VERSION ""

NS_ :

BS_:

BU_: PKP_PRND_Keypad HVAC Compressor_HPP DCDC_Inmotion_DC2 SME VCCU SME_4 SME_3 SME_2 SME_1 Diag_Tester BMS DCDC_inmotion_DC1 TCU Praker_GW OBC_Dilong DCDC_Dilong VCU

BO_ 2566861442 VCVCCU_V2G_RemainTimeToBulkSOC: 5 VCU
 SG_ RemainingTimeToBulkSOCFlag : 32|8@1+ (1,0) [0|255] "" Vector__XXX
 SG_ RemainingTimeToBulkSOC_Value : 24|8@1- (1,0) [-128|127] "" Vector__XXX
 SG_ RemainTimeToBulkSOC_UnitFlag : 16|8@1+ (1,0) [0|255] "" Vector__XXX
 SG_ RemainingTimeToBulkSOC_Unit : 8|4@1+ (1,0) [0|15] "" Vector__XXX
 SG_ RemainTimeToBulkSOC_Multiplier : 0|8@1- (1,0) [-128|127] "" Vector__XXX

BO_ 2566873730 VCVCCU_LIN_EvStatus: 5 VCU
 SG_ LIN_EvRequestedCurrentL1 : 32|8@1+ (1,0) [0|255] "A" Vector__XXX
 SG_ LIN_EvRequestedCurrentL3 : 24|8@1+ (1,0) [0|255] "A" Vector__XXX
 SG_ LIN_EvRequestedCurrentL2 : 16|8@1+ (1,0) [0|255] "A" Vector__XXX
 SG_ LIN_EvRequestedCurrentL1 : 8|8@1+ (1,0) [0|255] "A" Vector__XXX
 SG_ LIN_EvAwake : 0|1@1+ (1,0) [0|1] "" Vector__XXX

BO_ 2566873986 VCVCCU_LIN_EvPresentCurrentList: 4 VCU
 SG_ LIN_EvPresentCurrentN : 24|8@1+ (1,0) [0|255] "A" Vector__XXX
 SG_ LIN_EvPresentCurrentL3 : 16|8@1+ (1,0) [0|255] "A" Vector__XXX
 SG_ LIN_EvPresentCurrentL2 : 8|8@1+ (1,0) [0|255] "A" Vector__XXX
 SG_ LIN_EvPresentCurrentL1 : 0|8@1+ (1,0) [0|255] "A" Vector__XXX

BO_ 2566875010 VCVCCU_LIN_EvMinVoltageList: 4 VCU
 SG_ LIN_EvMinVoltageL1N : 16|16@1+ (0.1,0) [0|6553.5] "V" Vector__XXX
 SG_ LIN_EvMinVoltageL1N : 0|16@1+ (0.1,0) [0|6553.5] "V" Vector__XXX

BO_ 2566874754 VCVCCU_LIN_EvMaxVoltageList: 5 VCU
 SG_ LIN_EvMaxVoltageLL : 24|16@1+ (0.1,0) [0|6553.5] "V" Vector__XXX
 SG_ LIN_EvMaxVoltageL1N : 8|16@1+ (0.1,0) [0|6553.5] "V" Vector__XXX
 SG_ LIN_EvFrequencies : 0|8@1+ (1,0) [0|255] "" Vector__XXX

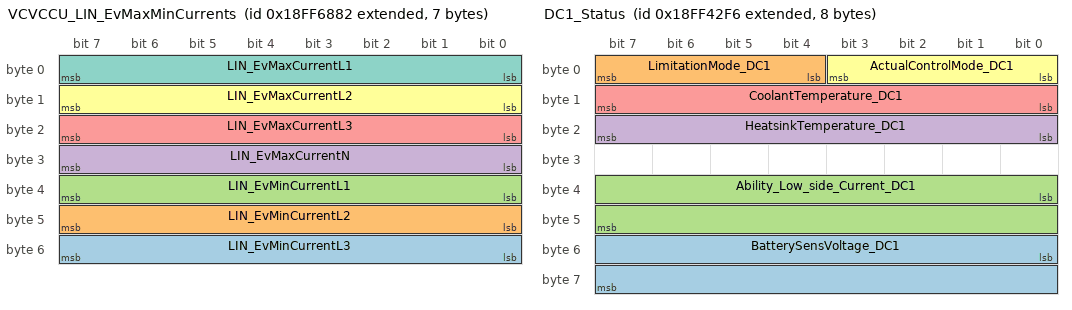
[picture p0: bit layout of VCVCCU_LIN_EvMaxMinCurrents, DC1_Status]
BO_ 2566875266 VCVCCU_LIN_EvMaxMinCurrents: 7 VCU
 SG_ LIN_EvMinCurrentL3 : 48|8@1+ (1,0) [0|255] "A" Vector__XXX
 SG_ LIN_EvMinCurrentL2 : 40|8@1+ (1,0) [0|255] "A" Vector__XXX
 SG_ LIN_EvMinCurrentL1 : 32|8@1+ (1,0) [0|255] "A" Vector__XXX
 SG_ LIN_EvMaxCurrentN : 24|8@1+ (1,0) [0|255] "A" Vector__XXX
 SG_ LIN_EvMaxCurrentL3 : 16|8@1+ (1,0) [0|255] "A" Vector__XXX
 SG_ LIN_EvMaxCurrentL2 : 8|8@1+ (1,0) [0|255] "A" Vector__XXX
 SG_ LIN_EvMaxCurrentL1 : 0|8@1+ (1,0) [0|255] "A" Vector__XXX

BO_ 2363117696 DIAG_RESP_VCVCCU: 8 VCCU
 SG_ DIAG_RESP_VCVCCU : 0|64@1+ (1,0) [0|1.84467440737096E+019] "" Vector__XXX

BO_ 2363129986 DIAG_REQ_VCVCCU: 8 VCU
 SG_ DIAG_REQ_VCVCCU : 0|64@1+ (1,0) [0|1.84467440737096E+019] "" Vector__XXX

BO_ 2363228034 DIAG_REQ_GLOBAL: 8 VCU
 SG_ DIAG_REQ_GLOBAL : 0|64@1+ (1,0) [0|1.84467440737096E+019] "" Vector__XXX

BO_ 2566865654 DC1_Status: 8 DCDC_inmotion_DC1
 SG_ BatterySensVoltage_DC1 : 48|16@1+ (0.05,0) [0|3212.7] "volts" Vector__XXX
 SG_ LimitationMode_DC1 : 4|4@1+ (1,0) [0|15] "" Vector__XXX
 SG_ Ability_Low_side_Current_DC1 : 32|16@1+ (0.05,-1600) [-1600|1612.75] "A" Vector__XXX
 SG_ HeatsinkTemperature_DC1 : 16|8@1+ (1,-40) [-40|209] "deg. Cel" Vector__XXX
 SG_ CoolantTemperature_DC1 : 8|8@1+ (1,-40) [-40|209] "Deg cel" Vector__XXX
 SG_ ActualControlMode_DC1 : 0|4@1+ (1,0) [0|0] "" Vector__XXX

BO_ 2566865398 DC1_Actual_Message: 8 DCDC_inmotion_DC1
 SG_ ActualHighsideCurrent_DC1 : 48|16@1+ (0.05,-1600) [-1600|1612.75] "Amps" Vector__XXX
 SG_ ActualHighsideVoltage_DC1 : 32|16@1+ (0.05,0) [0|3212.75] "volts" Vector__XXX
 SG_ ActualLowsideCurrent_DC1 : 16|16@1+ (0.05,-1600) [-1600|1612.75] "Amps" Vector__XXX
 SG_ ActualLowsideVoltage_DC1 : 0|16@1+ (0.05,0) [0|3212.75] "volts" Vector__XXX

BO_ 2566866174 DCDC_Faults_Inmotion: 8 DCDC_Inmotion_DC2
 SG_ WarningBit_31 : 63|1@1+ (1,0) [0|1] "" Vector__XXX
 SG_ WarningBit_30 : 62|1@1+ (1,0) [0|1] "" Vector__XXX
 SG_ WarningBit_29 : 61|1@1+ (1,0) [0|1] "" Vector__XXX
 SG_ WarningBit_28 : 60|1@1+ (1,0) [0|1] "" Vector__XXX
 SG_ WarningBit_27 : 59|1@1+ (1,0) [0|1] "" Vector__XXX
 SG_ WarningBit_26 : 58|1@1+ (1,0) [0|1] "" Vector__XXX
 SG_ WarningBit_25 : 57|1@1+ (1,0) [0|1] "" Vector__XXX
 SG_ WarningBit_24 : 56|1@1+ (1,0) [0|1] "" Vector__XXX
 SG_ WarningBit_23 : 55|1@1+ (1,0) [0|1] "" Vector__XXX
 SG_ WarningBit_22 : 54|1@1+ (1,0) [0|1] "" Vector__XXX
 SG_ WarningBit_21 : 53|1@1+ (1,0) [0|1] "" Vector__XXX
 SG_ WarningBit_20 : 52|1@1+ (1,0) [0|1] "" Vector__XXX
 SG_ WarningBit_19 : 51|1@1+ (1,0) [0|1] "" Vector__XXX
 SG_ WarningBit_18 : 50|1@1+ (1,0) [0|1] "" Vector__XXX
 SG_ WarningBit_17 : 49|1@1+ (1,0) [0|1] "" Vector__XXX
 SG_ WarningBit_16 : 48|1@1+ (1,0) [0|1] "" Vector__XXX
 SG_ WarningBit_15 : 47|1@1+ (1,0) [0|1] "" Vector__XXX
 SG_ WarningBit_14 : 46|1@1+ (1,0) [0|1] "" Vector__XXX
 SG_ WarningBit_13 : 45|1@1+ (1,0) [0|1] "" Vector__XXX
 SG_ WarningBit_12 : 44|1@1+ (1,0) [0|1] "" Vector__XXX
 SG_ WarningBit_11 : 43|1@1+ (1,0) [0|1] "" Vector__XXX
 SG_ WarningBit_10 : 42|1@1+ (1,0) [0|1] "" Vector__XXX
 SG_ WarningBit_09 : 41|1@1+ (1,0) [0|1] "" Vector__XXX
 SG_ WarningBit_08 : 40|1@1+ (1,0) [0|1] "" Vector__XXX
 SG_ WarningBit_07 : 39|1@1+ (1,0) [0|1] "" Vector__XXX
 SG_ WarningBit_06 : 38|1@1+ (1,0) [0|1] "" Vector__XXX
 SG_ WarningBit_05 : 37|1@1+ (1,0) [0|1] "" Vector__XXX
 SG_ WarningBit_04 : 36|1@1+ (1,0) [0|1] "" Vector__XXX
 SG_ WarningBit_03 : 35|1@1+ (1,0) [0|1] "" Vector__XXX
 SG_ WarningBit_02 : 34|1@1+ (1,0) [0|1] "" Vector__XXX
 SG_ WarningBit_01 : 33|1@1+ (1,0) [0|1] "" Vector__XXX
 SG_ WarningBit_00 : 32|1@1+ (1,0) [0|1] "" Vector__XXX
 SG_ ErrorBit_31 : 31|1@1+ (1,0) [0|1] "" Vector__XXX
 SG_ ErrorBit_30 : 30|1@1+ (1,0) [0|1] "" Vector__XXX
 SG_ ErrorBit_29 : 29|1@1+ (1,0) [0|1] "" Vector__XXX
 SG_ ErrorBit_28 : 28|1@1+ (1,0) [0|1] "" Vector__XXX
 SG_ ErrorBit_27 : 27|1@1+ (1,0) [0|1] "" Vector__XXX
 SG_ ErrorBit_26 : 26|1@1+ (1,0) [0|1] "" Vector__XXX
 SG_ ErrorBit_25 : 25|1@1+ (1,0) [0|1] "" Vector__XXX
 SG_ ErrorBit_24 : 24|1@1+ (1,0) [0|1] "" Vector__XXX
 SG_ ErrorBit_23 : 23|1@1+ (1,0) [0|1] "" Vector__XXX
 SG_ ErrorBit_22 : 22|1@1+ (1,0) [0|1] "" Vector__XXX
 SG_ ErrorBit_21 : 21|1@1+ (1,0) [0|1] "" Vector__XXX
 SG_ ErrorBit_20 : 20|1@1+ (1,0) [0|1] "" Vector__XXX
 SG_ ErrorBit_19 : 19|1@1+ (1,0) [0|1] "" Vector__XXX
 SG_ ErrorBit_18 : 18|1@1+ (1,0) [0|1] "" Vector__XXX
 SG_ ErrorBit_17 : 17|1@1+ (1,0) [0|1] "" Vector__XXX
 SG_ ErrorBit_16 : 16|1@1+ (1,0) [0|1] "" Vector__XXX
 SG_ ErrorBit_15 : 15|1@1+ (1,0) [0|1] "" Vector__XXX
 SG_ ErrorBit_14 : 14|1@1+ (1,0) [0|1] "" Vector__XXX
 SG_ ErrorBit_13 : 13|1@1+ (1,0) [0|1] "" Vector__XXX
 SG_ ErrorBit_12 : 12|1@1+ (1,0) [0|1] "" Vector__XXX
 SG_ ErrorBit_11 : 11|1@1+ (1,0) [0|1] "" Vector__XXX
 SG_ ErrorBit_10 : 10|1@1+ (1,0) [0|1] "" Vector__XXX
 SG_ ErrorBit_09 : 9|1@1+ (1,0) [0|1] "" Vector__XXX
 SG_ ErrorBit_08 : 8|1@1+ (1,0) [0|1] "" Vector__XXX
 SG_ ErrorBit_07 : 7|1@1+ (1,0) [0|1] "" Vector__XXX
 SG_ ErrorBit_06 : 6|1@1+ (1,0) [0|1] "" Vector__XXX
 SG_ ErrorBit_05 : 5|1@1+ (1,0) [0|1] "" Vector__XXX
 SG_ ErrorBit_04 : 4|1@1+ (1,0) [0|1] "" Vector__XXX
 SG_ ErrorBit_03 : 3|1@1+ (1,0) [0|1] "" Vector__XXX
 SG_ ErrorBit_02 : 2|1@1+ (1,0) [0|1] "" Vector__XXX
 SG_ ErrorBit_01 : 1|1@1+ (1,0) [0|1] "" Vector__XXX
 SG_ ErrorBit_00 : 0|1@1+ (1,0) [0|1] "" Vector__XXX

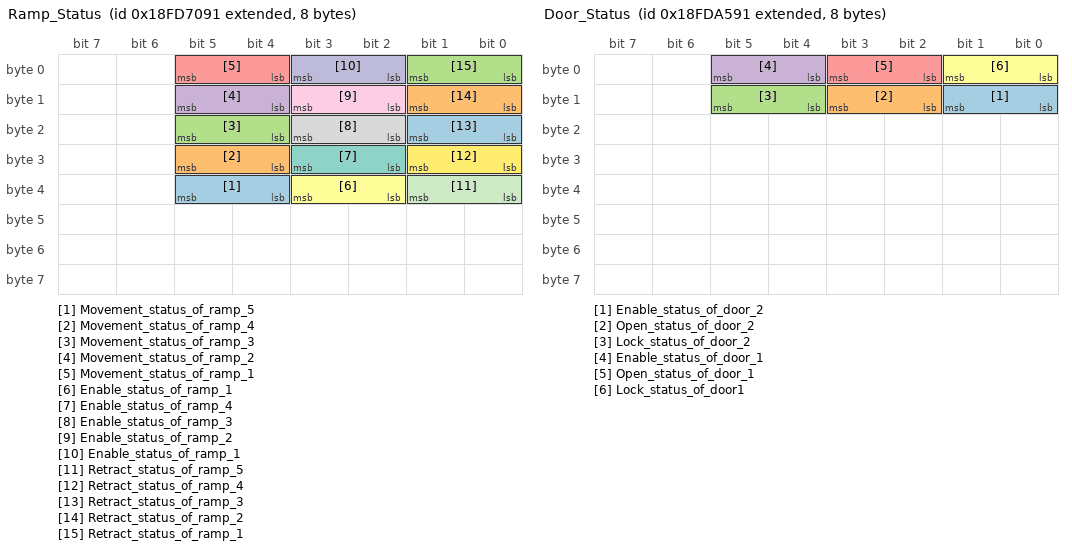
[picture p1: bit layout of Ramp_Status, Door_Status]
BO_ 2566746257 Ramp_Status: 8 Praker_GW
 SG_ Movement_status_of_ramp_5 : 36|2@1+ (1,0) [0|3] "" Vector__XXX
 SG_ Movement_status_of_ramp_4 : 28|2@1+ (1,0) [0|3] "" Vector__XXX
 SG_ Movement_status_of_ramp_3 : 20|2@1+ (1,0) [0|3] "" Vector__XXX
 SG_ Movement_status_of_ramp_2 : 12|2@1+ (1,0) [0|3] "" Vector__XXX
 SG_ Movement_status_of_ramp_1 : 4|2@1+ (1,0) [0|3] "" Vector__XXX
 SG_ Enable_status_of_ramp_1 : 34|2@1+ (1,0) [0|3] "" Vector__XXX
 SG_ Enable_status_of_ramp_4 : 26|2@1+ (1,0) [0|3] "" Vector__XXX
 SG_ Enable_status_of_ramp_3 : 18|2@1+ (1,0) [0|3] "" Vector__XXX
 SG_ Enable_status_of_ramp_2 : 10|2@1+ (1,0) [0|3] "" Vector__XXX
 SG_ Enable_status_of_ramp_1 : 2|2@1+ (1,0) [0|3] "" Vector__XXX
 SG_ Retract_status_of_ramp_5 : 32|2@1+ (1,0) [0|3] "" Vector__XXX
 SG_ Retract_status_of_ramp_4 : 24|2@1+ (1,0) [0|3] "" Vector__XXX
 SG_ Retract_status_of_ramp_3 : 16|2@1+ (1,0) [0|3] "" Vector__XXX
 SG_ Retract_status_of_ramp_2 : 8|2@1+ (1,0) [0|3] "" Vector__XXX
 SG_ Retract_status_of_ramp_1 : 0|2@1+ (1,0) [0|3] "" Vector__XXX

BO_ 2566759825 Door_Status: 8 Praker_GW
 SG_ Enable_status_of_door_2 : 8|2@1+ (1,0) [0|3] "" Vector__XXX
 SG_ Open_status_of_door_2 : 10|2@1+ (1,0) [0|3] "" Vector__XXX
 SG_ Lock_status_of_door_2 : 12|2@1+ (1,0) [0|3] "" Vector__XXX
 SG_ Enable_status_of_door_1 : 4|2@1+ (1,0) [0|3] "" Vector__XXX
 SG_ Open_status_of_door_1 : 2|2@1+ (1,0) [0|3] "" Vector__XXX
 SG_ Lock_status_of_door1 : 0|2@1+ (1,0) [0|3] "" Vector__XXX

BO_ 2365449873 Hydraulic_Brakes: 8 Praker_GW
 SG_ HydraulicBrakeFluidLevelSwitch : 0|2@1+ (1,0) [0|3] "" Vector__XXX

BO_ 2566906513 Parker_GM_amb_Temp: 8 Praker_GW
 SG_ Ambient_Temperature : 0|8@1+ (1,-40) [0|125] "" Vector__XXX

BO_ 2550588916 BMS_Charge_Clear_MSG: 8 VCU
 SG_ Mode : 40|8@1+ (1,0) [0|255] "" Vector__XXX
 SG_ BMS_Control : 32|8@1+ (1,0) [0|255] "" Vector__XXX
 SG_ Set_Current : 23|16@0+ (0.1,0) [0|6553.5] "Amps" Vector__XXX
 SG_ Set_voltage : 7|16@0+ (0.1,0) [0|6553.5] "Volts" Vector__XXX

BO_ 2349399888 VCU_Errors: 8 VCU
 SG_ MCU_rotor_over_temp : 48|2@1+ (1,0) [0|3] "" Vector__XXX
 SG_ MCU_regen_type_Error : 50|2@1+ (1,0) [0|3] "" Vector__XXX
 SG_ MCU_inverter_fault : 46|2@1+ (1,0) [0|3] "" Vector__XXX
 SG_ MCU_stator_over_temp : 44|2@1+ (1,0) [0|255] "" Vector__XXX
 SG_ MCU_inverter_over_temp : 42|2@1+ (1,0) [0|3] "" Vector__XXX
 SG_ MCU_over_speed_Warning : 40|2@1+ (1,0) [0|3] "" Vector__XXX
 SG_ MCU_over_speed_alarm : 38|2@1+ (1,0) [0|3] "" Vector__XXX
 SG_ MCU_undervoltage_alarm : 36|2@1+ (1,0) [0|3] "" Vector__XXX
 SG_ MCU_overvoltage_alarm : 34|2@1+ (1,0) [0|3] "" Vector__XXX
 SG_ MCU_limp_home_mode : 32|2@1+ (1,0) [0|3] "" Vector__XXX
 SG_ Transmission_Temp_Read_Error : 10|2@1+ (1,0) [0|3] "" Vector__XXX
 SG_ Transmission_Temperature_Limit : 8|2@1+ (1,0) [0|3] "" Vector__XXX
 SG_ Transmission_Temperature_Error : 6|2@1+ (1,0) [0|3] "" Vector__XXX
 SG_ Transmission_Temperature_Warning : 4|2@1+ (1,0) [0|3] "" Vector__XXX
 SG_ TCU_cmd_MSG_2_watchdog_timeout : 2|2@1+ (1,0) [0|3] "" Vector__XXX
 SG_ TCU_cmd_MSG_1_watchdog_timeout : 0|2@1+ (1,0) [0|3] "" Vector__XXX
 SG_ CAT3_RQ_SER_HVSTO : 20|2@1+ (1,0) [0|3] "" Vector__XXX
 SG_ CAT7_RQ_OPN_DCSW_HVSTO_ILY : 28|2@1+ (1,0) [0|3] "" Vector__XXX
 SG_ CAT6_RQ_OPN_DCSW_HVSTO_FAST : 26|2@1+ (1,0) [0|3] "" Vector__XXX
 SG_ CAT5_RQ_OPN_CHG_HVSTO : 24|2@1+ (1,0) [0|3] "" Vector__XXX
 SG_ CAT4_ERR_EMMOD_HVSTO : 22|2@1+ (1,0) [0|3] "" Vector__XXX
 SG_ CAT1_ST_PRCHRG_LOKD_HVSTO : 16|2@1+ (1,0) [0|3] "" Vector__XXX

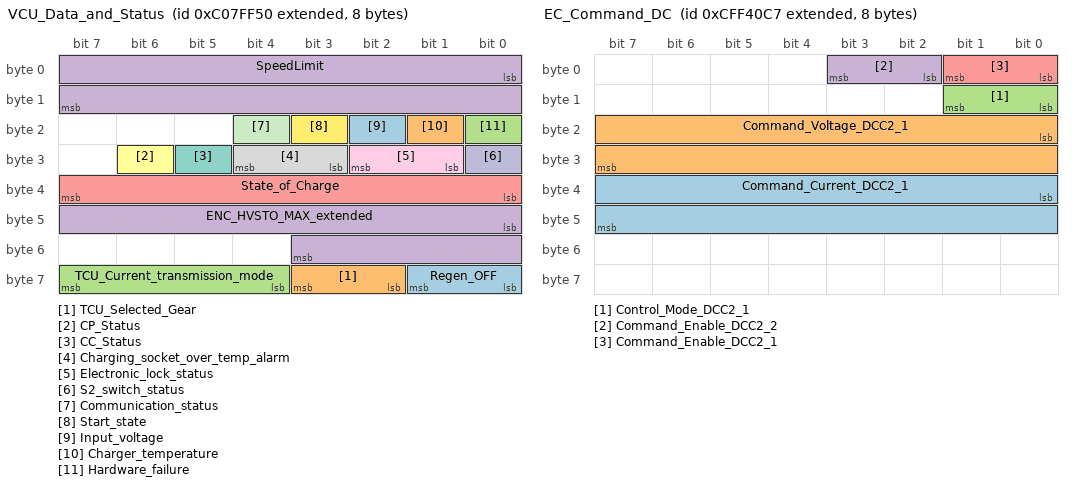
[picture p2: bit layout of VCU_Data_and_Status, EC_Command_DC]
BO_ 2349334352 VCU_Data_and_Status: 8 VCU
 SG_ Regen_OFF : 56|2@1+ (1,0) [0|3] "" Vector__XXX
 SG_ TCU_Selected_Gear : 58|2@1+ (1,0) [0|3] "Enumeration" Vector__XXX
 SG_ TCU_Current_transmission_mode : 60|4@1+ (1,0) [0|6] "Enumerated" Vector__XXX
 SG_ ENC_HVSTO_MAX_extended : 40|12@1+ (0.15,0) [0|614.1] "Kwh" Vector__XXX
 SG_ State_of_Charge : 32|8@1+ (1,0) [0|100] "%" Vector__XXX
 SG_ CP_Status : 30|1@1+ (1,0) [0|1] "" Vector__XXX
 SG_ CC_Status : 29|1@1+ (1,0) [0|1] "" Vector__XXX
 SG_ Charging_socket_over_temp_alarm : 27|2@1+ (1,0) [0|3] "" Vector__XXX
 SG_ Electronic_lock_status : 25|2@1+ (1,0) [0|3] "" Vector__XXX
 SG_ S2_switch_status : 24|1@1+ (1,0) [0|1] "" Vector__XXX
 SG_ Communication_status : 20|1@1+ (1,0) [0|1] "" Vector__XXX
 SG_ Start_state : 19|1@1+ (1,0) [0|1] "" Vector__XXX
 SG_ Input_voltage : 18|1@1+ (1,0) [0|1] "" Vector__XXX
 SG_ Charger_temperature : 17|1@1+ (1,0) [0|1] "" Vector__XXX
 SG_ Hardware_failure : 16|1@1+ (1,0) [0|1] "" Vector__XXX
 SG_ SpeedLimit : 0|16@1+ (1,0) [0|4800] "rpm" Vector__XXX

BO_ 2365538503 EC_Command_DC: 8 VCU
 SG_ Command_Current_DCC2_1 : 32|16@1+ (0.05,-1600) [-1600|1612.75] "" Vector__XXX
 SG_ Command_Voltage_DCC2_1 : 16|16@1+ (0.05,0) [0|3212.75] "" Vector__XXX
 SG_ Control_Mode_DCC2_1 : 8|2@1+ (1,0) [0|3] "" Vector__XXX
 SG_ Command_Enable_DCC2_2 : 2|2@1+ (1,0) [0|3] "" Vector__XXX
 SG_ Command_Enable_DCC2_1 : 0|2@1+ (1,0) [0|3] "" Vector__XXX

BO_ 2566863234 VCVCCU_V2G_EVMaximumVoltageLimit: 8 VCU
 SG_ V2G_EVMaxvoltagelimit_Unitflag : 32|8@1+ (1,0) [0|255] "" Vector__XXX
 SG_ V2G_EVMaximumvoltagelimit_Value : 16|16@1- (1,0) [-32768|32767] "" Vector__XXX
 SG_ V2G_EVMaxvoltagelimit_Multiplier : 8|8@1- (1,0) [-128|127] "" Vector__XXX
 SG_ V2G_EVMaximumvoltagelimit_Flag : 4|2@1+ (1,0) [0|3] "" Vector__XXX
 SG_ V2G_EVMaximumvoltagelimit_Unit : 0|4@1+ (1,0) [0|15] "" Vector__XXX

BO_ 2566862978 VCVCCU_V2G_EVMaximumPowerLimit: 6 VCU
 SG_ V2G_EVMaximumpowerlimit_Unitflag : 40|8@1+ (1,0) [0|255] "" Vector__XXX
 SG_ V2G_EVMaximumpowerlimit_Value : 24|16@1- (1,0) [-32768|32767] "" Vector__XXX
 SG_ V2G_EVMaxpowerlimit_Multiplier : 16|8@1- (1,0) [-128|127] "" Vector__XXX
 SG_ V2G_EVMaximumpowerlimit_Flag : 8|2@1+ (1,0) [0|3] "" Vector__XXX
 SG_ V2G_EVMaximumpowerlimit_Unit : 0|4@1+ (1,0) [0|15] "" Vector__XXX

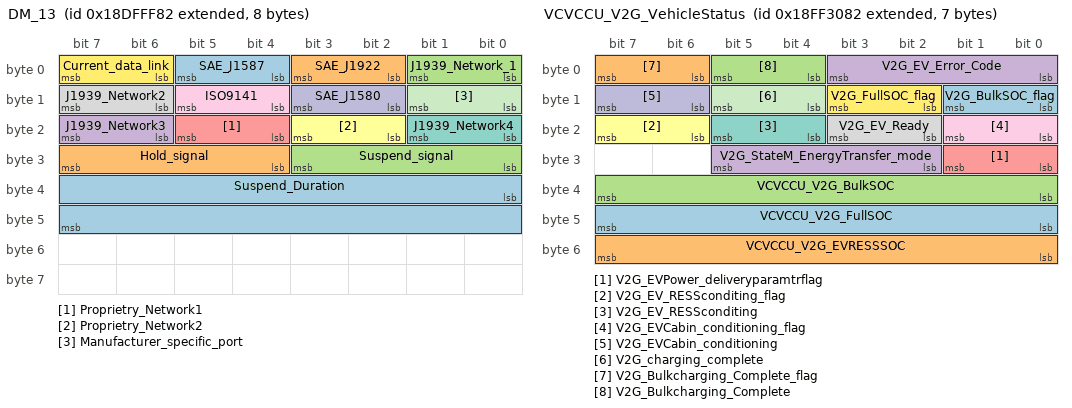
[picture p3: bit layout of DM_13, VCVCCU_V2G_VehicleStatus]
BO_ 2564816770 DM_13: 8 VCU
 SG_ Suspend_Duration : 32|16@1+ (1,0) [0|64255] "s" Vector__XXX
 SG_ Hold_signal : 28|4@1+ (1,0) [0|15] "" Vector__XXX
 SG_ Suspend_signal : 24|4@1+ (1,0) [0|15] "" Vector__XXX
 SG_ J1939_Network3 : 22|2@1+ (1,0) [0|3] "" Vector__XXX
 SG_ Proprietry_Network1 : 20|2@1+ (1,0) [0|3] "" Vector__XXX
 SG_ Proprietry_Network2 : 18|2@1+ (1,0) [0|3] "" Vector__XXX
 SG_ J1939_Network4 : 16|2@1+ (1,0) [0|3] "" Vector__XXX
 SG_ J1939_Network2 : 14|2@1+ (1,0) [0|3] "" Vector__XXX
 SG_ ISO9141 : 12|2@1+ (1,0) [0|3] "" Vector__XXX
 SG_ SAE_J1580 : 10|2@1+ (1,0) [0|3] "" Vector__XXX
 SG_ Manufacturer_specific_port : 8|2@1+ (1,0) [0|3] "" Vector__XXX
 SG_ Current_data_link : 6|2@1+ (1,0) [0|3] "" Vector__XXX
 SG_ SAE_J1587 : 4|2@1+ (1,0) [0|3] "" Vector__XXX
 SG_ SAE_J1922 : 2|2@1+ (1,0) [0|3] "" Vector__XXX
 SG_ J1939_Network_1 : 0|2@1+ (1,0) [0|3] "" Vector__XXX

BO_ 2633990274 NM_CGW: 8 VCU
 SG_ Wakeup_RSN_CGW : 8|8@1+ (1,0) [0|255] "" Vector__XXX

BO_ 2566860930 VCVCCU_V2G_VehicleStatus: 7 VCU
 SG_ VCVCCU_V2G_FullSOC : 40|8@1- (1,0) [-128|127] "" Vector__XXX
 SG_ VCVCCU_V2G_EVRESSSOC : 48|8@1- (1,0) [-128|127] "" Vector__XXX
 SG_ VCVCCU_V2G_BulkSOC : 32|8@1- (1,0) [-128|127] "" Vector__XXX
 SG_ V2G_StateM_EnergyTransfer_mode : 26|4@1+ (1,0) [0|15] "" Vector__XXX
 SG_ V2G_EVPower_deliveryparamtrflag : 24|2@1+ (1,0) [0|3] "" Vector__XXX
 SG_ V2G_EV_RESSconditing_flag : 22|2@1+ (1,0) [0|3] "" Vector__XXX
 SG_ V2G_EV_RESSconditing : 20|2@1+ (1,0) [0|3] "" Vector__XXX
 SG_ V2G_EV_Ready : 18|2@1+ (1,0) [0|3] "" Vector__XXX
 SG_ V2G_EVCabin_conditioning_flag : 16|2@1+ (1,0) [0|3] "" Vector__XXX
 SG_ V2G_EVCabin_conditioning : 14|2@1+ (1,0) [0|3] "" Vector__XXX
 SG_ V2G_charging_complete : 12|2@1+ (1,0) [0|3] "" Vector__XXX
 SG_ V2G_FullSOC_flag : 10|2@1+ (1,0) [0|3] "" Vector__XXX
 SG_ V2G_BulkSOC_flag : 8|2@1+ (1,0) [0|3] "" Vector__XXX
 SG_ V2G_Bulkcharging_Complete_flag : 6|2@1+ (1,0) [0|3] "" Vector__XXX
 SG_ V2G_Bulkcharging_Complete : 4|2@1+ (1,0) [0|3] "" Vector__XXX
 SG_ V2G_EV_Error_Code : 0|4@1+ (1,0) [0|15] "" Vector__XXX

BO_ 2566861186 VCVCCU_V2G_RemainiTmeToFulSOC: 5 VCU
 SG_ VCVCCU_V2G_RemainTmeToFulSOC_Flg : 36|2@1+ (1,0) [0|3] "" Vector__XXX
 SG_ VCVCCU_V2G_RemainTimeToFulSOCuni : 32|4@1+ (1,0) [0|15] "" Vector__XXX
 SG_ V2G_RemnTimeToFulSOC_Unitflag : 24|8@1+ (1,0) [0|255] "" Vector__XXX
 SG_ VCVCCU_V2G_ReminTimeToFulSOC_Mul : 16|8@1- (1,0) [-128|127] "" Vector__XXX
 SG_ VCVCCU_V2G_ReminTimeToFulSOC_Val : 0|16@1- (1,0) [-32768|32767] "" Vector__XXX

BO_ 2566861698 VCVCCU_V2G_EVTargetVoltage: 5 VCU
 SG_ V2G_EVTargetVoltage_Unit : 32|2@1+ (1,0) [0|3] "" Vector__XXX
 SG_ V2G_EVTargetVoltage_Unit_Flag : 24|8@1+ (1,0) [0|255] "" Vector__XXX
 SG_ V2G_EVTargetVoltage_Multiplier : 16|8@1- (1,0) [-128|127] "" Vector__XXX
 SG_ V2G_EVTargetVoltage_Value : 0|16@1- (1,0) [-32768|32767] "" Vector__XXX

BO_ 2566861954 VCVCCU_V2G_EVTargetCurrent: 5 VCU
 SG_ V2G_EVTargetCurrent_Unit : 32|4@1+ (1,0) [0|15] "" Vector__XXX
 SG_ V2G_EVTargetCurrent_Unit_Flag : 24|8@1+ (1,0) [0|255] "" Vector__XXX
 SG_ V2G_EVTargetCurrent_Multiplier : 16|8@1- (1,0) [-128|127] "" Vector__XXX
 SG_ V2G_EVTargetCurrent_Value : 0|16@1- (1,0) [-32768|32767] "" Vector__XXX

BO_ 2566862722 VCVCCU_V2G_EVMaximumCurrentLimit: 5 VCU
 SG_ V2G_EVMaxcurrentlimit_Unitflag : 32|8@1+ (1,0) [0|255] "" Vector__XXX
 SG_ V2G_EVMaximumcurrentlimit_Value : 16|16@1- (1,0) [-32768|32767] "" Vector__XXX
 SG_ V2G_EVMaxcurrentlimit_Multiplier : 8|8@1- (1,0) [-128|127] "" Vector__XXX
 SG_ V2G_EVMaximumcurrentlimit_Flag : 4|2@1+ (1,0) [0|3] "" Vector__XXX
 SG_ V2G_EVMaximumcurrentlimit_Unit : 0|4@1+ (1,0) [0|15] "" Vector__XXX

BO_ 2566862466 VCVCCU_V2G_EVEnergyRequest: 8 VCU
 SG_ V2G_EVEnergyRequest_Value : 32|16@1- (1,0) [-32768|32767] "" Vector__XXX
 SG_ V2G_EVEnergyRequest_Unitflag : 24|8@1+ (1,0) [0|255] "" Vector__XXX
 SG_ V2G_EVEnergyRequest_Multiplier : 16|8@1- (1,0) [-128|127] "" Vector__XXX
 SG_ V2G_EVEnergyRequest_flag : 8|2@1+ (1,0) [0|3] "" Vector__XXX
 SG_ V2G_EVEnergyRequest_Unit : 0|4@1+ (1,0) [0|15] "" Vector__XXX

BO_ 2566862210 VCVCCU_V2G_EVEnergyCapacity: 8 VCU
 SG_ V2G_EVEnergyCapacity_Unitflag : 32|8@1+ (1,0) [0|255] "" Vector__XXX
 SG_ V2G_EVEnergyCapacity_Value : 16|16@1- (1,0) [-32768|32767] "" Vector__XXX
 SG_ V2G_EVEnergyCapacity_Multiplier : 8|8@1- (1,0) [-128|127] "" Vector__XXX
 SG_ V2G_EVEnergyCapacity_flag : 4|2@1+ (1,0) [0|3] "" Vector__XXX
 SG_ V2G_EVEnergyCapacity_Unit : 0|4@1+ (1,0) [0|15] "" Vector__XXX

BO_ 2566865026 VCVCCU_V2G_DepartureTime: 8 VCU
 SG_ V2G_Departuretime_flag : 32|8@1+ (1,0) [0|255] "" Vector__XXX
 SG_ V2G_Departuretime_Value : 0|32@1+ (1,0) [0|4294967295] "" Vector__XXX

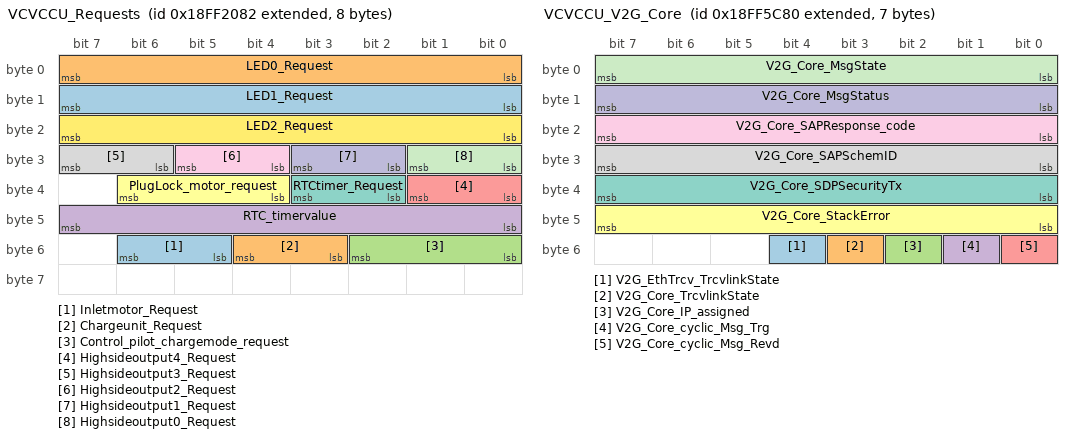
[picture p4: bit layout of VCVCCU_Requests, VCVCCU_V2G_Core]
BO_ 2566856834 VCVCCU_Requests: 8 VCU
 SG_ Inletmotor_Request : 53|2@1+ (1,0) [0|3] "" Vector__XXX
 SG_ Chargeunit_Request : 51|2@1+ (1,0) [0|3] "" Vector__XXX
 SG_ Control_pilot_chargemode_request : 48|3@1+ (1,0) [0|7] "7" Vector__XXX
 SG_ RTC_timervalue : 40|8@1+ (1,0) [0|254] "min" Vector__XXX
 SG_ Highsideoutput4_Request : 32|2@1+ (1,0) [0|3] "" Vector__XXX
 SG_ PlugLock_motor_request : 36|3@1+ (1,0) [0|7] "" Vector__XXX
 SG_ RTCtimer_Request : 34|2@1+ (1,0) [0|3] "" Vector__XXX
 SG_ Highsideoutput3_Request : 30|2@1+ (1,0) [0|3] "" Vector__XXX
 SG_ Highsideoutput2_Request : 28|2@1+ (1,0) [0|3] "" Vector__XXX
 SG_ Highsideoutput1_Request : 26|2@1+ (1,0) [0|3] "" Vector__XXX
 SG_ Highsideoutput0_Request : 24|2@1+ (1,0) [0|3] "" Vector__XXX
 SG_ LED2_Request : 16|8@1+ (0.5,0) [0|100] "%" Vector__XXX
 SG_ LED1_Request : 8|8@1+ (0.5,0) [0|100] "%" Vector__XXX
 SG_ LED0_Request : 0|8@1+ (0.5,0) [0|100] "%" Vector__XXX

BO_ 2566910080 XCP_RESP_VCVCCU: 8 VCCU
 SG_ XCP_RESP_VCCU : 0|64@1+ (1,0) [0|1.84467440737096E+019] "" Vector__XXX

BO_ 2566855552 VCVCCU_V2ICP_BackendToVehicle: 8 VCCU
 SG_ VCVCCU_V2ICP_AmbientTemperature : 24|8@1- (1,0) [-50|70] "Deg. Cel" Vector__XXX
 SG_ VCVCCU_V2ICP_PrecnditinigDesire : 16|8@1+ (1,0) [0|255] "" Vector__XXX
 SG_ VCVCCU_V2ICP_PrecndtnDesireHVAC : 8|8@1+ (1,0) [0|3] "" Vector__XXX
 SG_ VCVCCU_V2ICP_SchdulDepartureTime : 0|8@1+ (5,0) [0|1440] "min" Vector__XXX

BO_ 2566872192 VCVCCU_V2G_Core: 7 VCCU
 SG_ V2G_EthTrcv_TrcvlinkState : 52|1@1+ (1,0) [0|1] "" Vector__XXX
 SG_ V2G_Core_TrcvlinkState : 51|1@1+ (1,0) [0|1] "" Vector__XXX
 SG_ V2G_Core_IP_assigned : 50|1@1+ (1,0) [0|1] "" Vector__XXX
 SG_ V2G_Core_cyclic_Msg_Trg : 49|1@1+ (1,0) [0|1] "" Vector__XXX
 SG_ V2G_Core_cyclic_Msg_Revd : 48|1@1+ (1,0) [0|1] "" Vector__XXX
 SG_ V2G_Core_StackError : 40|8@1+ (1,0) [0|255] "" Vector__XXX
 SG_ V2G_Core_SDPSecurityTx : 32|8@1+ (1,0) [0|255] "" Vector__XXX
 SG_ V2G_Core_SAPSchemID : 24|8@1+ (1,0) [0|255] "" Vector__XXX
 SG_ V2G_Core_SAPResponse_code : 16|8@1+ (1,0) [0|255] "" Vector__XXX
 SG_ V2G_Core_MsgStatus : 8|8@1+ (1,0) [0|255] "" Vector__XXX
 SG_ V2G_Core_MsgState : 0|8@1+ (1,0) [0|255] "" Vector__XXX

BO_ 2566872960 VCVCCU_V2G_ChargingProfileNext: 3 VCCU
 SG_ VCVCCU_V2G_NextPMaxMultiplier : 16|8@1- (1,0) [-128|127] "" Vector__XXX
 SG_ VCVCCU_V2G_NextPMaxValue : 0|16@1- (1,0) [-32768|32767] "" Vector__XXX

BO_ 2566872704 VCVCCU_V2G_ChargingProfileCurr: 7 VCCU
 SG_ VCVCCU_V2G_CurrentPMaxDuration : 24|32@1+ (1,0) [0|4294967295] "" Vector__XXX
 SG_ VCVCCU_V2G_CurrentPMaxMultiplier : 16|8@1- (1,0) [-128|127] "" Vector__XXX
 SG_ VCVCCU_V2G_CurrentPMaxValue : 0|16@1- (1,0) [-32768|32767] "" Vector__XXX

BO_ 2566854272 VCVCCU_RTCStatus: 1 VCCU
 SG_ VCVCCU_RTC_Wakeup : 4|2@1+ (1,0) [0|3] "" Vector__XXX
 SG_ VCVCCU_RTC_TimerStatus : 0|2@1+ (1,0) [0|3] "" Vector__XXX

BO_ 2566853248 VCVCCU_PTC2: 7 VCCU
 SG_ VCVCCU_PTC2_SelfDiagnosticStatus : 48|3@1+ (1,0) [0|7] "" Vector__XXX
 SG_ VCVCCU_PTC2_Temperature : 32|16@1+ (1,-150) [-150|65383] "Deg. Cel" Vector__XXX
 SG_ VCVCCU_PTC2_Resistance : 16|16@1+ (1,0) [0|65533] "" Vector__XXX
 SG_ VCVCCU_PTC2_Raw : 0|16@1+ (1,0) [0|65533] "" Vector__XXX

BO_ 2566852992 VCVCCU_PTC1: 7 VCCU
 SG_ VCVCCU_PTC1_SelfDiagnosticStatus : 48|3@1+ (1,0) [0|7] "" Vector__XXX
 SG_ VCVCCU_PTC1_Temperature : 32|16@1+ (1,-150) [-150|65383] "deg. Cel" Vector__XXX
 SG_ VCVCCU_PTC1_Resistance : 16|16@1+ (1,0) [0|65533] "Ohm" Vector__XXX
 SG_ VCVCCU_PTC1_Raw : 0|16@1+ (1,0) [0|65533] "" Vector__XXX

BO_ 2566852736 VCVCCU_PTC0: 7 VCCU
 SG_ VCVCCU_PTC0_SelfDiagnosticStatus : 48|3@1+ (1,0) [0|7] "" Vector__XXX
 SG_ VCVCCU_PTC0_Temperature : 32|16@1+ (1,-150) [-150|65383] "Deg. Cel" Vector__XXX
 SG_ VCVCCU_PTC0_Resistance : 16|16@1+ (1,0) [0|65533] "Ohm" Vector__XXX
 SG_ VCVCCU_PTC0_Raw : 0|16@1+ (1,0) [0|65533] "" Vector__XXX

BO_ 2566854016 VCVCCU_OutputStatus: 7 VCCU
 SG_ VCVCCU_HighSideOut4_Input_Status : 54|2@1+ (1,0) [0|3] "" Vector__XXX
 SG_ VCVCCU_HighSideOut3_Input_Wakeup : 52|2@1+ (1,0) [0|3] "" Vector__XXX
 SG_ VCVCCU_HghSdeOut4_Ip_DebonceStat : 48|2@1+ (1,0) [0|3] "" Vector__XXX
 SG_ VCVCCU_HighSideOut3_Input_Status : 46|2@1+ (1,0) [0|3] "" Vector__XXX
 SG_ VCVCCU_HghSdeOut3_Ip_DebuncStats : 44|2@1+ (1,0) [0|3] "" Vector__XXX
 SG_ VCVCCU_HighSideOut2_Input_Status : 42|2@1+ (1,0) [0|3] "" Vector__XXX
 SG_ VCVCCU_HghSdeOut2_Ip_DebuncStats : 40|2@1+ (1,0) [0|3] "" Vector__XXX
 SG_ VCVCCU_HighSideOut1_Input_Status : 38|2@1+ (1,0) [0|3] "" Vector__XXX
 SG_ VCVCCU_HghsdeOut1_Ip_DebunceStat : 36|2@1+ (1,0) [0|3] "" Vector__XXX
 SG_ VCVCCU_HighSideOut0_Ip_Stats : 34|2@1+ (1,0) [0|3] "" Vector__XXX
 SG_ VCVCCU_HghSdeOut0_Ip_DeboncStats : 32|2@1+ (1,0) [0|3] "" Vector__XXX
 SG_ VCVCCU_LED2_SelfDiagnosticStatus : 28|3@1+ (1,0) [0|7] "" Vector__XXX
 SG_ VCVCCU_LED1_SelfDiagnosticStatus : 24|3@1+ (1,0) [0|7] "" Vector__XXX
 SG_ VCVCCU_LED0_SelfDiagStatus : 20|3@1+ (1,0) [0|7] "" Vector__XXX
 SG_ VCVCCU_HghSdeOut4_SelfDiagStatus : 16|3@1+ (1,0) [0|7] "" Vector__XXX
 SG_ VCVCCU_HghSdeOut3_SelfDiagStatus : 12|3@1+ (1,0) [0|7] "" Vector__XXX
 SG_ VCVCCU_HghSdeOut2_SelfDiagStatus : 8|3@1+ (1,0) [0|7] "" Vector__XXX
 SG_ VCVCCU_HghSdeOut1_SelfDiagStatus : 4|3@1+ (1,0) [0|7] "" Vector__XXX
 SG_ VCVCCU_HghSieOut0_SelfDiagStatus : 0|3@1+ (1,0) [0|7] "" Vector__XXX

BO_ 2566873472 VCVCCU_LIN_SeStatus: 8 VCCU
 SG_ LIN_SeAvailableCurrentL1 : 40|8@1+ (1,0) [0|255] "A" Vector__XXX
 SG_ LIN_SeAvailableCurrentN : 16|8@1+ (1,0) [0|255] "A" Vector__XXX
 SG_ LIN_SeAvailableCurrentL3 : 32|8@1+ (1,0) [0|255] "A" Vector__XXX
 SG_ LIN_SeAvailableCurrentL2 : 24|8@1+ (1,0) [0|255] "A" Vector__XXX
 SG_ LIN_SeSelectedVersion : 8|8@1+ (1,0) [0|255] "" Vector__XXX
 SG_ LIN_ChargingStatus : 0|8@1+ (1,0) [0|255] "" Vector__XXX

BO_ 2566874240 VCVCCU_LIN_SeNomVoltages: 5 VCCU
 SG_ LIN_SeFrequency : 32|8@1+ (1,0) [0|255] "" Vector__XXX
 SG_ LIN_SeNomVoltageLL : 16|16@1+ (0.1,0) [0|6553.5] "V" Vector__XXX
 SG_ LIN_SeNomVoltageL1N : 0|16@1+ (0.1,0) [0|6553.5] "V" Vector__XXX

BO_ 2566874496 VCVCCU_LIN_SeMaxCurrentList: 4 VCCU
 SG_ LIN_SeMaxCurrentN : 24|8@1+ (1,0) [0|255] "A" Vector__XXX
 SG_ LIN_SeMaxCurrentL3 : 16|8@1+ (1,0) [0|255] "A" Vector__XXX
 SG_ LIN_SeMaxCurrentL2 : 8|8@1+ (1,0) [0|255] "mV" Vector__XXX
 SG_ LIN_SeMaxCurrentL1 : 0|8@1+ (1,0) [0|255] "A" Vector__XXX

BO_ 2566854784 VCVCCU_InternalVoltageStatus: 8 VCCU
 SG_ SS_Voltage : 32|16@1+ (1,0) [0|65533] "" Vector__XXX
 SG_ Internal_VCC_KL30_Voltage : 48|16@1+ (1,0) [0|65533] "" Vector__XXX
 SG_ Internal_VCC_KL15_Voltage : 16|16@1+ (1,0) [0|65533] "" Vector__XXX
 SG_ Internal_VCC_12v_Voltage : 0|16@1+ (1,0) [0|65533] "" Vector__XXX

BO_ 2566855040 VCVCCU_InternalVoltageRawValues: 8 VCCU
 SG_ SS_Raw : 48|16@1+ (1,0) [0|65533] "" Vector__XXX
 SG_ Internal_VCC_KL30_Raw : 32|16@1+ (1,0) [0|65533] "" Vector__XXX
 SG_ Internal_VCC_KL15_Raw : 16|16@1+ (1,0) [0|65533] "" Vector__XXX
 SG_ Internal_VCC_12v_Raw : 0|16@1+ (1,0) [0|65533] "" Vector__XXX

BO_ 2566855296 VCVCCU_InletStatus2: 8 VCCU
 SG_ ProtectiveEarth_Offset : 32|16@1+ (1,-32000) [-32000|33533] "mV" Vector__XXX
 SG_ VCVCCU_ControlPilot_MinVoltage : 16|16@1+ (1,-32000) [-32000|33533] "mV" Vector__XXX
 SG_ Plug_present_voltage : 0|16@1+ (1,0) [0|65533] "mV" Vector__XXX

BO_ 2566853504 VCVCCU_InletStatus: 8 VCCU
 SG_ S3Switch_debounce_state : 62|2@1+ (1,0) [0|3] "" Vector__XXX
 SG_ S3Switch_status : 60|2@1+ (1,0) [0|3] "" Vector__XXX
 SG_ Inlet_connection_status : 58|2@1+ (1,0) [0|3] "" Vector__XXX
 SG_ Digital_input_debounce_state : 56|2@1+ (1,0) [0|3] "" Vector__XXX
 SG_ Inlet_max_current : 48|8@1+ (1,0) [0|255] "" Vector__XXX
 SG_ Inlet_motor_status : 44|3@1+ (1,0) [0|7] "" Vector__XXX
 SG_ Digital_input_wakeup : 42|2@1+ (1,0) [0|3] "" Vector__XXX
 SG_ Digital_input_status : 40|2@1+ (1,0) [0|3] "" Vector__XXX
 SG_ Inlet_HW_variant : 38|2@1+ (1,0) [0|3] "" Vector__XXX
 SG_ Pluglock_output1_selfdiag_status : 35|3@1+ (1,0) [0|7] "" Vector__XXX
 SG_ Pluglock_output0_selfdiag_status : 32|3@1+ (1,0) [0|7] "" Vector__XXX
 SG_ Plug_lock_motorstatus : 29|3@1+ (1,0) [0|7] "" Vector__XXX
 SG_ POSF_present_selfdiag_status : 26|3@1+ (1,0) [0|7] "" Vector__XXX
 SG_ Plug_present_wakeup : 24|2@1+ (1,0) [0|3] "" Vector__XXX
 SG_ Plug_present_status : 22|2@1+ (1,0) [0|3] "" Vector__XXX
 SG_ Plug_present_resistance : 19|3@1+ (1,0) [0|7] "" Vector__XXX
 SG_ Plug_present_selfdiag_status : 16|3@1+ (1,0) [0|7] "" Vector__XXX
 SG_ POS_Feedback_voltage : 0|16@1+ (1,0) [0|65533] "" Vector__XXX

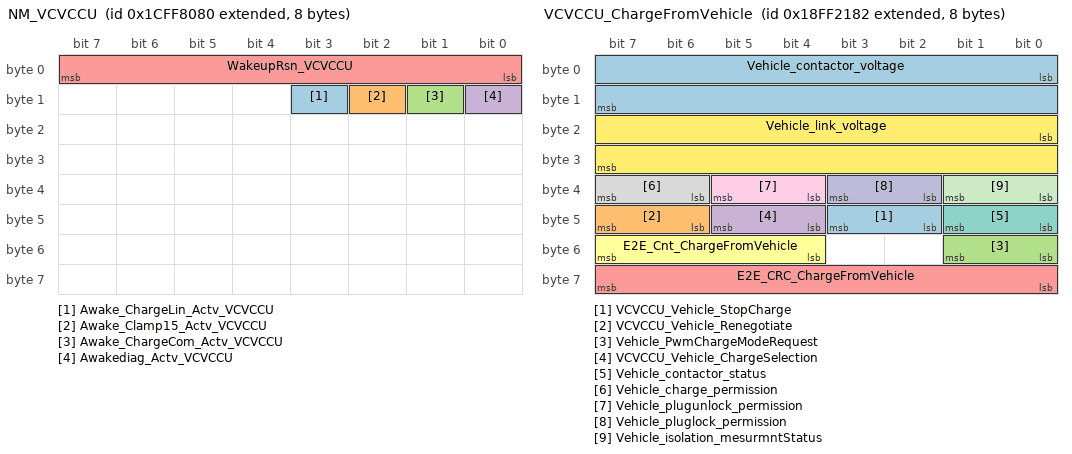
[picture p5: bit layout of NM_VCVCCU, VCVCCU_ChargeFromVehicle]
BO_ 2633990272 NM_VCVCCU: 8 VCCU
 SG_ Awake_ChargeLin_Actv_VCVCCU : 11|1@1+ (1,0) [0|1] "" Vector__XXX
 SG_ Awake_Clamp15_Actv_VCVCCU : 10|1@1+ (1,0) [0|1] "" Vector__XXX
 SG_ Awake_ChargeCom_Actv_VCVCCU : 9|1@1+ (1,0) [0|1] "" Vector__XXX
 SG_ Awakediag_Actv_VCVCCU : 8|1@1+ (1,0) [0|1] "" Vector__XXX
 SG_ WakeupRsn_VCVCCU : 0|8@1+ (1,0) [0|4] "" Vector__XXX

BO_ 2566857090 VCVCCU_ChargeFromVehicle: 8 VCU
 SG_ VCVCCU_Vehicle_StopCharge : 42|2@1+ (1,0) [0|3] "" Vector__XXX
 SG_ VCVCCU_Vehicle_Renegotiate : 46|2@1+ (1,0) [0|3] "" Vector__XXX
 SG_ Vehicle_PwmChargeModeRequest : 48|2@1+ (1,0) [0|3] "" Vector__XXX
 SG_ VCVCCU_Vehicle_ChargeSelection : 44|2@1+ (1,0) [0|3] "" Vector__XXX
 SG_ E2E_CRC_ChargeFromVehicle : 56|8@1+ (1,0) [0|255] "" Vector__XXX
 SG_ E2E_Cnt_ChargeFromVehicle : 52|4@1+ (1,0) [0|15] "" Vector__XXX
 SG_ Vehicle_contactor_status : 40|2@1+ (1,0) [0|3] "" Vector__XXX
 SG_ Vehicle_charge_permission : 38|2@1+ (1,0) [0|3] "" Vector__XXX
 SG_ Vehicle_plugunlock_permission : 36|2@1+ (1,0) [0|3] "" Vector__XXX
 SG_ Vehicle_pluglock_permission : 34|2@1+ (1,0) [0|3] "" Vector__XXX
 SG_ Vehicle_isolation_mesurmntStatus : 32|2@1+ (1,0) [0|3] "" Vector__XXX
 SG_ Vehicle_link_voltage : 16|16@1+ (1,0) [0|65533] "V" Vector__XXX
 SG_ Vehicle_contactor_voltage : 0|16@1+ (1,0) [0|65533] "V" Vector__XXX

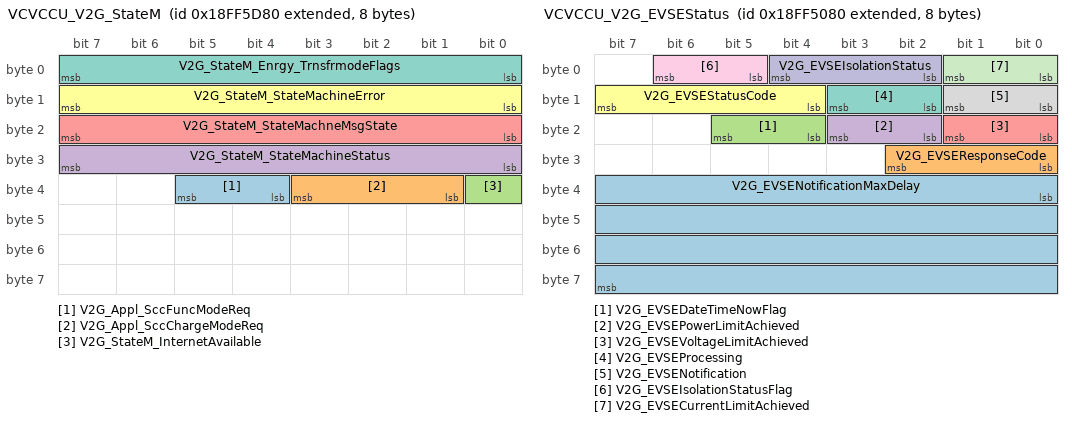
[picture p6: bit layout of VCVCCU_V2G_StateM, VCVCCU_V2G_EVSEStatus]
BO_ 2566872448 VCVCCU_V2G_StateM: 8 VCCU
 SG_ V2G_Appl_SccFuncModeReq : 36|2@1+ (1,0) [0|3] "" Vector__XXX
 SG_ V2G_Appl_SccChargeModeReq : 33|3@1+ (1,0) [0|6] "" Vector__XXX
 SG_ V2G_StateM_InternetAvailable : 32|1@1+ (1,0) [0|1] "" Vector__XXX
 SG_ V2G_StateM_StateMachineStatus : 24|8@1+ (1,0) [0|255] "" Vector__XXX
 SG_ V2G_StateM_StateMachneMsgState : 16|8@1+ (1,0) [0|255] "" Vector__XXX
 SG_ V2G_StateM_StateMachineError : 8|8@1+ (1,0) [0|255] "" Vector__XXX
 SG_ V2G_StateM_Enrgy_TrnsfrmodeFlags : 0|8@1+ (1,0) [0|255] "" Vector__XXX

BO_ 2566869120 VCVCCU_V2G_EVSEStatus: 8 VCCU
 SG_ V2G_EVSENotificationMaxDelay : 32|32@1+ (1,0) [0|4294967295] "" Vector__XXX
 SG_ V2G_EVSEResponseCode : 24|3@1+ (1,0) [0|7] "" Vector__XXX
 SG_ V2G_EVSEDateTimeNowFlag : 20|2@1+ (1,0) [0|3] "" Vector__XXX
 SG_ V2G_EVSEPowerLimitAchieved : 18|2@1+ (1,0) [0|3] "" Vector__XXX
 SG_ V2G_EVSEVoltageLimitAchieved : 16|2@1+ (1,0) [0|3] "" Vector__XXX
 SG_ V2G_EVSEStatusCode : 12|4@1+ (1,0) [0|15] "" Vector__XXX
 SG_ V2G_EVSEProcessing : 10|2@1+ (1,0) [0|3] "" Vector__XXX
 SG_ V2G_EVSENotification : 8|2@1+ (1,0) [0|3] "" Vector__XXX
 SG_ V2G_EVSEIsolationStatusFlag : 5|2@1+ (1,0) [0|3] "" Vector__XXX
 SG_ V2G_EVSEIsolationStatus : 2|3@1+ (1,0) [0|7] "" Vector__XXX
 SG_ V2G_EVSECurrentLimitAchieved : 0|2@1+ (1,0) [0|3] "" Vector__XXX

BO_ 2566871680 VCVCCU_V2G_EVSEPresentVoltage: 8 VCCU
 SG_ V2G_EVSEPresentVoltage_UnitFlag : 32|8@1+ (1,0) [0|255] "" Vector__XXX
 SG_ V2G_EVSEPresentVoltage_Values : 16|16@1- (1,0) [-32768|32767] "" Vector__XXX
 SG_ V2G_EVSEPrsntVoltage_Multiplier : 8|8@1- (1,0) [-128|127] "" Vector__XXX
 SG_ V2G_EVSEPresentVoltage_Unit : 0|4@1+ (1,0) [0|15] "" Vector__XXX

BO_ 2566871424 VCVCCU_V2G_EVSEPresentCurrent: 5 VCCU
 SG_ VCVCCU_V2G_EVSEPrsntCurnt_Flag : 32|8@1+ (1,0) [0|255] "" Vector__XXX
 SG_ V2G_EVSEPresentCurrent_Values : 16|16@1- (1,0) [-32768|32767] "" Vector__XXX
 SG_ V2G_EVSEPrsntCurent_Multiplier : 8|8@1+ (1,0) [0|255] "" Vector__XXX
 SG_ V2G_EVSEPresentCurrent_Unit : 0|4@1+ (1,0) [0|15] "" Vector__XXX

BO_ 2566871168 VCVCCU_V2G_EVSEPeakCurrentRipple: 8 VCCU
 SG_ V2G_EVSEPeakCurrent_UnitFlag : 32|8@1+ (1,0) [0|255] "" Vector__XXX
 SG_ V2G_EVSEPeakCurrent_Values : 16|16@1- (1,0) [-32768|32767] "" Vector__XXX
 SG_ V2G_EVSEPeakCurrent_Multiplier : 8|8@1- (1,0) [-128|127] "" Vector__XXX
 SG_ V2G_EVSEPeakCurrent_Unit : 0|4@1+ (1,0) [0|15] "" Vector__XXX

BO_ 2566870912 VCVCCU_V2G_EVSEMinVoltageLimit: 8 VCCU
 SG_ V2G_EVSEMinimumVoltage_UnitFlag : 32|8@1+ (1,0) [0|255] "" Vector__XXX
 SG_ V2G_EVSEMinimumVoltage_Values : 16|16@1- (1,0) [-32768|32767] "" Vector__XXX
 SG_ V2G_EVSEMinVoltage_Multiplier : 8|8@1- (1,0) [-128|127] "" Vector__XXX
 SG_ V2G_EVSEMinVoltage_Unit : 0|4@1+ (1,0) [0|15] "" Vector__XXX

BO_ 2566870656 VCVCCU_V2G_EVSEMinCurrentLimit: 8 VCCU
 SG_ V2G_EVSEMinimumCurrent_Unit : 0|4@1+ (1,0) [0|15] "" Vector__XXX
 SG_ V2G_EVSEMinCurrntLimit_Val : 48|16@1- (1,0) [-32768|32767] "" Vector__XXX
 SG_ V2G_EVSEMiniCurrent_Multiplier : 16|8@1- (1,0) [-128|127] "" Vector__XXX
 SG_ V2G_EVSEMinCurrent_UnitFlag : 32|8@1+ (1,0) [0|255] "" Vector__XXX

BO_ 2566870400 VCVCCU_V2G_EVSEMaxVoltageLimit: 5 VCCU
 SG_ V2G_MaxVoltageLimit_UnitFlag : 32|8@1+ (1,0) [0|255] "" Vector__XXX
 SG_ V2G_MaximumVoltageLimit_Values : 16|16@1- (1,0) [-32768|32767] "" Vector__XXX
 SG_ V2G_MaxVoltgeLimit_Multiplier : 8|8@1- (1,0) [-128|127] "" Vector__XXX
 SG_ V2G_EVSEMaxVoltageLimit_Flag : 4|2@1+ (1,0) [0|3] "" Vector__XXX
 SG_ V2G_EVSEMaximumVoltageLimit_Unit : 0|4@1+ (1,0) [0|15] "" Vector__XXX

BO_ 2566870144 VCVCCU_V2G_EVSEMaxPowerLimit: 5 VCCU
 SG_ V2G_EVSEMaxPowerLimit_UnitFlag : 32|8@1+ (1,0) [0|255] "" Vector__XXX
 SG_ V2G_EVSEMaxPowerLimit_Values : 16|16@1- (1,0) [-32768|32767] "" Vector__XXX
 SG_ V2G_EVSEMaxPowerLimit_Multiplier : 8|8@1- (1,0) [-128|127] "" Vector__XXX
 SG_ V2G_EVSEMaximumPowerLimit_Flag : 4|2@1+ (1,0) [0|3] "" Vector__XXX
 SG_ V2G_MaxPowerLimit_Unit : 0|4@1+ (1,0) [0|15] "" Vector__XXX

BO_ 2566869888 VCVCCU_V2G_MaximumCurrentLimit: 5 VCCU
 SG_ V2G_EVSECurrent_Values : 16|16@1- (1,0) [-32768|32767] "" Vector__XXX
 SG_ V2G_MaxCurrentLimit_Multiplier : 8|8@1- (1,0) [-128|127] "" Vector__XXX
 SG_ V2G_MaxCurrentLimit_UnitFlag : 32|8@1+ (1,0) [0|255] "" Vector__XXX
 SG_ V2G_MaxCurrentLimit_Flag : 4|2@1+ (1,0) [0|3] "" Vector__XXX
 SG_ V2G_EVSEMaxCurrentLimitunit : 0|4@1+ (1,0) [0|15] "" Vector__XXX

BO_ 2566869632 VCVCCUEVSEEnergyToBeDelivered: 5 VCCU
 SG_ V2G_EnergyToBeDeliver_unitFlag : 32|8@1+ (1,0) [0|255] "" Vector__XXX
 SG_ V2G_EnergyToBeDeliver_Values : 16|16@1- (1,0) [-32768|32767] "" Vector__XXX
 SG_ V2G_EnergyToBeDeliver_Multiplier : 8|8@1- (1,0) [-128|127] "" Vector__XXX
 SG_ V2G_EnergyToBeDelivered_Flag : 4|2@1+ (1,0) [0|3] "" Vector__XXX
 SG_ V2G_EnergyToBeDelivered_unit : 0|4@1+ (1,0) [0|15] "" Vector__XXX

BO_ 2566869376 VCVCCU_V2G_EVSECurrentTolerance: 5 VCCU
 SG_ V2G_EVSECurrentTolrance_unitflag : 32|8@1+ (1,0) [0|255] "" Vector__XXX
 SG_ V2G_EVSECurrent_Values : 16|16@1- (1,0) [-32768|32767] "" Vector__XXX
 SG_ V2G_EVSECurrentMultiplier : 8|8@1- (1,0) [-128|127] "" Vector__XXX
 SG_ V2G_EVSECurrentTolerance_Flag : 4|2@1+ (1,0) [0|3] "" Vector__XXX
 SG_ V2G_EVSECurrentTolerance_unit : 0|4@1+ (1,0) [0|15] "" Vector__XXX

BO_ 2566871936 VCVCCU_V2G_DateTimeNow: 8 VCCU
 SG_ V2G_DateTimeNow : 0|64@1+ (1,0) [0|1.84467440737096E+019] "" Vector__XXX

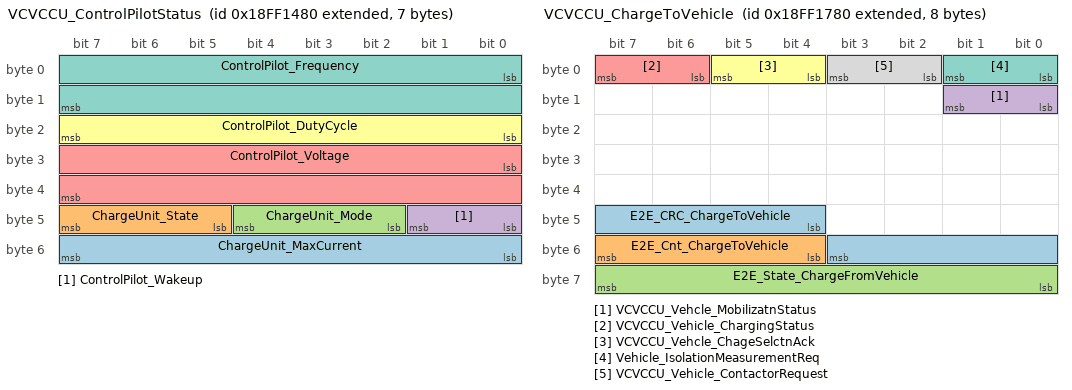
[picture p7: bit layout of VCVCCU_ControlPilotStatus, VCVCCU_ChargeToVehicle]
BO_ 2566853760 VCVCCU_ControlPilotStatus: 7 VCCU
 SG_ ChargeUnit_MaxCurrent : 48|8@1+ (1,0) [0|255] "A" Vector__XXX
 SG_ ChargeUnit_State : 45|3@1+ (1,0) [0|7] "" Vector__XXX
 SG_ ChargeUnit_Mode : 42|3@1+ (1,0) [0|7] "" Vector__XXX
 SG_ ControlPilot_Wakeup : 40|2@1+ (1,0) [0|3] "" Vector__XXX
 SG_ ControlPilot_Voltage : 24|16@1+ (1,-32000) [-32000|33533] "mV" Vector__XXX
 SG_ ControlPilot_DutyCycle : 16|8@1+ (0.5,0) [0|100] "%" Vector__XXX
 SG_ ControlPilot_Frequency : 0|16@1+ (1,0) [0|65533] "HZ" Vector__XXX

BO_ 2566854528 VCVCCU_ChargeToVehicle: 8 VCCU
 SG_ E2E_CRC_ChargeToVehicle : 44|8@1+ (1,0) [0|255] "" Vector__XXX
 SG_ E2E_Cnt_ChargeToVehicle : 52|4@1+ (1,0) [0|15] "" Vector__XXX
 SG_ E2E_State_ChargeFromVehicle : 56|8@1+ (1,0) [0|255] "" Vector__XXX
 SG_ VCVCCU_Vehcle_MobilizatnStatus : 8|2@1+ (1,0) [0|3] "" Vector__XXX
 SG_ VCVCCU_Vehicle_ChargingStatus : 6|2@1+ (1,0) [0|3] "" Vector__XXX
 SG_ VCVCCU_Vehcle_ChageSelctnAck : 4|2@1+ (1,0) [0|3] "" Vector__XXX
 SG_ Vehicle_IsolationMeasurementReq : 0|2@1+ (1,0) [0|3] "" Vector__XXX
 SG_ VCVCCU_Vehicle_ContactorRequest : 2|2@1+ (1,0) [0|3] "" Vector__XXX

BO_ 2566834816 DM01_VCVCCU: 1785 VCCU
 SG_ DTC_SPN_ConvMd_VCCU : 47|1@1+ (1,0) [0|1] "" Vector__XXX
 SG_ DTC_OccCnt_VCCU : 40|7@1+ (1,0) [0|127] "count(s)" Vector__XXX
 SG_ DTC_SPN_VCCU : 23|19@0+ (1,0) [0|524287] "" Vector__XXX
 SG_ DTC_FailModeID_VCCU : 32|5@1+ (1,0) [0|31] "" Vector__XXX
 SG_ DTC_MIL_Flash_Stat_VCCU : 14|2@1+ (1,0) [0|3] "" Vector__XXX
 SG_ DTC_RSL_Flash_Stat_VCCU : 12|2@1+ (1,0) [0|3] "" Vector__XXX
 SG_ DTC_AWL_Flash_Stat_VCCU : 10|2@1+ (1,0) [0|3] "" Vector__XXX
 SG_ DTC_PL_Flash_Stat_VCCU : 8|2@1+ (1,0) [0|3] "" Vector__XXX
 SG_ DTC_MIL_Stat_VCCU : 6|2@1+ (1,0) [0|3] "" Vector__XXX
 SG_ DTC_RSL_Stat_VCCU : 4|2@1+ (1,0) [0|3] "" Vector__XXX
 SG_ DTC_AWL_Stat_VCCU : 2|2@1+ (1,0) [0|3] "" Vector__XXX
 SG_ DTC_PL_Stat_VCCU : 0|2@1+ (1,0) [0|3] "" Vector__XXX

BO_ 2566844817 Brake_Pedal: 8 Praker_GW
 SG_ Parking_Brake_Switch : 2|2@1+ (1,0) [0|3] "" Vector__XXX
 SG_ Brake_Switch : 28|2@1+ (1,0) [0|3] "" Vector__XXX

BO_ 2564882321 Seat: 8 Praker_GW
 SG_ Seat_belt_switch : 30|2@1+ (1,0) [0|3] "" Vector__XXX

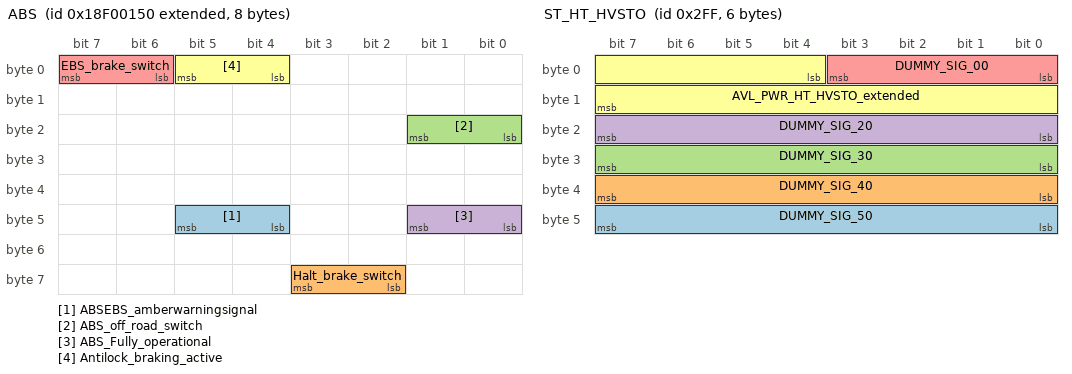
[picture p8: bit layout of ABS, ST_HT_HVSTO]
BO_ 2565865808 ABS: 8 VCU
 SG_ ABSEBS_amberwarningsignal : 44|2@1+ (1,0) [0|3] "" Vector__XXX
 SG_ Halt_brake_switch : 58|2@1+ (1,0) [0|3] "" Vector__XXX
 SG_ ABS_off_road_switch : 16|2@1+ (1,0) [0|3] "" Vector__XXX
 SG_ ABS_Fully_operational : 40|2@1+ (1,0) [0|3] "" Vector__XXX
 SG_ EBS_brake_switch : 6|2@1+ (1,0) [0|3] "" Vector__XXX
 SG_ Antilock_braking_active : 4|2@1+ (1,0) [0|3] "" Vector__XXX

BO_ 1603 Diag_SME_4: 8 SME_4
 SG_ Byte_8 : 56|8@1+ (1,0) [0|0] "" Vector__XXX
 SG_ Byte_7 : 48|8@1+ (1,0) [0|0] "" Vector__XXX
 SG_ Byte_6 : 40|8@1+ (1,0) [0|0] "" Vector__XXX
 SG_ Byte_5 : 32|8@1+ (1,0) [0|0] "" Vector__XXX
 SG_ Byte_4 : 24|8@1+ (1,0) [0|0] "" Vector__XXX
 SG_ Byte_3 : 16|8@1+ (1,0) [0|255] "" Vector__XXX
 SG_ TPCI : 8|8@1+ (1,0) [0|255] "" Vector__XXX
 SG_ TA : 0|8@1+ (1,0) [0|255] "" Vector__XXX

BO_ 1602 Diag_SME_3: 8 SME_3
 SG_ Byte_8 : 56|8@1+ (1,0) [0|0] "" Vector__XXX
 SG_ Byte_7 : 48|8@1+ (1,0) [0|0] "" Vector__XXX
 SG_ Byte_6 : 40|8@1+ (1,0) [0|0] "" Vector__XXX
 SG_ Byte_5 : 32|8@1+ (1,0) [0|0] "" Vector__XXX
 SG_ Byte_4 : 24|8@1+ (1,0) [0|0] "" Vector__XXX
 SG_ Byte_3 : 16|8@1+ (1,0) [0|255] "" Vector__XXX
 SG_ TPCI : 8|8@1+ (1,0) [0|255] "" Vector__XXX
 SG_ TA : 0|8@1+ (1,0) [0|255] "" Vector__XXX

BO_ 1601 Diag_SME_2: 8 SME_2
 SG_ Byte_8 : 56|8@1+ (1,0) [0|0] "" Vector__XXX
 SG_ Byte_7 : 48|8@1+ (1,0) [0|0] "" Vector__XXX
 SG_ Byte_6 : 40|8@1+ (1,0) [0|0] "" Vector__XXX
 SG_ Byte_5 : 32|8@1+ (1,0) [0|0] "" Vector__XXX
 SG_ Byte_4 : 24|8@1+ (1,0) [0|0] "" Vector__XXX
 SG_ Byte_3 : 16|8@1+ (1,0) [0|255] "" Vector__XXX
 SG_ TPCI : 8|8@1+ (1,0) [0|255] "" Vector__XXX
 SG_ TA : 0|8@1+ (1,0) [0|255] "" Vector__XXX

BO_ 1543 Diag_SME_1: 8 SME_1
 SG_ Byte_8 : 56|8@1+ (1,0) [0|0] "" Vector__XXX
 SG_ Byte_7 : 48|8@1+ (1,0) [0|0] "" Vector__XXX
 SG_ Byte_6 : 40|8@1+ (1,0) [0|0] "" Vector__XXX
 SG_ Byte_5 : 32|8@1+ (1,0) [0|0] "" Vector__XXX
 SG_ Byte_4 : 24|8@1+ (1,0) [0|255] "" Vector__XXX
 SG_ Byte_3 : 16|8@1+ (1,0) [0|255] "" Vector__XXX
 SG_ TPCI : 8|8@1+ (1,0) [0|255] "" Vector__XXX
 SG_ TA : 0|8@1+ (1,0) [0|255] "" Vector__XXX

BO_ 1777 Diag_UDS_Tester: 8 Diag_Tester
 SG_ Byte_8 : 56|8@1+ (1,0) [0|0] "" Vector__XXX
 SG_ Byte_7 : 48|8@1+ (1,0) [0|0] "" Vector__XXX
 SG_ Byte_6 : 40|8@1+ (1,0) [0|0] "" Vector__XXX
 SG_ Byte_5 : 32|8@1+ (1,0) [0|0] "" Vector__XXX
 SG_ Byte_4 : 24|8@1+ (1,0) [0|255] "" Vector__XXX
 SG_ Byte_3 : 16|8@1+ (1,0) [0|255] "" Vector__XXX
 SG_ TPCI : 8|8@1+ (1,0) [0|255] "" Vector__XXX
 SG_ TA : 0|8@1+ (1,0) [0|255] "" Vector__XXX

BO_ 767 ST_HT_HVSTO: 6 BMS
 SG_ DUMMY_SIG_50 : 40|8@1+ (1,0) [0|255] "" Vector__XXX
 SG_ DUMMY_SIG_40 : 32|8@1+ (1,0) [0|255] "" Vector__XXX
 SG_ DUMMY_SIG_30 : 24|8@1+ (1,0) [0|255] "" Vector__XXX
 SG_ DUMMY_SIG_20 : 16|8@1+ (1,0) [0|255] "" Vector__XXX
 SG_ DUMMY_SIG_00 : 0|4@1+ (1,0) [0|15] "" Vector__XXX
 SG_ AVL_PWR_HT_HVSTO_extended : 4|12@1+ (3,0) [0|12279] "W" Vector__XXX

BO_ 1415 SVC_SME: 8 BMS
 SG_ INQY_ID_PWRCOS_FN_2 m100 : 56|8@1+ (1,0) [0|255] "" Vector__XXX
 SG_ INQY_PWR_LV_FN_2 m100 : 48|8@1+ (10,0) [0|2540] "W" Vector__XXX
 SG_ INQY_PWR_HV_FN_2 m100 : 36|12@1+ (10,0) [0|40940] "W" Vector__XXX
 SG_ INQY_PWR_HV_FN_1 m100 : 24|12@1+ (10,0) [0|40940] "W" Vector__XXX
 SG_ INQY_PWR_LV_FN_1 m100 : 16|8@1+ (10,0) [0|2540] "W" Vector__XXX
 SG_ INQY_ID_PWRCOS_FN_1 m100 : 8|8@1+ (1,0) [0|255] "" Vector__XXX
 SG_ ID2 M : 0|8@1+ (1,0) [0|255] "" Vector__XXX

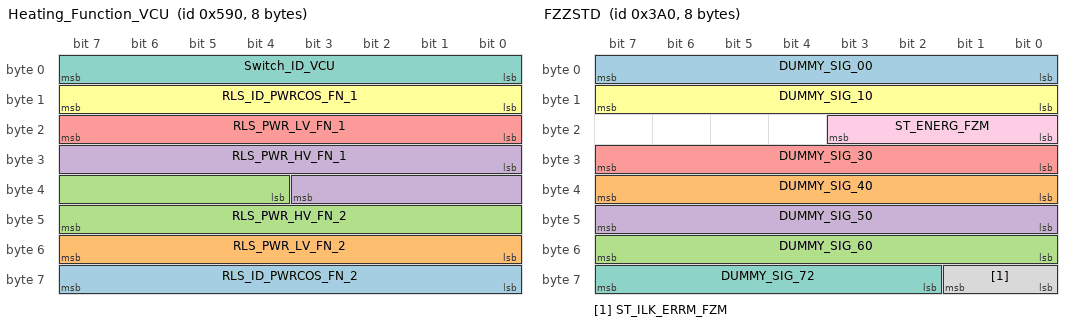
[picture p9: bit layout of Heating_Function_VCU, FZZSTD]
BO_ 1424 Heating_Function_VCU: 8 VCU
 SG_ RLS_ID_PWRCOS_FN_2 : 56|8@1+ (1,0) [0|255] "" Vector__XXX
 SG_ RLS_PWR_LV_FN_2 : 48|8@1+ (1,0) [0|255] "" Vector__XXX
 SG_ RLS_PWR_HV_FN_2 : 36|12@1+ (1,0) [0|4095] "" Vector__XXX
 SG_ RLS_PWR_HV_FN_1 : 24|12@1+ (1,0) [0|4095] "" Vector__XXX
 SG_ RLS_PWR_LV_FN_1 : 16|8@1+ (1,0) [0|255] "" Vector__XXX
 SG_ RLS_ID_PWRCOS_FN_1 : 8|8@1+ (1,0) [0|255] "" Vector__XXX
 SG_ Switch_ID_VCU : 0|8@1+ (1,0) [0|255] "" Vector__XXX

BO_ 1306 NM2_A_CAN_AE_VCU: 8 VCU
 SG_ NM2_USR_DT_ACAN : 32|32@1+ (1,0) [0|4294967295] "" Vector__XXX
 SG_ NM2_AUTOSAR_RES_ACAN : 0|32@1+ (1,0) [0|4294967295] "" Vector__XXX

BO_ 1434 SVC_AE: 8 VCU
 SG_ ID2 M : 0|8@1+ (1,0) [0|255] "" Vector__XXX
 SG_ RLS_ID_PWRCOS_FN_2 m101 : 56|8@1+ (1,0) [0|255] "" Vector__XXX
 SG_ RLS_PWR_LV_FN_2 m101 : 48|8@1+ (10,0) [0|2540] "W" Vector__XXX
 SG_ RLS_PWR_HV_FN_2 m101 : 36|12@1+ (10,0) [0|40940] "W" Vector__XXX
 SG_ RLS_PWR_HV_FN_1 m101 : 24|12@1+ (10,0) [0|40940] "W" Vector__XXX
 SG_ RLS_PWR_LV_FN_1 m101 : 16|8@1+ (10,0) [0|2540] "W" Vector__XXX
 SG_ RLS_ID_PWRCOS_FN_1 m101 : 8|8@1+ (1,0) [0|255] "" Vector__XXX

BO_ 970 FRC_RD_INFO: 8 VCU
 SG_ MUX_FRC_RD_INFO : 44|4@1+ (1,0) [0|15] "" Vector__XXX
 SG_ SYNCN_FRC_RD_INFO : 40|4@1+ (1,0) [0|15] "" Vector__XXX
 SG_ Progn_Durch_Hoch_Leistung_Erwe : 0|12@1+ (1,0) [0|4095] "" Vector__XXX

BO_ 928 FZZSTD: 8 VCU
 SG_ DUMMY_SIG_00 : 0|8@1+ (1,0) [0|255] "" Vector__XXX
 SG_ DUMMY_SIG_40 : 32|8@1+ (1,0) [0|255] "" Vector__XXX
 SG_ DUMMY_SIG_60 : 48|8@1+ (1,0) [0|255] "" Vector__XXX
 SG_ DUMMY_SIG_50 : 40|8@1+ (1,0) [0|255] "" Vector__XXX
 SG_ DUMMY_SIG_30 : 24|8@1+ (1,0) [0|255] "" Vector__XXX
 SG_ DUMMY_SIG_10 : 8|8@1+ (1,0) [0|255] "" Vector__XXX
 SG_ DUMMY_SIG_72 : 58|6@1+ (1,0) [0|63] "" Vector__XXX
 SG_ ST_ILK_ERRM_FZM : 56|2@1+ (1,0) [0|3] "" Vector__XXX
 SG_ ST_ENERG_FZM : 16|4@1+ (1,0) [0|15] "" Vector__XXX

BO_ 816 KILOMETERSTAND: 8 VCU
 SG_ DUMMY_SIG_30 : 24|8@1+ (1,0) [0|255] "" Vector__XXX
 SG_ DUMMY_SIG_70 : 56|8@1+ (1,0) [0|255] "" Vector__XXX
 SG_ DUMMY_SIG_60 : 48|8@1+ (1,0) [0|255] "" Vector__XXX
 SG_ DUMMY_SIG_50 : 40|8@1+ (1,0) [0|255] "" Vector__XXX
 SG_ DUMMY_SIG_40 : 32|8@1+ (1,0) [0|255] "" Vector__XXX
 SG_ MILE_KM : 0|24@1+ (1,0) [0|16777214] "Km" Vector__XXX

BO_ 808 RELATIVZEIT: 6 VCU
 SG_ DUMMY_SIG_50 : 40|8@1+ (1,0) [0|255] "" Vector__XXX
 SG_ DUMMY_SIG_40 : 32|8@1+ (1,0) [0|255] "" Vector__XXX
 SG_ T_SEC_COU_REL : 0|32@1+ (1,0) [0|4294967294] "" Vector__XXX

BO_ 714 A_TEMP: 2 VCU
 SG_ DUMMY_SIG_10 : 8|8@1+ (1,0) [0|255] "" Vector__XXX
 SG_ TEMP_EX : 0|8@1+ (0.5,-40) [-40|85] "°C" Vector__XXX

BO_ 417 V_VEH: 5 VCU
 SG_ DUMMY_SIG_40 : 32|4@1+ (1,0) [0|15] "" Vector__XXX
 SG_ DUMMY_SIG_10 : 8|8@1+ (1,0) [0|255] "" Vector__XXX
 SG_ DUMMY_SIG_00 : 0|8@1+ (1,0) [0|255] "" Vector__XXX
 SG_ DUMMY_SIG_44 : 36|4@1+ (1,0) [0|15] "" Vector__XXX
 SG_ V_VEH_COG : 16|16@1+ (0.015625,0) [0|350] "km/h" Vector__XXX

BO_ 414 CTR_PRTNT: 8 VCU
 SG_ DUMMY_SIG_60 : 48|8@1+ (1,0) [0|255] "" Vector__XXX
 SG_ DUMMY_SIG_70 : 56|8@1+ (1,0) [0|255] "" Vector__XXX
 SG_ CTR_FKTN_PRTNT_DRV : 16|32@1+ (1,0) [0|4294967295] "" Vector__XXX
 SG_ CTR_BS_PRTNT_DRV : 0|16@1+ (1,0) [0|65535] "" Vector__XXX

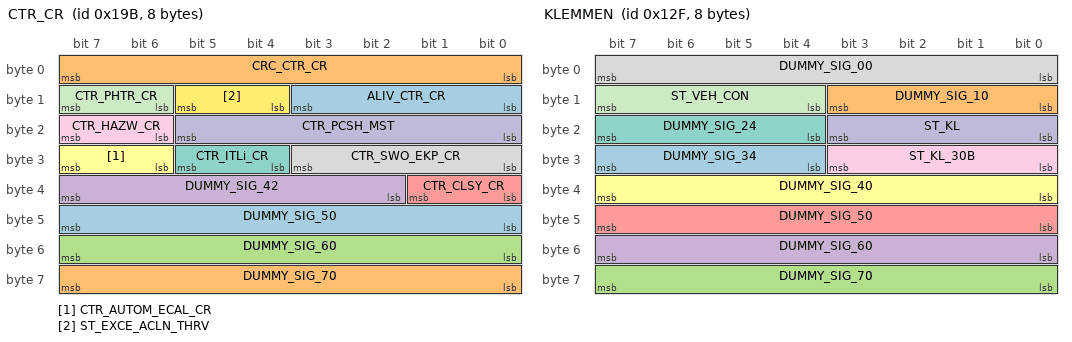
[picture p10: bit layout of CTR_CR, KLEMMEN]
BO_ 411 CTR_CR: 8 VCU
 SG_ DUMMY_SIG_50 : 40|8@1+ (1,0) [0|255] "" Vector__XXX
 SG_ DUMMY_SIG_70 : 56|8@1+ (1,0) [0|255] "" Vector__XXX
 SG_ DUMMY_SIG_60 : 48|8@1+ (1,0) [0|255] "" Vector__XXX
 SG_ DUMMY_SIG_42 : 34|6@1+ (1,0) [0|63] "" Vector__XXX
 SG_ CTR_CLSY_CR : 32|2@1+ (1,0) [0|3] "" Vector__XXX
 SG_ CTR_AUTOM_ECAL_CR : 30|2@1+ (1,0) [0|3] "" Vector__XXX
 SG_ CTR_ITLi_CR : 28|2@1+ (1,0) [0|3] "" Vector__XXX
 SG_ CTR_SWO_EKP_CR : 24|4@1+ (1,0) [0|15] "" Vector__XXX
 SG_ CTR_HAZW_CR : 22|2@1+ (1,0) [0|3] "" Vector__XXX
 SG_ CTR_PCSH_MST : 16|6@1+ (1,0) [0|63] "" Vector__XXX
 SG_ CTR_PHTR_CR : 14|2@1+ (1,0) [0|3] "" Vector__XXX
 SG_ ST_EXCE_ACLN_THRV : 12|2@1+ (1,0) [0|3] "" Vector__XXX
 SG_ ALIV_CTR_CR : 8|4@1+ (1,0) [0|15] "" Vector__XXX
 SG_ CRC_CTR_CR : 0|8@1+ (1,0) [0|255] "" Vector__XXX

BO_ 303 KLEMMEN: 8 VCU
 SG_ DUMMY_SIG_34 : 28|4@1+ (1,0) [0|15] "" Vector__XXX
 SG_ DUMMY_SIG_10 : 8|4@1+ (1,0) [0|15] "" Vector__XXX
 SG_ DUMMY_SIG_70 : 56|8@1+ (1,0) [0|255] "" Vector__XXX
 SG_ DUMMY_SIG_60 : 48|8@1+ (1,0) [0|255] "" Vector__XXX
 SG_ DUMMY_SIG_50 : 40|8@1+ (1,0) [0|255] "" Vector__XXX
 SG_ DUMMY_SIG_40 : 32|8@1+ (1,0) [0|255] "" Vector__XXX
 SG_ DUMMY_SIG_24 : 20|4@1+ (1,0) [0|15] "" Vector__XXX
 SG_ DUMMY_SIG_00 : 0|8@1+ (1,0) [0|255] "" Vector__XXX
 SG_ ST_KL_30B : 24|4@1+ (1,0) [0|15] "" Vector__XXX
 SG_ ST_KL : 16|4@1+ (1,0) [0|15] "" Vector__XXX
 SG_ ST_VEH_CON : 12|4@1+ (1,0) [0|15] "" Vector__XXX

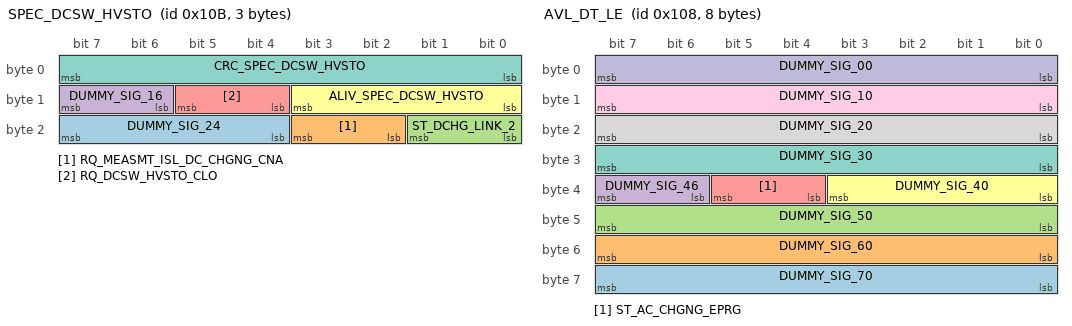
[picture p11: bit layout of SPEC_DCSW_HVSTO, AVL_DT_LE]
BO_ 267 SPEC_DCSW_HVSTO: 3 VCU
 SG_ DUMMY_SIG_24 : 20|4@1+ (1,0) [0|15] "" Vector__XXX
 SG_ RQ_MEASMT_ISL_DC_CHGNG_CNA : 18|2@1+ (1,0) [0|3] "" Vector__XXX
 SG_ ST_DCHG_LINK_2 : 16|2@1+ (1,0) [0|3] "" Vector__XXX
 SG_ DUMMY_SIG_16 : 14|2@1+ (1,0) [0|3] "" Vector__XXX
 SG_ RQ_DCSW_HVSTO_CLO : 12|2@1+ (1,0) [0|3] "" Vector__XXX
 SG_ ALIV_SPEC_DCSW_HVSTO : 8|4@1+ (1,0) [0|15] "" Vector__XXX
 SG_ CRC_SPEC_DCSW_HVSTO : 0|8@1+ (1,0) [0|255] "" Vector__XXX

BO_ 264 AVL_DT_LE: 8 VCU
 SG_ DUMMY_SIG_70 : 56|8@1+ (1,0) [0|255] "" Vector__XXX
 SG_ DUMMY_SIG_60 : 48|8@1+ (1,0) [0|255] "" Vector__XXX
 SG_ DUMMY_SIG_50 : 40|8@1+ (1,0) [0|255] "" Vector__XXX
 SG_ DUMMY_SIG_46 : 38|2@1+ (1,0) [0|3] "" Vector__XXX
 SG_ ST_AC_CHGNG_EPRG : 36|2@1+ (1,0) [0|3] "" Vector__XXX
 SG_ DUMMY_SIG_40 : 32|4@1+ (1,0) [0|15] "" Vector__XXX
 SG_ DUMMY_SIG_30 : 24|8@1+ (1,0) [0|255] "" Vector__XXX
 SG_ DUMMY_SIG_20 : 16|8@1+ (1,0) [0|255] "" Vector__XXX
 SG_ DUMMY_SIG_10 : 8|8@1+ (1,0) [0|255] "" Vector__XXX
 SG_ DUMMY_SIG_00 : 0|8@1+ (1,0) [0|255] "" Vector__XXX

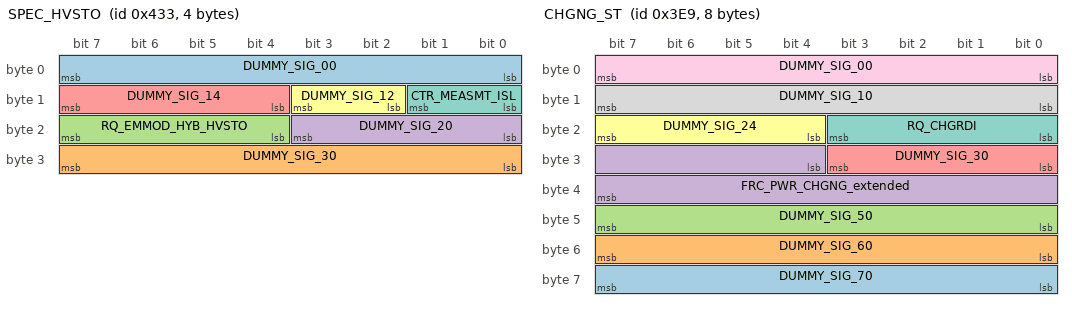
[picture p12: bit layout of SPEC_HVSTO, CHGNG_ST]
BO_ 1075 SPEC_HVSTO: 4 VCU
 SG_ DUMMY_SIG_00 : 0|8@1+ (1,0) [0|255] "" Vector__XXX
 SG_ DUMMY_SIG_30 : 24|8@1+ (1,0) [0|255] "" Vector__XXX
 SG_ RQ_EMMOD_HYB_HVSTO : 20|4@1+ (1,0) [0|15] "" Vector__XXX
 SG_ DUMMY_SIG_20 : 16|4@1+ (1,0) [0|15] "" Vector__XXX
 SG_ DUMMY_SIG_14 : 12|4@1+ (1,0) [0|15] "" Vector__XXX
 SG_ DUMMY_SIG_12 : 10|2@1+ (1,0) [0|3] "" Vector__XXX
 SG_ CTR_MEASMT_ISL : 8|2@1+ (1,0) [0|3] "" Vector__XXX

BO_ 1001 CHGNG_ST: 8 VCU
 SG_ DUMMY_SIG_70 : 56|8@1+ (1,0) [0|255] "" Vector__XXX
 SG_ DUMMY_SIG_60 : 48|8@1+ (1,0) [0|255] "" Vector__XXX
 SG_ DUMMY_SIG_50 : 40|8@1+ (1,0) [0|255] "" Vector__XXX
 SG_ FRC_PWR_CHGNG_extended : 28|12@1+ (300,0) [0|1228200] "W" Vector__XXX
 SG_ DUMMY_SIG_30 : 24|4@1+ (1,0) [0|15] "" Vector__XXX
 SG_ DUMMY_SIG_24 : 20|4@1+ (1,0) [0|15] "" Vector__XXX
 SG_ RQ_CHGRDI : 16|4@1+ (1,0) [0|15] "" Vector__XXX
 SG_ DUMMY_SIG_10 : 8|8@1+ (1,0) [0|255] "" Vector__XXX
 SG_ DUMMY_SIG_00 : 0|8@1+ (1,0) [0|255] "" Vector__XXX

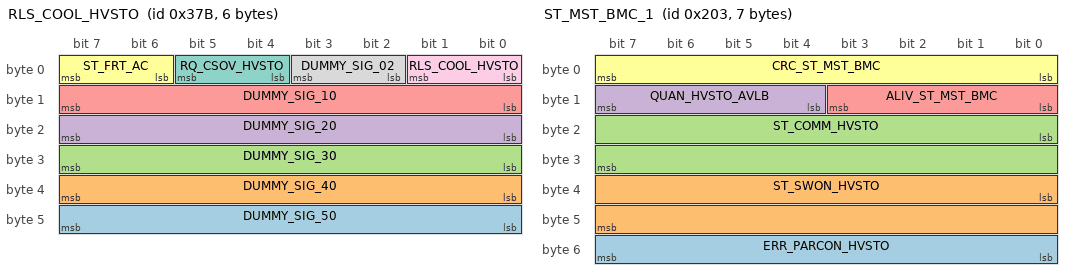
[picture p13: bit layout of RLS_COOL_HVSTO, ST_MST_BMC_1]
BO_ 891 RLS_COOL_HVSTO: 6 VCU
 SG_ DUMMY_SIG_50 : 40|8@1+ (1,0) [0|255] "" Vector__XXX
 SG_ DUMMY_SIG_40 : 32|8@1+ (1,0) [0|255] "" Vector__XXX
 SG_ DUMMY_SIG_30 : 24|8@1+ (1,0) [0|255] "" Vector__XXX
 SG_ DUMMY_SIG_20 : 16|8@1+ (1,0) [0|255] "" Vector__XXX
 SG_ DUMMY_SIG_10 : 8|8@1+ (1,0) [0|255] "" Vector__XXX
 SG_ ST_FRT_AC : 6|2@1+ (1,0) [0|3] "" Vector__XXX
 SG_ RQ_CSOV_HVSTO : 4|2@1+ (1,0) [0|3] "" Vector__XXX
 SG_ DUMMY_SIG_02 : 2|2@1+ (1,0) [0|3] "" Vector__XXX
 SG_ RLS_COOL_HVSTO : 0|2@1+ (1,0) [0|3] "" Vector__XXX

BO_ 1065 ST_MST_BMC_2: 8 BMS
 SG_ DUMMY_SIG_70 : 56|8@1+ (1,0) [0|255] "" Vector__XXX
 SG_ DUMMY_SIG_60 : 48|8@1+ (1,0) [0|255] "" Vector__XXX
 SG_ ST_HT_ACTV_HVSTO : 32|16@1+ (1,0) [0|65535] "" Vector__XXX
 SG_ ST_HVIL_HVSTO : 16|16@1+ (1,0) [0|65535] "" Vector__XXX
 SG_ ST_CSOV_OPN_HVSTO : 0|16@1+ (1,0) [0|65535] "" Vector__XXX

BO_ 515 ST_MST_BMC_1: 7 BMS
 SG_ ERR_PARCON_HVSTO : 48|8@1+ (1,0) [0|255] "" Vector__XXX
 SG_ ST_SWON_HVSTO : 32|16@1+ (1,0) [0|65535] "" Vector__XXX
 SG_ ST_COMM_HVSTO : 16|16@1+ (1,0) [0|65535] "" Vector__XXX
 SG_ QUAN_HVSTO_AVLB : 12|4@1+ (1,0) [0|14] "" Vector__XXX
 SG_ ALIV_ST_MST_BMC : 8|4@1+ (1,0) [0|15] "" Vector__XXX
 SG_ CRC_ST_MST_BMC : 0|8@1+ (1,0) [0|255] "" Vector__XXX

BO_ 1287 NM2_A_CAN_SME_BMC: 8 BMS
 SG_ NM2_USR_DT_ACAN : 32|32@1+ (1,0) [0|4294967295] "" Vector__XXX
 SG_ NM2_AUTOSAR_RES_ACAN : 0|32@1+ (1,0) [0|4294967295] "" Vector__XXX

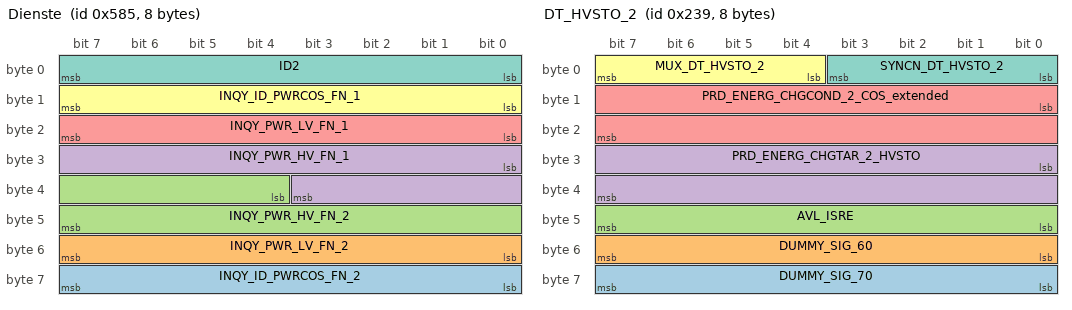
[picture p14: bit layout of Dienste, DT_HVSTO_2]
BO_ 1413 Dienste: 8 BMS
 SG_ INQY_ID_PWRCOS_FN_2 : 56|8@1+ (1,0) [0|255] "" Vector__XXX
 SG_ INQY_PWR_LV_FN_2 : 48|8@1+ (1,0) [0|255] "" Vector__XXX
 SG_ INQY_PWR_HV_FN_2 : 36|12@1+ (1,0) [0|4095] "" Vector__XXX
 SG_ INQY_PWR_HV_FN_1 : 24|12@1+ (1,0) [0|4095] "" Vector__XXX
 SG_ INQY_PWR_LV_FN_1 : 16|8@1+ (1,0) [0|255] "" Vector__XXX
 SG_ INQY_ID_PWRCOS_FN_1 : 8|8@1+ (1,0) [0|255] "" Vector__XXX
 SG_ ID2 : 0|8@1+ (1,0) [0|255] "" Vector__XXX

BO_ 757 LIM_CHG_DCHG_HVSTO: 8 BMS
 SG_ I_DYN_MAX_DCHG_HVSTO_extended : 48|16@1+ (0.2,-6553) [-6553|6553] "A" Vector__XXX
 SG_ U_MIN_DCHG_HVSTO : 32|16@1+ (0.1,0) [0|819] "V" Vector__XXX
 SG_ I_DYN_MAX_CHG_HVSTO_extended : 16|16@1+ (0.2,-6553) [-6553|6553] "A" Vector__XXX
 SG_ U_MAX_CHG_HVSTO : 0|16@1+ (0.1,0) [0|819] "V" Vector__XXX

BO_ 569 DT_HVSTO_2: 8 BMS
 SG_ DUMMY_SIG_70 : 56|8@1+ (1,0) [0|255] "" Vector__XXX
 SG_ DUMMY_SIG_60 : 48|8@1+ (1,0) [0|255] "" Vector__XXX
 SG_ AVL_ISRE : 40|8@1+ (10,0) [0|2047] "kOhm" Vector__XXX
 SG_ PRD_ENERG_CHGTAR_2_HVSTO : 24|16@1+ (0.02,0) [0|1310.64] "kWh" Vector__XXX
 SG_ PRD_ENERG_CHGCOND_2_COS_extended : 8|16@1+ (10,0) [0|655340] "Wh" Vector__XXX
 SG_ MUX_DT_HVSTO_2 : 4|4@1+ (1,0) [0|15] "" Vector__XXX
 SG_ SYNCN_DT_HVSTO_2 : 0|4@1+ (1,0) [0|14] "" Vector__XXX

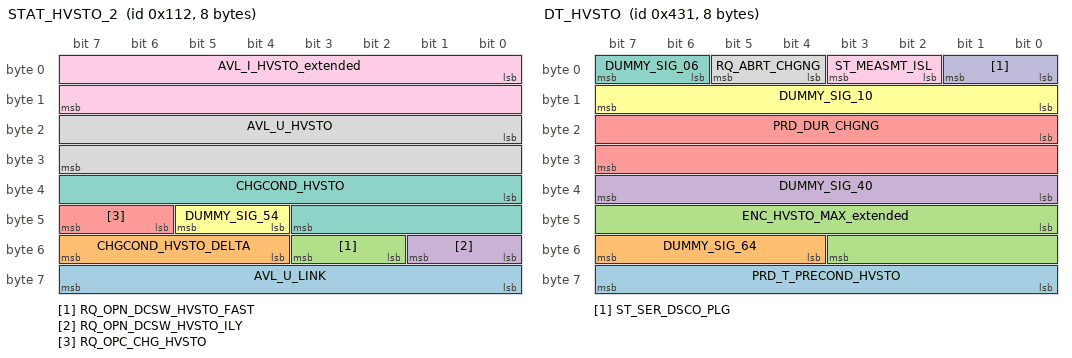
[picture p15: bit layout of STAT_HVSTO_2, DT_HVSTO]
BO_ 274 STAT_HVSTO_2: 8 BMS
 SG_ AVL_U_LINK : 56|8@1+ (1,0) [0|255] "" Vector__XXX
 SG_ CHGCOND_HVSTO_DELTA : 52|4@1+ (0.00834,0) [0|0.1] "%" Vector__XXX
 SG_ RQ_OPN_DCSW_HVSTO_FAST : 50|2@1+ (1,0) [0|3] "" Vector__XXX
 SG_ RQ_OPN_DCSW_HVSTO_ILY : 48|2@1+ (1,0) [0|3] "" Vector__XXX
 SG_ RQ_OPC_CHG_HVSTO : 46|2@1+ (1,0) [0|3] "" Vector__XXX
 SG_ DUMMY_SIG_54 : 44|2@1+ (1,0) [0|3] "" Vector__XXX
 SG_ CHGCOND_HVSTO : 32|12@1+ (0.1,0) [0|100] "%" Vector__XXX
 SG_ AVL_U_HVSTO : 16|16@1+ (0.1,0) [0|819] "V" Vector__XXX
 SG_ AVL_I_HVSTO_extended : 0|16@1+ (0.2,-6553) [-6553|6553] "A" Vector__XXX

BO_ 1073 DT_HVSTO: 8 BMS
 SG_ PRD_T_PRECOND_HVSTO : 56|8@1+ (2,0) [0|500] "min" Vector__XXX
 SG_ DUMMY_SIG_64 : 52|4@1+ (1,0) [0|15] "" Vector__XXX
 SG_ ENC_HVSTO_MAX_extended : 40|12@1+ (0.15,0) [0|614.1] "" Vector__XXX
 SG_ DUMMY_SIG_40 : 32|8@1+ (1,0) [0|255] "" Vector__XXX
 SG_ PRD_DUR_CHGNG : 16|16@1+ (1,0) [0|65532] "" Vector__XXX
 SG_ DUMMY_SIG_10 : 8|8@1+ (1,0) [0|255] "" Vector__XXX
 SG_ DUMMY_SIG_06 : 6|2@1+ (1,0) [0|3] "" Vector__XXX
 SG_ RQ_ABRT_CHGNG : 4|2@1+ (1,0) [0|3] "" Vector__XXX
 SG_ ST_MEASMT_ISL : 2|2@1+ (1,0) [0|3] "" Vector__XXX
 SG_ ST_SER_DSCO_PLG : 0|2@1+ (1,0) [0|3] "" Vector__XXX

BO_ 1052 ST_OPMO_HYB_2: 2 BMS
 SG_ DUMMY_SIG_12 : 10|6@1+ (1,0) [0|63] "" Vector__XXX
 SG_ ST_COOL_HVSTO : 8|2@1+ (1,0) [0|3] "" Vector__XXX
 SG_ DUMMY_SIG_00 : 0|8@1+ (1,0) [0|255] "" Vector__XXX

BO_ 1037 ST_CHG_HVSTO_1: 8 BMS
 SG_ AVLB_PWR_LT_DCHG_HVSTO_extended : 48|16@1+ (40,-2621280) [-2621280|2621280] "W" Vector__XXX
 SG_ AVLB_PWR_LT_CHG_HVSTO_extended : 32|16@1+ (40,0) [0|2621280] "W" Vector__XXX
 SG_ AVLB_PWR_SRT_DCHG_HVSTO_extended : 16|16@1+ (40,-2621280) [-2621280|2621280] "W" Vector__XXX
 SG_ AVLB_PWR_SRT_CHG_HVSTO_extended : 0|16@1+ (40,0) [0|2621280] "W" Vector__XXX

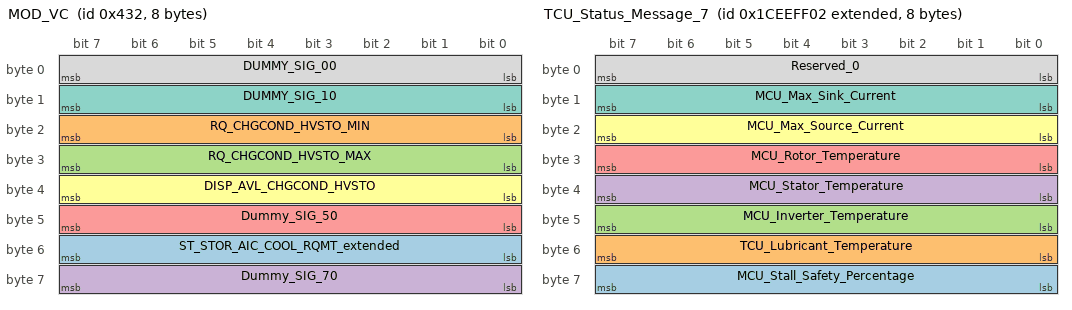
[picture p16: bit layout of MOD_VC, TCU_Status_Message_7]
BO_ 1074 MOD_VC: 8 BMS
 SG_ ST_STOR_AIC_COOL_RQMT_extended : 48|8@1+ (100,0) [0|25200] "W" Vector__XXX
 SG_ RQ_CHGCOND_HVSTO_MIN : 16|8@1+ (0.5,0) [0|100] "%" Vector__XXX
 SG_ RQ_CHGCOND_HVSTO_MAX : 24|8@1- (0.5,0) [0|100] "%" Vector__XXX
 SG_ Dummy_SIG_70 : 56|8@1+ (1,0) [0|255] "" Vector__XXX
 SG_ Dummy_SIG_50 : 40|8@1+ (1,0) [0|255] "" Vector__XXX
 SG_ DISP_AVL_CHGCOND_HVSTO : 32|8@1+ (0.5,0) [0|100] "%" Vector__XXX
 SG_ DUMMY_SIG_10 : 8|8@1+ (1,0) [0|255] "" Vector__XXX
 SG_ DUMMY_SIG_00 : 0|8@1+ (1,0) [0|255] "" Vector__XXX

BO_ 506 ST_HVSTO_1: 8 BMS
 SG_ ERR_EMMOD_HVSTO : 18|2@1+ (1,0) [0|3] "" Vector__XXX
 SG_ AVL_TEMP_HVSTO_MAX : 56|8@1+ (1,-50) [-50|202] "°C" Vector__XXX
 SG_ AVL_TEMP_HVSTO_MIN : 48|8@1+ (1,-50) [-50|202] "°C" Vector__XXX
 SG_ AVL_TEMP_HTEX_HVSTO : 40|8@1+ (1,-50) [-50|204] "°C" Vector__XXX
 SG_ AVL_TEMP_HVSTO : 32|8@1+ (1,-50) [-50|204] "°C" Vector__XXX
 SG_ ST_WARN_OTMP_HVSTO : 30|2@1+ (1,0) [0|3] "" Vector__XXX
 SG_ DUMMY_SIG_34 : 28|2@1+ (1,0) [0|3] "" Vector__XXX
 SG_ ST_CSOV_HVSTO_COLERR : 24|4@1+ (1,0) [0|15] "" Vector__XXX
 SG_ ST_WARN_ISL_BN_HV : 22|2@1+ (1,0) [0|3] "" Vector__XXX
 SG_ ST_ERR_DCSW_HVSTO : 20|2@1+ (1,0) [0|3] "" Vector__XXX
 SG_ RQ_SER_HVSTO : 16|2@1+ (1,0) [0|3] "" Vector__XXX
 SG_ ST_EMMOD_HVSTO : 14|2@1+ (1,0) [0|3] "" Vector__XXX
 SG_ ST_DCSW_HVSTO : 12|2@1+ (1,0) [0|3] "" Vector__XXX
 SG_ ST_PRCHRG_LOKD_HVSTO : 10|2@1+ (1,0) [0|3] "" Vector__XXX
 SG_ ST_ERR_LOKG_HVSTO : 8|2@1+ (1,0) [0|3] "" Vector__XXX
 SG_ ST_VA_COOL_HVSTO : 6|2@1+ (1,0) [0|3] "" Vector__XXX
 SG_ RQ_COOL_HVSTO : 4|2@1+ (1,0) [0|3] "" Vector__XXX
 SG_ ST_ERR_ISL_INTL_BN_H : 2|2@1+ (1,0) [0|3] "" Vector__XXX
 SG_ ST_ERR_ISL_EXTN_BN_HV : 0|2@1+ (1,0) [0|3] "" Vector__XXX

BO_ 2365541622 DC1_Command_DC2: 8 DCDC_inmotion_DC1
 SG_ CommandCurrent_DC2 : 32|16@1+ (0.05,-1600) [-1600|1612.75] "A" Vector__XXX
 SG_ CommandVoltage_DC2 : 16|16@1+ (0.05,0) [0|3212.7] "V" Vector__XXX
 SG_ ControlMode_DC2 : 8|2@1+ (1,0) [0|3] "" Vector__XXX

BO_ 2632908546 TCU_Status_Message_7: 8 TCU
 SG_ MCU_Stall_Safety_Percentage : 56|8@1+ (0.4,0) [0|100] "%" Vector__XXX
 SG_ TCU_Lubricant_Temperature : 48|8@1+ (1,-40) [-40|210] "°C" Vector__XXX
 SG_ MCU_Inverter_Temperature : 40|8@1+ (1,-40) [-40|210] "°C" Vector__XXX
 SG_ MCU_Stator_Temperature : 32|8@1+ (1,-40) [-40|210] "°C" Vector__XXX
 SG_ MCU_Rotor_Temperature : 24|8@1+ (1,-40) [-40|210] "°C" Vector__XXX
 SG_ MCU_Max_Source_Current : 16|8@1+ (5,0) [0|1275] "Amps" Vector__XXX
 SG_ MCU_Max_Sink_Current : 8|8@1+ (5,0) [0|1275] "Amps" Vector__XXX
 SG_ Reserved_0 : 0|8@1+ (1,0) [0|255] "" Vector__XXX

BO_ 2565799682 TCU_Status_Message_6: 8 TCU
 SG_ MCU_Acceleration_limit : 48|16@1+ (1,0) [0|32768] "rpm/s " Vector__XXX
 SG_ MCU_Voltage : 32|16@1- (0.1,0) [-3212.8|3212.8] "volts" Vector__XXX
 SG_ MCU_Current : 16|16@1- (0.1,0) [-3212.8|3212.8] "amps" Vector__XXX
 SG_ MCU_Leg_Current : 0|16@1+ (1,0) [0|32768] "amps" Vector__XXX

BO_ 2498690818 TCU_Status_Message_5: 8 TCU
 SG_ TCU_requested_torque : 48|16@1- (0.1,0) [-3212.8|3212.8] "Nm" Vector__XXX
 SG_ MCU_desored_torque : 32|16@1- (0.1,0) [-3212.8|3212.8] "Nm" Vector__XXX
 SG_ MCU_torque : 16|16@1- (0.1,0) [-3212.8|3212.8] "Nm" Vector__XXX
 SG_ TCU_torque : 0|16@1- (0.2,0) [-6425.6|6425.6] "Nm" Vector__XXX

BO_ 2431581954 TCU_Status_Message_4: 8 TCU
 SG_ Max_Drive_torque_allowed : 48|16@1+ (0.1,0) [0|6425.6] "Nm" Vector__XXX
 SG_ Max_Regen_torque_allowed : 32|16@1+ (0.1,0) [0|6425.6] "Nm" Vector__XXX
 SG_ VCU_torque_requested : 0|32@1- (0.1,0) [-6425.6|6425.6] "Nm" Vector__XXX

BO_ 2364473090 TCU_Status_Message_3: 8 TCU
 SG_ MCU_inverter_fault : 63|1@1+ (1,0) [0|1] "Boolean" Vector__XXX
 SG_ MCU_intverter_fault_history : 62|1@1+ (1,0) [0|1] "Boolean" Vector__XXX
 SG_ MCU_intverter_fault_latched : 61|1@1+ (1,0) [0|1] "Boolean" Vector__XXX
 SG_ MCU_intverter_fault_latch_histry : 60|1@1+ (1,0) [0|1] "Boolean" Vector__XXX
 SG_ MCU_limp_home_mode : 59|1@1+ (1,0) [0|1] "Boolean" Vector__XXX
 SG_ MCU_limp_home_mode_history : 58|1@1+ (1,0) [0|1] "Boolean" Vector__XXX
 SG_ MCU_ADC_calibration_problem : 57|1@1+ (1,0) [0|1] "Boolean" Vector__XXX
 SG_ MCU_ADC_calibrate_prblem_histry : 56|1@1+ (1,0) [0|1] "Boolean" Vector__XXX
 SG_ MCU_overvoltage_alarm_history : 54|1@1+ (1,0) [0|1] "Boolean" Vector__XXX
 SG_ MCU_overvoltage_alarm : 55|1@1+ (1,0) [0|1] "Boolean" Vector__XXX
 SG_ MCU_overspeed_alarm : 53|1@1+ (1,0) [0|1] "Boolean" Vector__XXX
 SG_ MCU_overspeed_alarm_history : 52|1@1+ (1,0) [0|1] "Boolean" Vector__XXX
 SG_ MCU_overvoltage_warning : 51|1@1+ (1,0) [0|1] "Boolean" Vector__XXX
 SG_ MCU_overvoltage_warning_history : 50|1@1+ (1,0) [0|1] "Boolean" Vector__XXX
 SG_ MCU_over_speed_warning : 49|1@1+ (1,0) [0|1] "Boolean" Vector__XXX
 SG_ MCU_over_speed_warning_history : 48|1@1+ (1,0) [0|1] "Boolean" Vector__XXX
 SG_ MCU_inverter_over_temp : 47|1@1+ (1,0) [0|1] "Boolean" Vector__XXX
 SG_ MCU_inverter_over_temp_history : 46|1@1+ (1,0) [0|1] "Boolean" Vector__XXX
 SG_ MCU_stator_over_temp : 45|1@1+ (1,0) [0|1] "Boolean" Vector__XXX
 SG_ MCU_stator_over_temp_history : 44|1@1+ (1,0) [0|1] "Boolean" Vector__XXX
 SG_ MCU_rotor_over_temp : 43|1@1+ (1,0) [0|1] "Boolean" Vector__XXX
 SG_ MCU_rotor_over_temp_history : 42|1@1+ (1,0) [0|1] "Boolean" Vector__XXX
 SG_ MCU_undervoltage_warning : 41|1@1+ (1,0) [0|1] "Boolean" Vector__XXX
 SG_ MCU_undervoltage_warning_history : 40|1@1+ (1,0) [0|1] "Boolean" Vector__XXX
 SG_ MCU_over_phase_advance : 39|1@1+ (1,0) [0|1] "Boolean" Vector__XXX
 SG_ MCU_over_phase_advance_history : 38|1@1+ (1,0) [0|1] "Boolean" Vector__XXX
 SG_ MCU_over_bus_current : 37|1@1+ (1,0) [0|1] "Boolean" Vector__XXX
 SG_ MCU_over_bus_current_history : 36|1@1+ (1,0) [0|1] "Boolean" Vector__XXX
 SG_ MCU_over_leg_current : 35|1@1+ (1,0) [0|1] "Boolean" Vector__XXX
 SG_ MCU_over_leg_current_history : 34|1@1+ (1,0) [0|1] "Boolean" Vector__XXX
 SG_ MCU_not_enabled : 33|1@1+ (1,0) [0|1] "Boolean" Vector__XXX
 SG_ MCU_not_enabled_history : 32|1@1+ (1,0) [0|1] "Boolean" Vector__XXX
 SG_ Transmission_output_speed : 16|16@1- (1,0) [-16384|16384] "rpm" Vector__XXX
 SG_ MCU_motor_speed : 0|16@1- (1,0) [-16384|16384] "rpm" Vector__XXX

BO_ 2297364226 TCU_Status_Message_2: 8 TCU
 SG_ Current_transmission_mode : 60|4@1+ (1,0) [0|6] "Enumerated" Vector__XXX
 SG_ Selected_Gear : 58|2@1+ (1,0) [0|3] "Enumeration" Vector__XXX
 SG_ Upshift_in_progress : 57|1@1+ (1,0) [0|1] "Boolean" Vector__XXX
 SG_ Downshift_In_Progress : 56|1@1+ (1,0) [0|1] "Boolean" Vector__XXX
 SG_ Upshift_Failed : 55|1@1+ (1,0) [0|1] "Boolean" Vector__XXX
 SG_ DownShift_Failed : 54|1@1+ (1,0) [0|1] "Boolean" Vector__XXX
 SG_ Slow_Upshift : 53|1@1+ (1,0) [0|1] "Boolean" Vector__XXX
 SG_ Slow_Downshift : 52|1@1+ (1,0) [0|1] "Boolean" Vector__XXX
 SG_ Shift_Disabled : 51|1@1+ (1,0) [0|1] "Boolean" Vector__XXX
 SG_ Max_Shift_Speed_Delta_Exceeded : 50|1@1+ (1,0) [0|1] "Boolean" Vector__XXX
 SG_ Air_Pressure_Out_of_Range : 49|1@1+ (1,0) [0|1] "Boolean" Vector__XXX
 SG_ Forced_Gear_Engagement_Torque : 48|1@1+ (1,0) [0|1] "Boolean" Vector__XXX
 SG_ Motor_speed_mistach_match_error : 47|1@1+ (1,0) [0|1] "Boolean" Vector__XXX
 SG_ Driveshaft_speed_mistach_match : 46|1@1+ (1,0) [0|1] "Boolean" Vector__XXX
 SG_ MCU_CAN_Active : 45|1@1+ (1,0) [0|1] "Boolean" Vector__XXX
 SG_ MCU_CAN_Timeout : 44|1@1+ (1,0) [0|1] "Boolean" Vector__XXX
 SG_ MCU_Watchdog_error : 43|1@1+ (1,0) [0|1] "Boolean" Vector__XXX
 SG_ TCU_command_Msg1_error : 42|1@1+ (1,0) [0|1] "Boolean" Vector__XXX
 SG_ TCU_cmd_MSG1_watchdog_timeout : 41|1@1+ (1,0) [0|1] "Boolean" Vector__XXX
 SG_ TCU_command_MSG2_error : 40|1@1+ (1,0) [0|1] "Boolean" Vector__XXX
 SG_ TCU_cmd_MSG2_watchdog_timeout : 39|1@1+ (1,0) [0|1] "Boolean" Vector__XXX
 SG_ Trans_temp_warning : 38|1@1+ (1,0) [0|1] "Boolean" Vector__XXX
 SG_ Trans_temp_error : 37|1@1+ (1,0) [0|1] "Boolean" Vector__XXX
 SG_ Trans_temp_limiting : 36|1@1+ (1,0) [0|1] "Boolean" Vector__XXX
 SG_ Trans_temp_read_error : 35|1@1+ (1,0) [0|1] "Boolean" Vector__XXX
 SG_ MCU_inveter_temp_read_error : 34|1@1+ (1,0) [0|1] "Boolean" Vector__XXX
 SG_ MCU_stator_temp_read_error : 33|1@1+ (1,0) [0|1] "Boolean" Vector__XXX
 SG_ MCU_rotar_temp_read_error : 32|1@1+ (1,0) [0|1] "Boolean" Vector__XXX
 SG_ MCU_regen_type_error : 31|1@1+ (1,0) [0|1] "Boolean" Vector__XXX
 SG_ Factory_diagnostic_MSG_LSB : 16|15@1+ (1,0) [0|32767] "" Vector__XXX
 SG_ MCU_power_switches_off : 15|1@1+ (1,0) [0|1] "Boolean" Vector__XXX
 SG_ MCU_invalid_power_supply : 14|1@1+ (1,0) [0|1] "Boolean" Vector__XXX
 SG_ MCU_bad_switch : 13|1@1+ (1,0) [0|1] "Boolean" Vector__XXX
 SG_ MCU_bad_position_signal : 12|1@1+ (1,0) [0|1] "Boolean" Vector__XXX
 SG_ MCU_phase_current_sensor_error : 11|1@1+ (1,0) [0|1] "Boolean" Vector__XXX
 SG_ MCU_stall_condition_active : 10|1@1+ (1,0) [0|1] "Boolean" Vector__XXX
 SG_ MCU_forces_open_loop : 9|1@1+ (1,0) [0|1] "Boolean" Vector__XXX
 SG_ MCU_turbo_mode : 8|1@1+ (1,0) [0|1] "Boolean" Vector__XXX
 SG_ MCU_using_raw_speed : 7|1@1+ (1,0) [0|1] "Boolean" Vector__XXX
 SG_ MCU_accel_limited : 6|1@1+ (1,0) [0|1] "Boolean" Vector__XXX
 SG_ MCU_current_trip_failt_lleg_bus : 5|1@1+ (1,0) [0|1] "Boolean" Vector__XXX
 SG_ MCU_CAN_limits_active : 1|1@1+ (1,0) [0|1] "Boolean" Vector__XXX
 SG_ MCU_RegenSwitchOPen : 4|1@1+ (1,0) [0|1] "Boolean" Vector__XXX
 SG_ MCU_ABC_phase_order : 3|1@1+ (1,0) [0|1] "Enumeration" Vector__XXX
 SG_ MCU_system_disable_in_motion : 2|1@1+ (1,0) [0|1] "Boolean" Vector__XXX
 SG_ MCU_forced_voltage_control : 0|1@1+ (1,0) [0|1] "Boolean" Vector__XXX

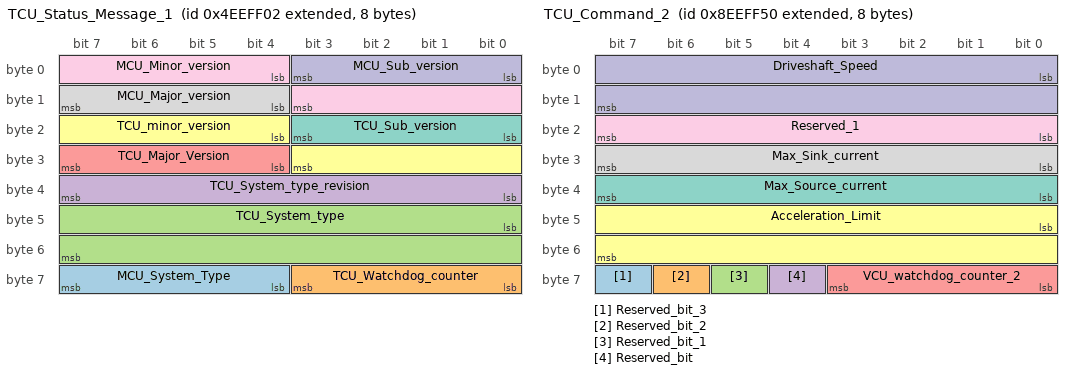
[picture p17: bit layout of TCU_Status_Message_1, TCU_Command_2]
BO_ 2230255362 TCU_Status_Message_1: 8 TCU
 SG_ MCU_System_Type : 60|4@1+ (1,0) [0|15] "Enumeration" Vector__XXX
 SG_ TCU_Watchdog_counter : 56|4@1+ (1,0) [0|15] "Rolling Count" Vector__XXX
 SG_ TCU_System_type : 40|16@1+ (1,0) [0|65535] "Enumeration" Vector__XXX
 SG_ TCU_System_type_revision : 32|8@1+ (1,0) [0|255] "Enumeration" Vector__XXX
 SG_ TCU_Major_Version : 28|4@1+ (1,0) [0|15] "Integer" Vector__XXX
 SG_ TCU_minor_version : 20|8@1+ (1,0) [0|15] "Integer" Vector__XXX
 SG_ TCU_Sub_version : 16|4@1+ (1,0) [0|15] "Integer" Vector__XXX
 SG_ MCU_Major_version : 12|4@1+ (1,0) [0|15] "Integer" Vector__XXX
 SG_ MCU_Minor_version : 4|8@1+ (1,0) [0|15] "Integer" Vector__XXX
 SG_ MCU_Sub_version : 0|4@1+ (1,0) [0|15] "Integer" Vector__XXX

BO_ 2297364304 TCU_Command_2: 8 VCU
 SG_ Reserved_bit_3 : 63|1@1+ (1,0) [0|0] "" Vector__XXX
 SG_ Reserved_bit_2 : 62|1@1+ (1,0) [0|0] "" Vector__XXX
 SG_ Reserved_bit_1 : 61|1@1+ (1,0) [0|0] "" Vector__XXX
 SG_ Reserved_bit : 60|1@1+ (1,0) [0|0] "" Vector__XXX
 SG_ VCU_watchdog_counter_2 : 56|4@1+ (1,0) [0|15] "Counter" Vector__XXX
 SG_ Acceleration_Limit : 40|16@1+ (1,0) [0|32128] "rpm / s" Vector__XXX
 SG_ Max_Source_current : 32|8@1+ (5,0) [0|1275] "Amps" Vector__XXX
 SG_ Max_Sink_current : 24|8@1+ (5,0) [0|1275] "Amps" Vector__XXX
 SG_ Reserved_1 : 16|8@1+ (1,0) [0|255] "" Vector__XXX
 SG_ Driveshaft_Speed : 0|16@1- (1,0) [-16384|16383] "rpm" Vector__XXX

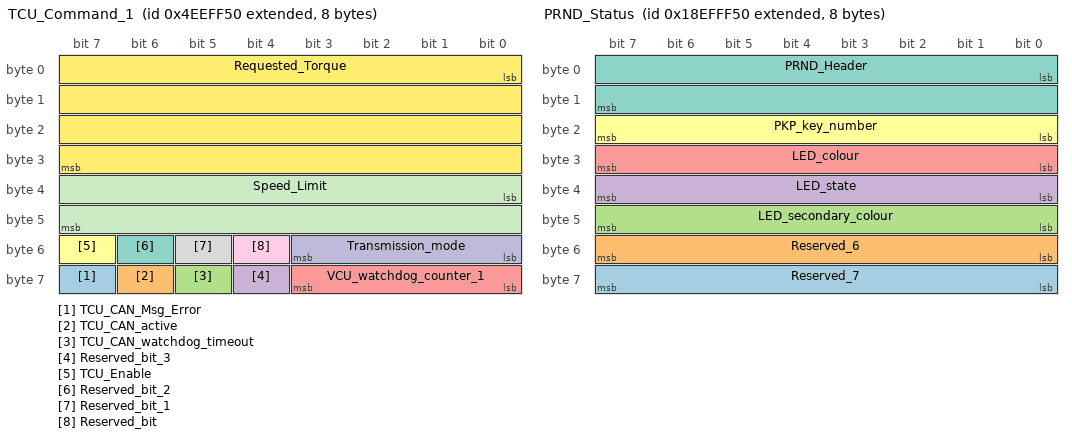
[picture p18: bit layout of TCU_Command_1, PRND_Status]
BO_ 2230255440 TCU_Command_1: 8 VCU
 SG_ TCU_CAN_Msg_Error : 63|1@1+ (1,0) [0|1] "Boolean" Vector__XXX
 SG_ TCU_CAN_active : 62|1@1+ (1,0) [0|1] "Boolean" Vector__XXX
 SG_ TCU_CAN_watchdog_timeout : 61|1@1+ (1,0) [0|1] "Boolean" Vector__XXX
 SG_ Reserved_bit_3 : 60|1@1+ (1,0) [0|0] "" Vector__XXX
 SG_ VCU_watchdog_counter_1 : 56|4@1+ (1,0) [0|15] "Integer" Vector__XXX
 SG_ TCU_Enable : 55|1@1+ (1,0) [0|1] "Boolean" Vector__XXX
 SG_ Reserved_bit_2 : 54|1@1+ (1,0) [0|0] "" Vector__XXX
 SG_ Reserved_bit_1 : 53|1@1+ (1,0) [0|0] "" Vector__XXX
 SG_ Reserved_bit : 52|1@1+ (1,0) [0|0] "" Vector__XXX
 SG_ Transmission_mode : 48|4@1+ (1,0) [0|4] "Enumeration" Vector__XXX
 SG_ Speed_Limit : 32|16@1+ (1,0) [0|4800] "RPM" Vector__XXX
 SG_ Requested_Torque : 0|32@1- (0.1,0) [-6425.6|6425.6] "Nm" Vector__XXX

BO_ 2565865296 PRND_Status: 8 VCU
 SG_ Reserved_7 : 56|8@1+ (1,0) [0|255] "" Vector__XXX
 SG_ Reserved_6 : 48|8@1+ (1,0) [0|255] "" Vector__XXX
 SG_ LED_secondary_colour : 40|8@1+ (1,0) [0|255] "" Vector__XXX
 SG_ LED_state : 32|8@1+ (1,0) [0|255] "" Vector__XXX
 SG_ LED_colour : 24|8@1+ (1,0) [0|255] "" Vector__XXX
 SG_ PKP_key_number : 16|8@1+ (1,0) [0|255] "" Vector__XXX
 SG_ PRND_Header : 0|16@1+ (1,0) [0|65535] "" Vector__XXX

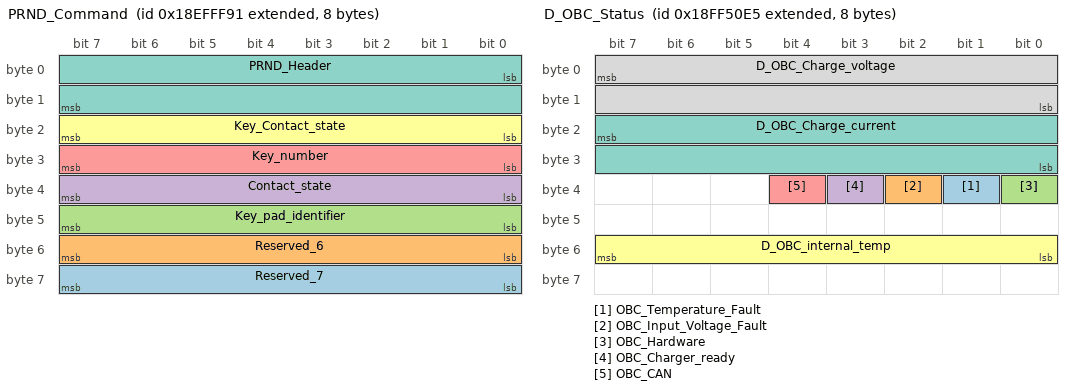
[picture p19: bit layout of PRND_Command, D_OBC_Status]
BO_ 2565865361 PRND_Command: 8 Praker_GW
 SG_ Reserved_7 : 56|8@1+ (1,0) [0|255] "" Vector__XXX
 SG_ Reserved_6 : 48|8@1+ (1,0) [0|255] "" Vector__XXX
 SG_ Key_pad_identifier : 40|8@1+ (1,0) [0|255] "" Vector__XXX
 SG_ Contact_state : 32|8@1+ (1,0) [0|1] "" Vector__XXX
 SG_ Key_number : 24|8@1+ (1,0) [0|255] "" Vector__XXX
 SG_ Key_Contact_state : 16|8@1+ (1,0) [0|255] "" Vector__XXX
 SG_ PRND_Header : 0|16@1+ (1,0) [0|65535] "" Vector__XXX

BO_ 2566869221 D_OBC_Status: 8 OBC_Dilong
 SG_ OBC_Temperature_Fault : 33|1@1+ (1,0) [0|1] "" Vector__XXX
 SG_ OBC_Input_Voltage_Fault : 34|1@1+ (1,0) [0|1] "" Vector__XXX
 SG_ OBC_Hardware : 32|1@1+ (1,0) [0|1] "" Vector__XXX
 SG_ OBC_Charger_ready : 35|1@1+ (1,0) [0|1] "" Vector__XXX
 SG_ OBC_CAN : 36|1@1+ (1,0) [0|1] "" Vector__XXX
 SG_ D_OBC_internal_temp : 48|8@1+ (1,-40) [-40|215] "deg.cel" Vector__XXX
 SG_ D_OBC_Charge_current : 23|16@0+ (0.1,0) [0|6553.5] "A" Vector__XXX
 SG_ D_OBC_Charge_voltage : 7|16@0+ (0.1,0) [0|6553.5] "V" Vector__XXX

BO_ 2550595408 D_OBC_Command: 8 VCU
 SG_ Reserved_7 : 56|8@1+ (1,0) [0|255] "" Vector__XXX
 SG_ Reserved_6 : 48|8@1+ (1,0) [0|255] "" Vector__XXX
 SG_ D_OBC_Mode : 40|8@1+ (1,0) [0|255] "" Vector__XXX
 SG_ D_OBC_Charging_state : 32|8@1+ (1,0) [0|255] "" Vector__XXX
 SG_ D_OBC_Charge_end_current : 16|16@1- (0.1,0) [-3276.8|3276.7] "A" Vector__XXX
 SG_ D_OBC_Charge_end_voltage : 0|16@1+ (0.1,0) [0|6553.5] "V" Vector__XXX

BO_ 2147549040 D_DCDC_Status: 8 DCDC_Dilong
 SG_ D_DCDC_inner_temp : 56|8@1- (1,-40) [-168|87] "Deg cel" Vector__XXX
 SG_ D_DCDC_working_status : 48|8@1+ (1,0) [0|255] "" Vector__XXX
 SG_ D_DCDC_Output_end_voltage : 8|8@1+ (0.2,0) [0|30] "V" Vector__XXX
 SG_ D_DCDC_Output_Current : 32|16@1- (0.1,0) [-3276.8|3276.7] "A" Vector__XXX
 SG_ D_DCDC_Fault : 16|16@1+ (1,0) [0|65535] "" Vector__XXX
 SG_ Reserved_0 : 0|8@1+ (1,0) [0|255] "" Vector__XXX

BO_ 2551250768 D_DCDC_Command: 8 VCU
 SG_ Reserved_7 : 56|8@1+ (1,0) [0|255] "" Vector__XXX
 SG_ Reserved_6 : 48|8@1+ (1,0) [0|255] "" Vector__XXX
 SG_ D_DCDC_Set_Current : 32|16@1- (0.1,0) [-180|180] "A" Vector__XXX
 SG_ D_DCDC_Set_Voltage : 16|16@1+ (0.1,0) [0|30] "V" Vector__XXX
 SG_ D_DCDC_Switch_on_off_control : 8|8@1- (1,0) [-128|127] "" Vector__XXX
 SG_ Reserved_0 : 0|8@1+ (1,0) [0|255] "" Vector__XXX

BO_TX_BU_ 1543 : SME,SME_1;
BA_DEF_ BO_  "GenMsgSendType39" ENUM  "Zyklisch","Ereignisgesteuert","Auf Anfrage","dummy";
BA_DEF_ BO_  "GenMsgSendType38" ENUM  "Zyklisch","Ereignisgesteuert","Auf Anfrage","dummy";
BA_DEF_ BO_  "GenMsgSendType37" ENUM  "Zyklisch","Ereignisgesteuert","Auf Anfrage","dummy";
BA_DEF_ BO_  "GenMsgSendType36" ENUM  "Zyklisch","Ereignisgesteuert","Auf Anfrage","dummy";
BA_DEF_ BO_  "GenMsgSendType35" ENUM  "Zyklisch","Ereignisgesteuert","Auf Anfrage","dummy";
BA_DEF_ BO_  "GenMsgSendType34" ENUM  "Zyklisch","Ereignisgesteuert","Auf Anfrage","dummy";
BA_DEF_ BO_  "GenMsgSendType33" ENUM  "Zyklisch","Ereignisgesteuert","Auf Anfrage","dummy";
BA_DEF_ BO_  "GenMsgSendType32" ENUM  "Zyklisch","Ereignisgesteuert","Auf Anfrage","dummy";
BA_DEF_ BO_  "GenMsgSendType31" ENUM  "Zyklisch","Ereignisgesteuert","Auf Anfrage","dummy";
BA_DEF_ BO_  "GenMsgSendType30" ENUM  "Zyklisch","Ereignisgesteuert","Auf Anfrage","dummy";
BA_DEF_ BO_  "GenMsgSendType29" ENUM  "Zyklisch","Ereignisgesteuert","Auf Anfrage","dummy";
BA_DEF_ BO_  "GenMsgSendType28" ENUM  "Zyklisch","Ereignisgesteuert","Auf Anfrage","dummy";
BA_DEF_ BO_  "GenMsgSendType27" ENUM  "Zyklisch","Ereignisgesteuert","Auf Anfrage","dummy";
BA_DEF_ BO_  "GenMsgSendType26" ENUM  "Zyklisch","Ereignisgesteuert","Auf Anfrage","dummy";
BA_DEF_ BO_  "GenMsgSendType25" ENUM  "Zyklisch","Ereignisgesteuert","Auf Anfrage","dummy";
BA_DEF_ BO_  "GenMsgSendType24" ENUM  "Zyklisch","Ereignisgesteuert","Auf Anfrage","dummy";
BA_DEF_ BO_  "GenMsgSendType23" ENUM  "Zyklisch","Ereignisgesteuert","Auf Anfrage","dummy";
BA_DEF_ BO_  "GenMsgSendType22" ENUM  "Zyklisch","Ereignisgesteuert","Auf Anfrage","dummy";
BA_DEF_ BO_  "GenMsgSendType21" ENUM  "Zyklisch","Ereignisgesteuert","Auf Anfrage","dummy";
BA_DEF_ BO_  "GenMsgSendType20" ENUM  "Zyklisch","Ereignisgesteuert","Auf Anfrage","dummy";
BA_DEF_ BO_  "GenMsgSendType19" ENUM  "Zyklisch","Ereignisgesteuert","Auf Anfrage","dummy";
BA_DEF_ BO_  "GenMsgSendType18" ENUM  "Zyklisch","Ereignisgesteuert","Auf Anfrage","dummy";
BA_DEF_ BO_  "GenMsgSendType17" ENUM  "Zyklisch","Ereignisgesteuert","Auf Anfrage","dummy";
BA_DEF_ BO_  "GenMsgSendType16" ENUM  "Zyklisch","Ereignisgesteuert","Auf Anfrage","dummy";
BA_DEF_ BO_  "GenMsgSendType15" ENUM  "Zyklisch","Ereignisgesteuert","Auf Anfrage","dummy";
BA_DEF_ BO_  "GenMsgSendType14" ENUM  "Zyklisch","Ereignisgesteuert","Auf Anfrage","dummy";
BA_DEF_ BO_  "GenMsgSendType13" ENUM  "Zyklisch","Ereignisgesteuert","Auf Anfrage","dummy";
BA_DEF_ BO_  "GenMsgSendType12" ENUM  "Zyklisch","Ereignisgesteuert","Auf Anfrage","dummy";
BA_DEF_ BO_  "GenMsgSendType11" ENUM  "Zyklisch","Ereignisgesteuert","Auf Anfrage","dummy";
BA_DEF_ BO_  "GenMsgSendType10" ENUM  "Zyklisch","Ereignisgesteuert","Auf Anfrage","dummy";
BA_DEF_ BO_  "GenMsgSendType9" ENUM  "Zyklisch","Ereignisgesteuert","Auf Anfrage","dummy";
BA_DEF_ BO_  "GenMsgSendType8" ENUM  "Zyklisch","Ereignisgesteuert","Auf Anfrage","dummy";
BA_DEF_ BO_  "GenMsgSendType7" ENUM  "Zyklisch","Ereignisgesteuert","Auf Anfrage","dummy";
BA_DEF_ BO_  "GenMsgSendType6" ENUM  "Zyklisch","Ereignisgesteuert","Auf Anfrage","dummy";
BA_DEF_ BO_  "GenMsgSendType5" ENUM  "Zyklisch","Ereignisgesteuert","Auf Anfrage","dummy";
BA_DEF_ BO_  "GenMsgSendType4" ENUM  "Zyklisch","Ereignisgesteuert","Auf Anfrage","dummy";
BA_DEF_ BO_  "GenMsgSendType3" ENUM  "Zyklisch","Ereignisgesteuert","Auf Anfrage","dummy";
BA_DEF_ BO_  "GenMsgSendType2" ENUM  "Zyklisch","Ereignisgesteuert","Auf Anfrage","dummy";
BA_DEF_ SG_  "SigType" ENUM  "Default","Range","RangeSigned","ASCII","Discrete","Control","ReferencePGN","DTC","StringDelimiter","StringLength","StringLengthControl","MessageCounter","MessageChecksum";
BA_DEF_ SG_  "GenSigStartValue" INT 0 2147483647;
BA_DEF_ SG_  "GenSigSendType" ENUM  "Cyclic","OnWrite","OnWriteWithRepetition","OnChange","OnChangeWithRepetition","IfActive","IfActiveWithRepetition","NoSigSendType";
BA_DEF_ SG_  "GenSigILSupport" ENUM  "No","Yes";
BA_DEF_ SG_  "GenSigEVName" STRING ;
BA_DEF_ BO_  "GenMsgStartDelayTime" INT 0 100000;
BA_DEF_ BO_  "GenMsgILSupport" ENUM  "No","Yes";
BA_DEF_ BO_  "GenMsgRequestable" INT 0 1;
BA_DEF_ BO_  "GenMsgSendType" ENUM  "cyclic","NotUsed","NotUsed","NotUsed","NotUsed","NotUsed","NotUsed","IfActive","noMsgSendType";
BA_DEF_ BO_  "VFrameFormat" ENUM  "StandardCAN","ExtendedCAN","reserved","J1939PG";
BA_DEF_ BO_  "GenMsgCycleTime" INT 0 3600000;
BA_DEF_DEF_  "GenMsgSendType39" "Zyklisch";
BA_DEF_DEF_  "GenMsgSendType38" "Zyklisch";
BA_DEF_DEF_  "GenMsgSendType37" "Zyklisch";
BA_DEF_DEF_  "GenMsgSendType36" "Zyklisch";
BA_DEF_DEF_  "GenMsgSendType35" "Zyklisch";
BA_DEF_DEF_  "GenMsgSendType34" "Zyklisch";
BA_DEF_DEF_  "GenMsgSendType33" "Zyklisch";
BA_DEF_DEF_  "GenMsgSendType32" "Zyklisch";
BA_DEF_DEF_  "GenMsgSendType31" "Zyklisch";
BA_DEF_DEF_  "GenMsgSendType30" "Zyklisch";
BA_DEF_DEF_  "GenMsgSendType29" "Zyklisch";
BA_DEF_DEF_  "GenMsgSendType28" "Zyklisch";
BA_DEF_DEF_  "GenMsgSendType27" "Zyklisch";
BA_DEF_DEF_  "GenMsgSendType26" "Zyklisch";
BA_DEF_DEF_  "GenMsgSendType25" "Zyklisch";
BA_DEF_DEF_  "GenMsgSendType24" "Zyklisch";
BA_DEF_DEF_  "GenMsgSendType23" "Zyklisch";
BA_DEF_DEF_  "GenMsgSendType22" "Zyklisch";
BA_DEF_DEF_  "GenMsgSendType21" "Zyklisch";
BA_DEF_DEF_  "GenMsgSendType20" "Zyklisch";
BA_DEF_DEF_  "GenMsgSendType19" "Zyklisch";
BA_DEF_DEF_  "GenMsgSendType18" "Zyklisch";
BA_DEF_DEF_  "GenMsgSendType17" "Zyklisch";
BA_DEF_DEF_  "GenMsgSendType16" "Zyklisch";
BA_DEF_DEF_  "GenMsgSendType15" "Zyklisch";
BA_DEF_DEF_  "GenMsgSendType14" "Zyklisch";
BA_DEF_DEF_  "GenMsgSendType13" "Zyklisch";
BA_DEF_DEF_  "GenMsgSendType12" "Zyklisch";
BA_DEF_DEF_  "GenMsgSendType11" "Zyklisch";
BA_DEF_DEF_  "GenMsgSendType10" "Zyklisch";
BA_DEF_DEF_  "GenMsgSendType9" "Zyklisch";
BA_DEF_DEF_  "GenMsgSendType8" "Zyklisch";
BA_DEF_DEF_  "GenMsgSendType7" "Zyklisch";
BA_DEF_DEF_  "GenMsgSendType6" "Zyklisch";
BA_DEF_DEF_  "GenMsgSendType5" "Zyklisch";
BA_DEF_DEF_  "GenMsgSendType4" "Zyklisch";
BA_DEF_DEF_  "GenMsgSendType3" "Zyklisch";
BA_DEF_DEF_  "GenMsgSendType2" "Zyklisch";
BA_DEF_DEF_  "SigType" "Default";
BA_DEF_DEF_  "GenSigStartValue" 0;
BA_DEF_DEF_  "GenSigSendType" "NoSigSendType";
BA_DEF_DEF_  "GenSigILSupport" "Yes";
BA_DEF_DEF_  "GenSigEVName" "Env@Nodename_@Signame";
BA_DEF_DEF_  "GenMsgStartDelayTime" 0;
BA_DEF_DEF_  "GenMsgILSupport" "Yes";
BA_DEF_DEF_  "GenMsgRequestable" 1;
BA_DEF_DEF_  "GenMsgSendType" "noMsgSendType";
BA_DEF_DEF_  "VFrameFormat" "J1939PG";
BA_DEF_DEF_  "GenMsgCycleTime" 0;
BA_ "GenMsgSendType" BO_ 2566861442 0;
BA_ "GenMsgCycleTime" BO_ 2566861442 200;
BA_ "GenMsgSendType" BO_ 2566873730 0;
BA_ "GenMsgCycleTime" BO_ 2566873730 200;
BA_ "GenMsgSendType" BO_ 2566873986 0;
BA_ "GenMsgCycleTime" BO_ 2566873986 200;
BA_ "GenMsgSendType" BO_ 2566875010 0;
BA_ "GenMsgCycleTime" BO_ 2566875010 200;
BA_ "GenMsgCycleTime" BO_ 2566874754 200;
BA_ "GenMsgSendType" BO_ 2566874754 0;
BA_ "GenMsgCycleTime" BO_ 2566875266 200;
BA_ "GenMsgSendType" BO_ 2566875266 0;
BA_ "GenMsgSendType" BO_ 2566865654 0;
BA_ "GenMsgCycleTime" BO_ 2566865654 100;
BA_ "GenMsgSendType" BO_ 2566865398 0;
BA_ "GenMsgCycleTime" BO_ 2566865398 10;
BA_ "GenMsgSendType" BO_ 2566866174 0;
BA_ "GenMsgCycleTime" BO_ 2566866174 10;
BA_ "GenMsgCycleTime" BO_ 2566746257 1000;
BA_ "GenMsgSendType" BO_ 2566746257 0;
BA_ "GenMsgCycleTime" BO_ 2566759825 100;
BA_ "GenMsgSendType" BO_ 2566759825 0;
BA_ "GenMsgCycleTime" BO_ 2365449873 100;
BA_ "GenMsgSendType" BO_ 2365449873 0;
BA_ "GenMsgSendType" BO_ 2566906513 0;
BA_ "GenMsgCycleTime" BO_ 2566906513 1000;
BA_ "GenMsgSendType" BO_ 2550588916 0;
BA_ "GenMsgCycleTime" BO_ 2550588916 1000;
BA_ "GenMsgSendType" BO_ 2349399888 0;
BA_ "GenMsgCycleTime" BO_ 2349399888 100;
BA_ "GenMsgSendType" BO_ 2349334352 0;
BA_ "GenMsgCycleTime" BO_ 2349334352 100;
BA_ "GenMsgSendType" BO_ 2365538503 0;
BA_ "GenMsgCycleTime" BO_ 2365538503 100;
BA_ "GenMsgSendType" BO_ 2566863234 0;
BA_ "GenMsgCycleTime" BO_ 2566863234 200;
BA_ "GenMsgCycleTime" BO_ 2566862978 200;
BA_ "GenMsgSendType" BO_ 2566862978 0;
BA_ "GenMsgSendType" BO_ 2633990274 0;
BA_ "GenMsgCycleTime" BO_ 2633990274 100;
BA_ "GenMsgSendType" BO_ 2566860930 0;
BA_ "GenMsgCycleTime" BO_ 2566860930 200;
BA_ "GenMsgSendType" BO_ 2566861186 0;
BA_ "GenMsgCycleTime" BO_ 2566861186 200;
BA_ "GenMsgSendType" BO_ 2566861698 0;
BA_ "GenMsgCycleTime" BO_ 2566861698 200;
BA_ "GenMsgSendType" BO_ 2566861954 0;
BA_ "GenMsgCycleTime" BO_ 2566861954 200;
BA_ "GenMsgSendType" BO_ 2566862722 0;
BA_ "GenMsgCycleTime" BO_ 2566862722 200;
BA_ "GenMsgSendType" BO_ 2566862466 0;
BA_ "GenMsgCycleTime" BO_ 2566862466 200;
BA_ "GenMsgSendType" BO_ 2566862210 0;
BA_ "GenMsgCycleTime" BO_ 2566862210 200;
BA_ "GenMsgSendType" BO_ 2566865026 0;
BA_ "GenMsgCycleTime" BO_ 2566865026 200;
BA_ "GenMsgSendType" BO_ 2566856834 0;
BA_ "GenMsgCycleTime" BO_ 2566856834 250;
BA_ "GenMsgSendType" BO_ 2566855552 0;
BA_ "GenMsgCycleTime" BO_ 2566855552 1000;
BA_ "GenMsgSendType" BO_ 2566872192 0;
BA_ "GenMsgCycleTime" BO_ 2566872192 500;
BA_ "GenMsgSendType" BO_ 2566872960 0;
BA_ "GenMsgCycleTime" BO_ 2566872960 1000;
BA_ "GenMsgSendType" BO_ 2566872704 0;
BA_ "GenMsgCycleTime" BO_ 2566872704 1000;
BA_ "GenMsgSendType" BO_ 2566854272 0;
BA_ "GenMsgCycleTime" BO_ 2566854272 500;
BA_ "GenMsgSendType" BO_ 2566853248 0;
BA_ "GenMsgCycleTime" BO_ 2566853248 10;
BA_ "GenMsgSendType" BO_ 2566852992 0;
BA_ "GenMsgCycleTime" BO_ 2566852992 10;
BA_ "GenMsgSendType" BO_ 2566852736 0;
BA_ "GenMsgCycleTime" BO_ 2566852736 10;
BA_ "GenMsgSendType" BO_ 2566854016 0;
BA_ "GenMsgCycleTime" BO_ 2566854016 500;
BA_ "GenMsgSendType" BO_ 2566873472 0;
BA_ "GenMsgCycleTime" BO_ 2566873472 500;
BA_ "GenMsgSendType" BO_ 2566874240 0;
BA_ "GenMsgCycleTime" BO_ 2566874240 500;
BA_ "GenMsgSendType" BO_ 2566874496 0;
BA_ "GenMsgCycleTime" BO_ 2566874496 500;
BA_ "GenMsgSendType" BO_ 2566854784 0;
BA_ "GenMsgCycleTime" BO_ 2566854784 10;
BA_ "GenMsgSendType" BO_ 2566855040 0;
BA_ "GenMsgCycleTime" BO_ 2566855040 10;
BA_ "GenMsgSendType" BO_ 2566855296 0;
BA_ "GenMsgCycleTime" BO_ 2566855296 10;
BA_ "GenMsgSendType" BO_ 2566853504 0;
BA_ "GenMsgCycleTime" BO_ 2566853504 10;
BA_ "GenMsgSendType" BO_ 2566857090 0;
BA_ "GenMsgCycleTime" BO_ 2566857090 20;
BA_ "GenMsgCycleTime" BO_ 2566872448 500;
BA_ "GenMsgSendType" BO_ 2566872448 0;
BA_ "GenMsgSendType" BO_ 2566869120 0;
BA_ "GenMsgCycleTime" BO_ 2566869120 500;
BA_ "GenMsgSendType" BO_ 2566871680 0;
BA_ "GenMsgCycleTime" BO_ 2566871680 500;
BA_ "GenMsgSendType" BO_ 2566871424 0;
BA_ "GenMsgCycleTime" BO_ 2566871424 500;
BA_ "GenMsgSendType" BO_ 2566871168 0;
BA_ "GenMsgCycleTime" BO_ 2566871168 500;
BA_ "GenMsgSendType" BO_ 2566870912 0;
BA_ "GenMsgCycleTime" BO_ 2566870912 500;
BA_ "GenMsgSendType" BO_ 2566870656 0;
BA_ "GenMsgCycleTime" BO_ 2566870656 500;
BA_ "GenMsgSendType" BO_ 2566870400 0;
BA_ "GenMsgCycleTime" BO_ 2566870400 500;
BA_ "GenMsgSendType" BO_ 2566870144 0;
BA_ "GenMsgCycleTime" BO_ 2566870144 500;
BA_ "GenMsgSendType" BO_ 2566869888 0;
BA_ "GenMsgCycleTime" BO_ 2566869888 500;
BA_ "GenMsgSendType" BO_ 2566869632 0;
BA_ "GenMsgCycleTime" BO_ 2566869632 500;
BA_ "GenMsgSendType" BO_ 2566869376 0;
BA_ "GenMsgCycleTime" BO_ 2566869376 500;
BA_ "GenMsgSendType" BO_ 2566871936 0;
BA_ "GenMsgCycleTime" BO_ 2566871936 500;
BA_ "GenMsgSendType" BO_ 2566853760 0;
BA_ "GenMsgCycleTime" BO_ 2566853760 10;
BA_ "GenMsgSendType" BO_ 2566854528 0;
BA_ "GenMsgCycleTime" BO_ 2566854528 20;
BA_ "GenMsgCycleTime" BO_ 2566844817 100;
BA_ "GenMsgSendType" BO_ 2566844817 0;
BA_ "GenMsgCycleTime" BO_ 2564882321 1000;
BA_ "GenMsgSendType" BO_ 2564882321 0;
BA_ "GenMsgCycleTime" BO_ 2565865808 100;
BA_ "GenMsgSendType" BO_ 2565865808 0;
BA_ "VFrameFormat" BO_ 1603 0;
BA_ "VFrameFormat" BO_ 1602 0;
BA_ "VFrameFormat" BO_ 1601 0;
BA_ "VFrameFormat" BO_ 1543 0;
BA_ "VFrameFormat" BO_ 1777 0;
BA_ "GenMsgCycleTime" BO_ 767 100;
BA_ "GenMsgSendType" BO_ 767 0;
BA_ "VFrameFormat" BO_ 767 0;
BA_ "GenMsgCycleTime" BO_ 1415 5000;
BA_ "GenMsgSendType" BO_ 1415 0;
BA_ "VFrameFormat" BO_ 1415 0;
BA_ "VFrameFormat" BO_ 1424 0;
BA_ "GenMsgCycleTime" BO_ 1306 640;
BA_ "GenMsgSendType" BO_ 1306 0;
BA_ "VFrameFormat" BO_ 1306 0;
BA_ "GenMsgCycleTime" BO_ 1434 5000;
BA_ "GenMsgSendType" BO_ 1434 0;
BA_ "VFrameFormat" BO_ 1434 0;
BA_ "GenMsgCycleTime" BO_ 970 1000;
BA_ "GenMsgSendType" BO_ 970 0;
BA_ "VFrameFormat" BO_ 970 0;
BA_ "GenMsgCycleTime" BO_ 928 5000;
BA_ "GenMsgSendType" BO_ 928 0;
BA_ "VFrameFormat" BO_ 928 0;
BA_ "GenMsgCycleTime" BO_ 816 10000;
BA_ "GenMsgSendType" BO_ 816 0;
BA_ "VFrameFormat" BO_ 816 0;
BA_ "GenMsgCycleTime" BO_ 808 1000;
BA_ "GenMsgSendType" BO_ 808 0;
BA_ "VFrameFormat" BO_ 808 0;
BA_ "GenMsgCycleTime" BO_ 714 1000;
BA_ "GenMsgSendType" BO_ 714 0;
BA_ "VFrameFormat" BO_ 714 0;
BA_ "GenMsgCycleTime" BO_ 417 20;
BA_ "GenMsgSendType" BO_ 417 0;
BA_ "VFrameFormat" BO_ 417 0;
BA_ "GenMsgCycleTime" BO_ 414 500;
BA_ "GenMsgSendType" BO_ 414 0;
BA_ "VFrameFormat" BO_ 414 0;
BA_ "GenMsgCycleTime" BO_ 411 200;
BA_ "GenMsgSendType" BO_ 411 0;
BA_ "VFrameFormat" BO_ 411 0;
BA_ "GenMsgCycleTime" BO_ 303 20;
BA_ "GenMsgSendType" BO_ 303 0;
BA_ "VFrameFormat" BO_ 303 0;
BA_ "GenMsgCycleTime" BO_ 267 20;
BA_ "GenMsgSendType" BO_ 267 0;
BA_ "VFrameFormat" BO_ 267 0;
BA_ "GenMsgCycleTime" BO_ 264 100;
BA_ "GenMsgSendType" BO_ 264 0;
BA_ "VFrameFormat" BO_ 264 0;
BA_ "GenMsgCycleTime" BO_ 1075 1000;
BA_ "GenMsgSendType" BO_ 1075 0;
BA_ "VFrameFormat" BO_ 1075 0;
BA_ "GenMsgCycleTime" BO_ 1001 200;
BA_ "GenMsgSendType" BO_ 1001 0;
BA_ "VFrameFormat" BO_ 1001 0;
BA_ "GenMsgCycleTime" BO_ 891 10000;
BA_ "GenMsgSendType" BO_ 891 0;
BA_ "VFrameFormat" BO_ 891 0;
BA_ "GenMsgCycleTime" BO_ 1065 1000;
BA_ "GenMsgSendType" BO_ 1065 0;
BA_ "VFrameFormat" BO_ 1065 0;
BA_ "GenMsgCycleTime" BO_ 515 1000;
BA_ "GenMsgSendType" BO_ 515 0;
BA_ "VFrameFormat" BO_ 515 0;
BA_ "GenMsgCycleTime" BO_ 1287 640;
BA_ "GenMsgSendType" BO_ 1287 0;
BA_ "VFrameFormat" BO_ 1287 0;
BA_ "VFrameFormat" BO_ 1413 0;
BA_ "GenMsgCycleTime" BO_ 757 100;
BA_ "GenMsgSendType" BO_ 757 0;
BA_ "VFrameFormat" BO_ 757 0;
BA_ "GenMsgCycleTime" BO_ 569 200;
BA_ "GenMsgSendType" BO_ 569 0;
BA_ "VFrameFormat" BO_ 569 0;
BA_ "GenMsgCycleTime" BO_ 274 10;
BA_ "GenMsgSendType" BO_ 274 0;
BA_ "VFrameFormat" BO_ 274 0;
BA_ "GenMsgCycleTime" BO_ 1073 200;
BA_ "GenMsgSendType" BO_ 1073 0;
BA_ "VFrameFormat" BO_ 1073 0;
BA_ "GenMsgCycleTime" BO_ 1052 1000;
BA_ "GenMsgSendType" BO_ 1052 0;
BA_ "VFrameFormat" BO_ 1052 0;
BA_ "GenMsgCycleTime" BO_ 1037 1000;
BA_ "GenMsgSendType" BO_ 1037 0;
BA_ "VFrameFormat" BO_ 1037 0;
BA_ "GenMsgSendType" BO_ 1074 0;
BA_ "VFrameFormat" BO_ 1074 0;
BA_ "GenMsgCycleTime" BO_ 1074 200;
BA_ "GenMsgSendType" BO_ 506 0;
BA_ "VFrameFormat" BO_ 506 0;
BA_ "GenMsgCycleTime" BO_ 506 1000;
BA_ "GenMsgCycleTime" BO_ 2365541622 10;
BA_ "GenMsgSendType" BO_ 2365541622 0;
BA_ "GenMsgCycleTime" BO_ 2632908546 50;
BA_ "GenMsgSendType" BO_ 2632908546 0;
BA_ "GenMsgCycleTime" BO_ 2565799682 50;
BA_ "GenMsgSendType" BO_ 2565799682 0;
BA_ "GenMsgCycleTime" BO_ 2498690818 50;
BA_ "GenMsgSendType" BO_ 2498690818 0;
BA_ "GenMsgCycleTime" BO_ 2431581954 50;
BA_ "GenMsgSendType" BO_ 2431581954 0;
BA_ "GenMsgCycleTime" BO_ 2364473090 50;
BA_ "GenMsgSendType" BO_ 2364473090 0;
BA_ "GenMsgCycleTime" BO_ 2297364226 50;
BA_ "GenMsgSendType" BO_ 2297364226 0;
BA_ "GenMsgCycleTime" BO_ 2230255362 50;
BA_ "GenMsgSendType" BO_ 2230255362 0;
BA_ "GenMsgCycleTime" BO_ 2297364304 50;
BA_ "GenMsgSendType" BO_ 2297364304 0;
BA_ "GenMsgCycleTime" BO_ 2230255440 50;
BA_ "GenMsgSendType" BO_ 2230255440 0;
BA_ "GenMsgSendType" BO_ 2565865296 0;
BA_ "GenMsgCycleTime" BO_ 2565865296 50;
BA_ "GenMsgCycleTime" BO_ 2565865361 100;
BA_ "GenMsgSendType" BO_ 2565865361 0;
BA_ "GenMsgSendType" BO_ 2566869221 0;
BA_ "GenMsgCycleTime" BO_ 2566869221 1000;
BA_ "GenMsgSendType" BO_ 2550595408 0;
BA_ "GenMsgCycleTime" BO_ 2550595408 1000;
BA_ "GenMsgCycleTime" BO_ 2147549040 200;
BA_ "GenMsgSendType" BO_ 2147549040 0;
BA_ "GenMsgSendType" BO_ 2551250768 0;
BA_ "GenMsgCycleTime" BO_ 2551250768 200;
BA_ "GenSigStartValue" SG_ 2566906513 Ambient_Temperature 40;
BA_ "GenSigSendType" SG_ 2550588916 Mode 0;
BA_ "GenSigSendType" SG_ 2550588916 BMS_Control 0;
BA_ "GenSigSendType" SG_ 2550588916 Set_Current 0;
BA_ "GenSigSendType" SG_ 2550588916 Set_voltage 0;
BA_ "GenSigStartValue" SG_ 2566860930 V2G_StateM_EnergyTransfer_mode 15;
BA_ "GenSigStartValue" SG_ 2566860930 V2G_EVPower_deliveryparamtrflag 3;
BA_ "GenSigStartValue" SG_ 2566860930 V2G_EV_RESSconditing_flag 3;
BA_ "GenSigStartValue" SG_ 2566860930 V2G_EV_RESSconditing 3;
BA_ "GenSigStartValue" SG_ 2566860930 V2G_EV_Ready 3;
BA_ "GenSigStartValue" SG_ 2566860930 V2G_EVCabin_conditioning_flag 3;
BA_ "GenSigStartValue" SG_ 2566860930 V2G_EVCabin_conditioning 3;
BA_ "GenSigStartValue" SG_ 2566860930 V2G_charging_complete 3;
BA_ "GenSigStartValue" SG_ 2566860930 V2G_FullSOC_flag 3;
BA_ "GenSigStartValue" SG_ 2566860930 V2G_BulkSOC_flag 3;
BA_ "GenSigStartValue" SG_ 2566860930 V2G_Bulkcharging_Complete_flag 3;
BA_ "GenSigStartValue" SG_ 2566860930 V2G_Bulkcharging_Complete 3;
BA_ "GenSigStartValue" SG_ 2566860930 V2G_EV_Error_Code 15;
BA_ "GenSigStartValue" SG_ 2566856834 Inletmotor_Request 3;
BA_ "GenSigStartValue" SG_ 2566856834 Chargeunit_Request 3;
BA_ "GenSigStartValue" SG_ 2566856834 RTC_timervalue 255;
BA_ "GenSigStartValue" SG_ 2566856834 Highsideoutput4_Request 3;
BA_ "GenSigStartValue" SG_ 2566856834 PlugLock_motor_request 7;
BA_ "GenSigStartValue" SG_ 2566856834 Highsideoutput3_Request 3;
BA_ "GenSigStartValue" SG_ 2566856834 Highsideoutput2_Request 3;
BA_ "GenSigStartValue" SG_ 2566856834 Highsideoutput1_Request 3;
BA_ "GenSigStartValue" SG_ 2566856834 Highsideoutput0_Request 3;
BA_ "GenSigStartValue" SG_ 2566856834 LED2_Request 255;
BA_ "GenSigStartValue" SG_ 2566856834 LED1_Request 255;
BA_ "GenSigStartValue" SG_ 2566856834 LED0_Request 255;
BA_ "GenSigStartValue" SG_ 2566855552 VCVCCU_V2ICP_AmbientTemperature 127;
BA_ "GenSigStartValue" SG_ 2566855552 VCVCCU_V2ICP_PrecnditinigDesire 255;
BA_ "GenSigStartValue" SG_ 2566855552 VCVCCU_V2ICP_PrecndtnDesireHVAC 3;
BA_ "GenSigStartValue" SG_ 2566855552 VCVCCU_V2ICP_SchdulDepartureTime 65535;
BA_ "GenSigStartValue" SG_ 2566854272 VCVCCU_RTC_Wakeup 3;
BA_ "GenSigStartValue" SG_ 2566854272 VCVCCU_RTC_TimerStatus 3;
BA_ "GenSigStartValue" SG_ 2566853248 VCVCCU_PTC2_SelfDiagnosticStatus 7;
BA_ "GenSigStartValue" SG_ 2566853248 VCVCCU_PTC2_Temperature 65535;
BA_ "GenSigStartValue" SG_ 2566853248 VCVCCU_PTC2_Resistance 65535;
BA_ "GenSigStartValue" SG_ 2566853248 VCVCCU_PTC2_Raw 65535;
BA_ "GenSigStartValue" SG_ 2566852992 VCVCCU_PTC1_SelfDiagnosticStatus 7;
BA_ "GenSigStartValue" SG_ 2566852992 VCVCCU_PTC1_Temperature 65535;
BA_ "GenSigStartValue" SG_ 2566852992 VCVCCU_PTC1_Resistance 65535;
BA_ "GenSigStartValue" SG_ 2566852992 VCVCCU_PTC1_Raw 65535;
BA_ "GenSigStartValue" SG_ 2566852736 VCVCCU_PTC0_SelfDiagnosticStatus 7;
BA_ "GenSigStartValue" SG_ 2566852736 VCVCCU_PTC0_Temperature 65535;
BA_ "GenSigStartValue" SG_ 2566852736 VCVCCU_PTC0_Resistance 65533;
BA_ "GenSigStartValue" SG_ 2566852736 VCVCCU_PTC0_Raw 65533;
BA_ "GenSigStartValue" SG_ 2566854016 VCVCCU_HighSideOut4_Input_Status 3;
BA_ "GenSigStartValue" SG_ 2566854016 VCVCCU_HighSideOut3_Input_Wakeup 3;
BA_ "GenSigStartValue" SG_ 2566854016 VCVCCU_HghSdeOut4_Ip_DebonceStat 3;
BA_ "GenSigStartValue" SG_ 2566854016 VCVCCU_HighSideOut3_Input_Status 3;
BA_ "GenSigStartValue" SG_ 2566854016 VCVCCU_HghSdeOut3_Ip_DebuncStats 3;
BA_ "GenSigStartValue" SG_ 2566854016 VCVCCU_HighSideOut2_Input_Status 3;
BA_ "GenSigStartValue" SG_ 2566854016 VCVCCU_HghSdeOut2_Ip_DebuncStats 3;
BA_ "GenSigStartValue" SG_ 2566854016 VCVCCU_HighSideOut1_Input_Status 3;
BA_ "GenSigStartValue" SG_ 2566854016 VCVCCU_HghsdeOut1_Ip_DebunceStat 3;
BA_ "GenSigStartValue" SG_ 2566854016 VCVCCU_HighSideOut0_Ip_Stats 3;
BA_ "GenSigStartValue" SG_ 2566854016 VCVCCU_HghSdeOut0_Ip_DeboncStats 3;
BA_ "GenSigStartValue" SG_ 2566854016 VCVCCU_LED2_SelfDiagnosticStatus 7;
BA_ "GenSigStartValue" SG_ 2566854016 VCVCCU_LED1_SelfDiagnosticStatus 7;
BA_ "GenSigStartValue" SG_ 2566854016 VCVCCU_LED0_SelfDiagStatus 7;
BA_ "GenSigStartValue" SG_ 2566854016 VCVCCU_HghSdeOut4_SelfDiagStatus 7;
BA_ "GenSigStartValue" SG_ 2566854016 VCVCCU_HghSdeOut3_SelfDiagStatus 7;
BA_ "GenSigStartValue" SG_ 2566854016 VCVCCU_HghSdeOut2_SelfDiagStatus 7;
BA_ "GenSigStartValue" SG_ 2566854016 VCVCCU_HghSdeOut1_SelfDiagStatus 7;
BA_ "GenSigStartValue" SG_ 2566854016 VCVCCU_HghSieOut0_SelfDiagStatus 7;
BA_ "GenSigStartValue" SG_ 2566874240 LIN_SeFrequency 255;
BA_ "GenSigStartValue" SG_ 2566874496 LIN_SeMaxCurrentN 255;
BA_ "GenSigStartValue" SG_ 2566874496 LIN_SeMaxCurrentL3 255;
BA_ "GenSigStartValue" SG_ 2566874496 LIN_SeMaxCurrentL2 255;
BA_ "GenSigStartValue" SG_ 2566874496 LIN_SeMaxCurrentL1 255;
BA_ "GenSigStartValue" SG_ 2566854784 SS_Voltage 65535;
BA_ "GenSigStartValue" SG_ 2566854784 Internal_VCC_KL30_Voltage 65535;
BA_ "GenSigStartValue" SG_ 2566854784 Internal_VCC_KL15_Voltage 65535;
BA_ "GenSigStartValue" SG_ 2566854784 Internal_VCC_12v_Voltage 65535;
BA_ "GenSigStartValue" SG_ 2566855040 SS_Raw 65535;
BA_ "GenSigStartValue" SG_ 2566855040 Internal_VCC_KL30_Raw 65535;
BA_ "GenSigStartValue" SG_ 2566855040 Internal_VCC_KL15_Raw 65535;
BA_ "GenSigStartValue" SG_ 2566855040 Internal_VCC_12v_Raw 65535;
BA_ "GenSigStartValue" SG_ 2566855296 ProtectiveEarth_Offset 65535;
BA_ "GenSigStartValue" SG_ 2566855296 VCVCCU_ControlPilot_MinVoltage 65535;
BA_ "GenSigStartValue" SG_ 2566855296 Plug_present_voltage 65535;
BA_ "GenSigStartValue" SG_ 2566853504 S3Switch_debounce_state 3;
BA_ "GenSigStartValue" SG_ 2566853504 S3Switch_status 3;
BA_ "GenSigStartValue" SG_ 2566853504 Inlet_connection_status 3;
BA_ "GenSigStartValue" SG_ 2566853504 Digital_input_debounce_state 3;
BA_ "GenSigStartValue" SG_ 2566853504 Inlet_max_current 255;
BA_ "GenSigStartValue" SG_ 2566853504 Inlet_motor_status 7;
BA_ "GenSigStartValue" SG_ 2566853504 Digital_input_wakeup 3;
BA_ "GenSigStartValue" SG_ 2566853504 Digital_input_status 3;
BA_ "GenSigStartValue" SG_ 2566853504 Inlet_HW_variant 3;
BA_ "GenSigStartValue" SG_ 2566853504 Pluglock_output1_selfdiag_status 7;
BA_ "GenSigStartValue" SG_ 2566853504 Pluglock_output0_selfdiag_status 7;
BA_ "GenSigStartValue" SG_ 2566853504 Plug_lock_motorstatus 7;
BA_ "GenSigStartValue" SG_ 2566853504 POSF_present_selfdiag_status 7;
BA_ "GenSigStartValue" SG_ 2566853504 Plug_present_wakeup 3;
BA_ "GenSigStartValue" SG_ 2566853504 Plug_present_status 3;
BA_ "GenSigStartValue" SG_ 2566853504 Plug_present_resistance 7;
BA_ "GenSigStartValue" SG_ 2566853504 Plug_present_selfdiag_status 7;
BA_ "GenSigStartValue" SG_ 2566853504 POS_Feedback_voltage 65535;
BA_ "GenSigStartValue" SG_ 2633990272 WakeupRsn_VCVCCU 255;
BA_ "GenSigStartValue" SG_ 2566857090 VCVCCU_Vehicle_StopCharge 3;
BA_ "GenSigStartValue" SG_ 2566857090 VCVCCU_Vehicle_Renegotiate 3;
BA_ "GenSigStartValue" SG_ 2566857090 Vehicle_PwmChargeModeRequest 3;
BA_ "GenSigStartValue" SG_ 2566857090 E2E_CRC_ChargeFromVehicle 255;
BA_ "GenSigStartValue" SG_ 2566857090 Vehicle_contactor_status 3;
BA_ "GenSigStartValue" SG_ 2566857090 Vehicle_charge_permission 3;
BA_ "GenSigStartValue" SG_ 2566857090 Vehicle_plugunlock_permission 3;
BA_ "GenSigStartValue" SG_ 2566857090 Vehicle_pluglock_permission 3;
BA_ "GenSigStartValue" SG_ 2566857090 Vehicle_isolation_mesurmntStatus 3;
BA_ "GenSigStartValue" SG_ 2566857090 Vehicle_link_voltage 65535;
BA_ "GenSigStartValue" SG_ 2566857090 Vehicle_contactor_voltage 65535;
BA_ "GenSigStartValue" SG_ 2566869120 V2G_EVSEDateTimeNowFlag 3;
BA_ "GenSigStartValue" SG_ 2566869120 V2G_EVSEIsolationStatusFlag 3;
BA_ "GenSigStartValue" SG_ 2566869120 V2G_EVSECurrentLimitAchieved 3;
BA_ "GenSigStartValue" SG_ 2566853760 ChargeUnit_MaxCurrent 255;
BA_ "GenSigStartValue" SG_ 2566853760 ChargeUnit_State 7;
BA_ "GenSigStartValue" SG_ 2566853760 ChargeUnit_Mode 7;
BA_ "GenSigStartValue" SG_ 2566853760 ControlPilot_Wakeup 3;
BA_ "GenSigStartValue" SG_ 2566853760 ControlPilot_Voltage 65535;
BA_ "GenSigStartValue" SG_ 2566853760 ControlPilot_DutyCycle 255;
BA_ "GenSigStartValue" SG_ 2566853760 ControlPilot_Frequency 65535;
BA_ "GenSigStartValue" SG_ 2566854528 E2E_CRC_ChargeToVehicle 255;
BA_ "GenSigStartValue" SG_ 2566854528 VCVCCU_Vehcle_MobilizatnStatus 3;
BA_ "GenSigStartValue" SG_ 2566854528 VCVCCU_Vehicle_ChargingStatus 3;
BA_ "GenSigStartValue" SG_ 2566854528 VCVCCU_Vehcle_ChageSelctnAck 3;
BA_ "GenSigStartValue" SG_ 2566854528 Vehicle_IsolationMeasurementReq 3;
BA_ "GenSigStartValue" SG_ 2566834816 DTC_SPN_ConvMd_VCCU 1;
BA_ "GenSigStartValue" SG_ 2566834816 DTC_OccCnt_VCCU 127;
BA_ "GenSigStartValue" SG_ 2566834816 DTC_SPN_VCCU 524287;
BA_ "GenSigStartValue" SG_ 2566834816 DTC_FailModeID_VCCU 31;
BA_ "GenSigStartValue" SG_ 2566834816 DTC_MIL_Flash_Stat_VCCU 3;
BA_ "GenSigStartValue" SG_ 2566834816 DTC_RSL_Flash_Stat_VCCU 3;
BA_ "GenSigStartValue" SG_ 2566834816 DTC_AWL_Flash_Stat_VCCU 3;
BA_ "GenSigStartValue" SG_ 2566834816 DTC_PL_Flash_Stat_VCCU 3;
BA_ "GenSigStartValue" SG_ 2566834816 DTC_MIL_Stat_VCCU 3;
BA_ "GenSigStartValue" SG_ 2566834816 DTC_RSL_Stat_VCCU 3;
BA_ "GenSigStartValue" SG_ 2566834816 DTC_AWL_Stat_VCCU 3;
BA_ "GenSigStartValue" SG_ 2566834816 DTC_PL_Stat_VCCU 3;
BA_ "GenSigStartValue" SG_ 767 DUMMY_SIG_50 255;
BA_ "GenSigStartValue" SG_ 767 DUMMY_SIG_40 255;
BA_ "GenSigStartValue" SG_ 767 DUMMY_SIG_30 255;
BA_ "GenSigStartValue" SG_ 767 DUMMY_SIG_20 255;
BA_ "GenSigStartValue" SG_ 767 DUMMY_SIG_00 15;
BA_ "GenSigStartValue" SG_ 928 DUMMY_SIG_00 255;
BA_ "GenSigStartValue" SG_ 928 DUMMY_SIG_40 255;
BA_ "GenSigStartValue" SG_ 928 DUMMY_SIG_60 255;
BA_ "GenSigStartValue" SG_ 928 DUMMY_SIG_50 255;
BA_ "GenSigStartValue" SG_ 928 DUMMY_SIG_30 255;
BA_ "GenSigStartValue" SG_ 928 DUMMY_SIG_10 255;
BA_ "GenSigStartValue" SG_ 928 DUMMY_SIG_72 63;
BA_ "GenSigStartValue" SG_ 816 DUMMY_SIG_30 255;
BA_ "GenSigStartValue" SG_ 816 DUMMY_SIG_70 255;
BA_ "GenSigStartValue" SG_ 816 DUMMY_SIG_60 255;
BA_ "GenSigStartValue" SG_ 816 DUMMY_SIG_50 255;
BA_ "GenSigStartValue" SG_ 816 DUMMY_SIG_40 255;
BA_ "GenSigStartValue" SG_ 808 DUMMY_SIG_50 255;
BA_ "GenSigStartValue" SG_ 808 DUMMY_SIG_40 255;
BA_ "GenSigStartValue" SG_ 714 DUMMY_SIG_10 255;
BA_ "GenSigStartValue" SG_ 714 TEMP_EX 80;
BA_ "GenSigStartValue" SG_ 417 DUMMY_SIG_40 15;
BA_ "GenSigStartValue" SG_ 417 DUMMY_SIG_10 255;
BA_ "GenSigStartValue" SG_ 417 DUMMY_SIG_00 255;
BA_ "GenSigStartValue" SG_ 417 DUMMY_SIG_44 255;
BA_ "GenSigStartValue" SG_ 414 DUMMY_SIG_60 255;
BA_ "GenSigStartValue" SG_ 414 DUMMY_SIG_70 255;
BA_ "GenSigStartValue" SG_ 411 DUMMY_SIG_50 255;
BA_ "GenSigStartValue" SG_ 411 DUMMY_SIG_70 255;
BA_ "GenSigStartValue" SG_ 411 DUMMY_SIG_60 255;
BA_ "GenSigStartValue" SG_ 411 DUMMY_SIG_42 63;
BA_ "GenSigStartValue" SG_ 303 DUMMY_SIG_34 15;
BA_ "GenSigStartValue" SG_ 303 DUMMY_SIG_10 15;
BA_ "GenSigStartValue" SG_ 303 DUMMY_SIG_70 255;
BA_ "GenSigStartValue" SG_ 303 DUMMY_SIG_60 255;
BA_ "GenSigStartValue" SG_ 303 DUMMY_SIG_50 255;
BA_ "GenSigStartValue" SG_ 303 DUMMY_SIG_40 255;
BA_ "GenSigStartValue" SG_ 303 DUMMY_SIG_24 15;
BA_ "GenSigStartValue" SG_ 303 DUMMY_SIG_00 255;
BA_ "GenSigStartValue" SG_ 267 DUMMY_SIG_24 15;
BA_ "GenSigStartValue" SG_ 267 DUMMY_SIG_16 3;
BA_ "GenSigStartValue" SG_ 264 DUMMY_SIG_70 255;
BA_ "GenSigStartValue" SG_ 264 DUMMY_SIG_60 255;
BA_ "GenSigStartValue" SG_ 264 DUMMY_SIG_50 255;
BA_ "GenSigStartValue" SG_ 264 DUMMY_SIG_46 3;
BA_ "GenSigStartValue" SG_ 264 DUMMY_SIG_40 15;
BA_ "GenSigStartValue" SG_ 264 DUMMY_SIG_30 255;
BA_ "GenSigStartValue" SG_ 264 DUMMY_SIG_20 255;
BA_ "GenSigStartValue" SG_ 264 DUMMY_SIG_10 255;
BA_ "GenSigStartValue" SG_ 264 DUMMY_SIG_00 255;
BA_ "GenSigStartValue" SG_ 1075 DUMMY_SIG_00 255;
BA_ "GenSigStartValue" SG_ 1075 DUMMY_SIG_30 255;
BA_ "GenSigStartValue" SG_ 1075 DUMMY_SIG_20 15;
BA_ "GenSigStartValue" SG_ 1075 DUMMY_SIG_14 15;
BA_ "GenSigStartValue" SG_ 1075 DUMMY_SIG_12 3;
BA_ "GenSigStartValue" SG_ 1001 DUMMY_SIG_70 255;
BA_ "GenSigStartValue" SG_ 1001 DUMMY_SIG_60 255;
BA_ "GenSigStartValue" SG_ 1001 DUMMY_SIG_50 255;
BA_ "GenSigStartValue" SG_ 1001 DUMMY_SIG_30 15;
BA_ "GenSigStartValue" SG_ 1001 DUMMY_SIG_24 15;
BA_ "GenSigStartValue" SG_ 1001 DUMMY_SIG_10 255;
BA_ "GenSigStartValue" SG_ 1001 DUMMY_SIG_00 255;
BA_ "GenSigStartValue" SG_ 891 DUMMY_SIG_50 255;
BA_ "GenSigStartValue" SG_ 891 DUMMY_SIG_40 255;
BA_ "GenSigStartValue" SG_ 891 DUMMY_SIG_30 255;
BA_ "GenSigStartValue" SG_ 891 DUMMY_SIG_20 255;
BA_ "GenSigStartValue" SG_ 891 DUMMY_SIG_10 255;
BA_ "GenSigStartValue" SG_ 891 DUMMY_SIG_02 3;
BA_ "GenSigStartValue" SG_ 1065 DUMMY_SIG_70 255;
BA_ "GenSigStartValue" SG_ 1065 DUMMY_SIG_60 255;
BA_ "GenSigStartValue" SG_ 1065 ST_HT_ACTV_HVSTO 32768;
BA_ "GenSigStartValue" SG_ 1065 ST_HVIL_HVSTO 32768;
BA_ "GenSigStartValue" SG_ 1065 ST_CSOV_OPN_HVSTO 32768;
BA_ "GenSigStartValue" SG_ 515 ST_SWON_HVSTO 32768;
BA_ "GenSigStartValue" SG_ 515 ST_COMM_HVSTO 32768;
BA_ "GenSigStartValue" SG_ 757 I_DYN_MAX_DCHG_HVSTO_extended 32765;
BA_ "GenSigStartValue" SG_ 757 I_DYN_MAX_CHG_HVSTO_extended 32765;
BA_ "GenSigStartValue" SG_ 569 DUMMY_SIG_70 255;
BA_ "GenSigStartValue" SG_ 569 DUMMY_SIG_60 255;
BA_ "GenSigStartValue" SG_ 274 DUMMY_SIG_54 3;
BA_ "GenSigStartValue" SG_ 274 AVL_I_HVSTO_extended 32765;
BA_ "GenSigStartValue" SG_ 1073 DUMMY_SIG_40 255;
BA_ "GenSigStartValue" SG_ 1073 DUMMY_SIG_10 255;
BA_ "GenSigStartValue" SG_ 1052 DUMMY_SIG_12 63;
BA_ "GenSigStartValue" SG_ 1052 DUMMY_SIG_00 255;
BA_ "GenSigStartValue" SG_ 1037 AVLB_PWR_LT_DCHG_HVSTO_extended 65532;
BA_ "GenSigStartValue" SG_ 1037 AVLB_PWR_SRT_DCHG_HVSTO_extended 65532;
BA_ "GenSigStartValue" SG_ 1074 Dummy_SIG_70 255;
BA_ "GenSigStartValue" SG_ 1074 Dummy_SIG_50 255;
BA_ "GenSigStartValue" SG_ 1074 DUMMY_SIG_10 255;
BA_ "GenSigStartValue" SG_ 1074 DUMMY_SIG_00 255;
BA_ "GenSigStartValue" SG_ 506 AVL_TEMP_HVSTO_MAX 50;
BA_ "GenSigStartValue" SG_ 506 AVL_TEMP_HVSTO_MIN 50;
BA_ "GenSigStartValue" SG_ 506 AVL_TEMP_HTEX_HVSTO 50;
BA_ "GenSigStartValue" SG_ 506 AVL_TEMP_HVSTO 50;
BA_ "GenSigStartValue" SG_ 2632908546 TCU_Lubricant_Temperature 40;
BA_ "GenSigStartValue" SG_ 2632908546 MCU_Inverter_Temperature 40;
BA_ "GenSigStartValue" SG_ 2632908546 MCU_Stator_Temperature 40;
BA_ "GenSigStartValue" SG_ 2632908546 MCU_Rotor_Temperature 40;
BA_ "GenSigStartValue" SG_ 2565865296 Reserved_7 255;
BA_ "GenSigStartValue" SG_ 2565865296 Reserved_6 255;
BA_ "GenSigStartValue" SG_ 2565865361 Reserved_7 255;
BA_ "GenSigStartValue" SG_ 2565865361 Reserved_6 255;
BA_ "GenSigStartValue" SG_ 2566869221 D_OBC_internal_temp 40;
BA_ "GenSigStartValue" SG_ 2550595408 Reserved_7 255;
BA_ "GenSigStartValue" SG_ 2550595408 Reserved_6 255;
BA_ "GenSigStartValue" SG_ 2147549040 D_DCDC_inner_temp 40;
BA_ "GenSigStartValue" SG_ 2147549040 Reserved_0 255;
BA_ "GenSigStartValue" SG_ 2551250768 Reserved_7 255;
BA_ "GenSigStartValue" SG_ 2551250768 Reserved_6 255;
BA_ "GenSigStartValue" SG_ 2551250768 Reserved_0 255;
VAL_ 2566861442 RemainingTimeToBulkSOCFlag 1 "True" 0 "False" ;
VAL_ 2566861442 RemainTimeToBulkSOC_UnitFlag 1 "True" 0 "False" ;
VAL_ 2566861442 RemainingTimeToBulkSOC_Unit 9 "WH" 8 "W_S" 7 "W" 6 "VA" 5 "V" 4 "HA" 3 "A" 2 "S" 1 "M" 0 "H" ;
VAL_ 2566874754 LIN_EvFrequencies 255 "Not available" 2 "both 50 Hz_60 Hz" 1 "only 60 Hz" 0 "only 50 Hz" ;
VAL_ 2566865654 LimitationMode_DC1 15 "Error indicator" 14 "Not Available" 11 "External output voltage limit" 10 "Internal output voltage limit" 9 "External current limitation" 8 "High side current limitation" 7 "High side power limitation" 6 "coolant temp limitation" 5 "Power stage temp limitation" 4 "High input voltage limitation" 3 "low input voltage limitation" 2 "Event limitation" 1 "Maximum current limitatio" 0 "No Limitation" ;
VAL_ 2566865654 ActualControlMode_DC1 15 "Error Indicator" 14 "Not availble" 13 "Error state" 12 "Shutting down" 2 "Current control" 1 "Voltage control" 0 "Standby" ;
VAL_ 2566746257 Movement_status_of_ramp_5 3 "Not availble" 2 "error" 1 "Ramp being move" 0 "ramp being not move" ;
VAL_ 2566746257 Movement_status_of_ramp_4 3 "Not availble" 2 "error" 1 "Ramp being move" 0 "ramp being not move" ;
VAL_ 2566746257 Movement_status_of_ramp_3 3 "Not availble" 2 "error" 1 "Ramp being move" 0 "ramp being not move" ;
VAL_ 2566746257 Movement_status_of_ramp_2 3 "Not availble" 2 "error" 1 "Ramp being move" 0 "ramp being not move" ;
VAL_ 2566746257 Movement_status_of_ramp_1 3 "Not availble" 2 "error" 1 "Ramp being move" 0 "ramp being not move" ;
VAL_ 2566746257 Enable_status_of_ramp_1 3 "not available" 2 "error" 1 "enable" 0 "disable" ;
VAL_ 2566746257 Enable_status_of_ramp_4 3 "not available" 2 "error" 1 "enable" 0 "disable" ;
VAL_ 2566746257 Enable_status_of_ramp_3 3 "not available" 2 "error" 1 "enable" 0 "disable" ;
VAL_ 2566746257 Retract_status_of_ramp_3 3 "Not avalible" 2 "Error" 1 "Ramp Extracted" 0 "Ramp retracted" ;
VAL_ 2566746257 Retract_status_of_ramp_2 3 "Not avalible" 2 "Error" 1 "Ramp Extracted" 0 "Ramp retracted" ;
VAL_ 2566746257 Retract_status_of_ramp_1 3 "Not avalible" 2 "Error" 1 "Ramp Extracted" 0 "Ramp retracted" ;
VAL_ 2566759825 Enable_status_of_door_2 2 "Not available" 1 "Error" 0 "Enabled" ;
VAL_ 2566759825 Open_status_of_door_2 3 "Not availble" 2 "Error" 1 "Open" 0 "Closed" ;
VAL_ 2566759825 Lock_status_of_door_2 3 "Not Available" 2 "Error" 1 "lock" 0 "Unlock" ;
VAL_ 2566759825 Enable_status_of_door_1 2 "Not available" 1 "Error" 0 "Enabled" ;
VAL_ 2566759825 Open_status_of_door_1 3 "Not availble" 2 "Error" 1 "Open" 0 "Closed" ;
VAL_ 2566759825 Lock_status_of_door1 3 "Not Available" 2 "Error" 1 "lock" 0 "Unlock" ;
VAL_ 2550588916 Mode 1 "Heating mode" 0 "Battery mode" ;
VAL_ 2550588916 BMS_Control 2 "Charging complete" 1 "Bat prtect charger turn off" 0 "Charger start charging" ;
VAL_ 2349399888 MCU_rotor_over_temp 3 "Not available" 2 "Error" 1 "Active" 0 "Not active" ;
VAL_ 2349399888 MCU_regen_type_Error 3 "Not available" 2 "Error" 1 "Active" 0 "Not active" ;
VAL_ 2349399888 MCU_inverter_fault 3 "Not available" 2 "Error" 1 "Active" 0 "Not active" ;
VAL_ 2349399888 MCU_stator_over_temp 3 "Not available" 2 "Error" 1 "Active" 0 "Not active" ;
VAL_ 2349399888 MCU_inverter_over_temp 3 "Not available" 2 "Error" 1 "Active" 0 "Not active" ;
VAL_ 2349399888 MCU_over_speed_Warning 3 "Not available" 2 "Error" 1 "Active" 0 "Not active" ;
VAL_ 2349399888 MCU_over_speed_alarm 3 "Not available" 2 "Error" 1 "Active" 0 "Not active" ;
VAL_ 2349399888 MCU_undervoltage_alarm 3 "Not available" 2 "Error" 1 "Active" 0 "Not active" ;
VAL_ 2349399888 MCU_overvoltage_alarm 3 "Not available" 2 "Error" 1 "Active" 0 "Not active" ;
VAL_ 2349399888 MCU_limp_home_mode 3 "Not available" 2 "Error" 1 "Active" 0 "Not active" ;
VAL_ 2349399888 Transmission_Temp_Read_Error 3 "Not available" 2 "Error" 1 "Active" 0 "Not active" ;
VAL_ 2349399888 Transmission_Temperature_Limit 3 "Not available" 2 "Error" 1 "Active" 0 "Not active" ;
VAL_ 2349399888 Transmission_Temperature_Error 3 "Not available" 2 "Error" 1 "Active" 0 "Not active" ;
VAL_ 2349399888 Transmission_Temperature_Warning 3 "Not available" 2 "Error" 1 "Active" 0 "Not active" ;
VAL_ 2349399888 TCU_cmd_MSG_2_watchdog_timeout 3 "Not available" 2 "Error" 1 "Active" 0 "Not active" ;
VAL_ 2349399888 TCU_cmd_MSG_1_watchdog_timeout 3 "Not available" 2 "Error" 1 "Active" 0 "Not active" ;
VAL_ 2349399888 CAT3_RQ_SER_HVSTO 3 "Signal Invalid" 2 "Active" 1 "Not Active" 0 "No statement possible" ;
VAL_ 2349399888 CAT7_RQ_OPN_DCSW_HVSTO_ILY 3 "Signal Invalid" 2 "Active" 1 "Not Active" 0 "No statement possible" ;
VAL_ 2349399888 CAT6_RQ_OPN_DCSW_HVSTO_FAST 3 "Signal Invalid" 2 "Active" 1 "Not Active" 0 "No statement possible" ;
VAL_ 2349399888 CAT5_RQ_OPN_CHG_HVSTO 3 "Signal Invalid" 2 "Active" 1 "Not Active" 0 "No statement possible" ;
VAL_ 2349399888 CAT4_ERR_EMMOD_HVSTO 3 "Signal Invalid" 2 "Active" 1 "Not Active" 0 "No statement possible" ;
VAL_ 2349399888 CAT1_ST_PRCHRG_LOKD_HVSTO 3 "Signal Invalid" 2 "Active" 1 "Not Active" 0 "No statement possible" ;
VAL_ 2349334352 Regen_OFF 3 "Not available" 2 "Error" 1 "Active" 0 "Not active" ;
VAL_ 2349334352 TCU_Selected_Gear 3 "Shift in Progress" 2 "High" 1 "Low" 0 "Neutral" ;
VAL_ 2349334352 TCU_Current_transmission_mode 3 "Forward Low" 2 "Forward Automatic" 1 "Reverse" 0 "Neutral" ;
VAL_ 2365538503 Control_Mode_DCC2_1 3 "take no action" 2 "reserved" 1 "Current control" 0 "Voltage control " ;
VAL_ 2365538503 Command_Enable_DCC2_2 3 "Take no action" 2 "Reserved" 1 "Enable" 0 "Standby" ;
VAL_ 2365538503 Command_Enable_DCC2_1 3 "Take no action" 2 "Reserved" 1 "Enable" 0 "Standby" ;
VAL_ 2566863234 V2G_EVMaxvoltagelimit_Unitflag 1 "True" 0 "False" ;
VAL_ 2566863234 V2G_EVMaximumvoltagelimit_Flag 1 "True" 0 "False" ;
VAL_ 2566863234 V2G_EVMaximumvoltagelimit_Unit 9 "WH" 8 "W_S" 7 "W" 6 "VA" 5 "V" 4 "HA" 3 "A" 2 "S" 1 "M" 0 "H" ;
VAL_ 2566862978 V2G_EVMaximumpowerlimit_Unitflag 1 "True" 0 "False" ;
VAL_ 2566862978 V2G_EVMaximumpowerlimit_Flag 1 "True" 0 "False" ;
VAL_ 2566862978 V2G_EVMaximumpowerlimit_Unit 9 "WH" 8 "W_S" 7 "W" 6 "VA" 5 "V" 4 "HA" 3 "A" 2 "S" 1 "M" 0 "H" ;
VAL_ 2564816770 Hold_signal 15 "Not available" 1 "Devices whose broadcast state" 0 "All Devices" ;
VAL_ 2564816770 Suspend_signal 15 "not available" 14 "ResumingNormalpattern" 3 "Temporarysuspensionofsomemsg" 2 "Temporarysuspensionofallmsg" 1 "Indefinitesuspensionofsomemsg" 0 "Indefinitesuspensionofallmsg" ;
VAL_ 2564816770 J1939_Network3 3 "dont care" 2 "reserved" 1 "start broadcast" 0 "Stop broadcast" ;
VAL_ 2564816770 Proprietry_Network1 3 "dont care" 2 "reserved" 1 "start broadcast" 0 "Stop broadcast" ;
VAL_ 2564816770 Proprietry_Network2 3 "dont care" 2 "reserved" 1 "start broadcast" 0 "Stop broadcast" ;
VAL_ 2564816770 J1939_Network4 3 "dont care" 2 "reserved" 1 "start broadcast" 0 "Stop broadcast" ;
VAL_ 2564816770 J1939_Network2 3 "dont care" 2 "reserved" 1 "start broadcast" 0 "Stop broadcast" ;
VAL_ 2564816770 ISO9141 3 "dont care" 2 "reserved" 1 "start broadcast" 0 "Stop broadcast" ;
VAL_ 2564816770 SAE_J1580 3 "dont care" 2 "reserved" 1 "start broadcast" 0 "Stop broadcast" ;
VAL_ 2564816770 Manufacturer_specific_port 3 "dont care" 2 "reserved" 1 "start broadcast" 0 "Stop broadcast" ;
VAL_ 2564816770 Current_data_link 3 "dont care" 2 "reserved" 1 "start broadcast" 0 "Stop broadcast" ;
VAL_ 2564816770 SAE_J1587 3 "dont care" 2 "reserved" 1 "start broadcast" 0 "Stop broadcast" ;
VAL_ 2564816770 SAE_J1922 3 "dont care" 2 "reserved" 1 "start broadcast" 0 "Stop broadcast" ;
VAL_ 2564816770 J1939_Network_1 3 "dont care" 2 "reserved" 1 "start broadcast" 0 "Stop broadcast" ;
VAL_ 2566860930 V2G_StateM_EnergyTransfer_mode 15 "undefined" 5 "DC_unique" 4 "DC_combo_core" 3 "DC_extended" 2 "DC_core" 1 "AC_three_phase_core" 0 "Ac_single_phse_core" ;
VAL_ 2566860930 V2G_EVPower_deliveryparamtrflag 1 "True" 0 "False" ;
VAL_ 2566860930 V2G_EV_RESSconditing_flag 1 "True" 0 "False" ;
VAL_ 2566860930 V2G_EV_RESSconditing 1 "True" 0 "False" ;
VAL_ 2566860930 V2G_EV_Ready 1 "True" 0 "False" ;
VAL_ 2566860930 V2G_EVCabin_conditioning_flag 1 "True" 0 "False" ;
VAL_ 2566860930 V2G_EVCabin_conditioning 1 "True" 0 "False" ;
VAL_ 2566860930 V2G_charging_complete 1 "True" 0 "False" ;
VAL_ 2566860930 V2G_FullSOC_flag 1 "True" 0 "False" ;
VAL_ 2566860930 V2G_BulkSOC_flag 1 "True" 0 "False" ;
VAL_ 2566860930 V2G_Bulkcharging_Complete_flag 1 "True" 0 "False" ;
VAL_ 2566860930 V2G_Bulkcharging_Complete 1 "True" 0 "False" ;
VAL_ 2566860930 V2G_EV_Error_Code 11 "No data" 10 "CHARGING_SYSTEM_INCOMPATIBILITY" 9 "RESERVED_C" 8 "RESERVED_B" 7 "RESERVED_A" 6 "CHARGING_VOLTAGE_OUT_OF_RANGE" 5 "FAILCHARGCURRENTDIFFERENTIAL" 4 "FAILED_EVRESSMALFUNCTION" 3 "FAILChargeCONNECT_LOCK_FAULT" 2 "FAILED_EVSHIFT_POSITION" 1 "FAILED_RESSTEMPERATURE_INHIBIT" 0 "NO_ERROR" ;
VAL_ 2566861186 VCVCCU_V2G_RemainTmeToFulSOC_Flg 1 "True" 0 "False" ;
VAL_ 2566861186 VCVCCU_V2G_RemainTimeToFulSOCuni 9 "WH" 8 "W_S" 7 "W" 6 "VA" 5 "V" 4 "HA" 3 "A" 2 "S" 1 "M" 0 "H" ;
VAL_ 2566861186 V2G_RemnTimeToFulSOC_Unitflag 1 "True" 0 "False" ;
VAL_ 2566861698 V2G_EVTargetVoltage_Unit 9 "WH" 8 "W_S" 7 "W" 6 "VA" 5 "V" 4 "HA" 3 "A" 2 "S" 1 "M" 0 "H" ;
VAL_ 2566861698 V2G_EVTargetVoltage_Unit_Flag 1 "True" 0 "False" ;
VAL_ 2566861954 V2G_EVTargetCurrent_Unit 9 "WH" 8 "W_S" 7 "W" 6 "VA" 5 "V" 4 "HA" 3 "A" 2 "S" 1 "M" 0 "H" ;
VAL_ 2566861954 V2G_EVTargetCurrent_Unit_Flag 1 "True" 0 "False" ;
VAL_ 2566862722 V2G_EVMaxcurrentlimit_Unitflag 1 "True" 0 "False" ;
VAL_ 2566862722 V2G_EVMaximumcurrentlimit_Flag 1 "True" 0 "False" ;
VAL_ 2566862722 V2G_EVMaximumcurrentlimit_Unit 9 "WH" 8 "W_S" 7 "W" 6 "VA" 5 "V" 4 "HA" 3 "A" 2 "S" 1 "M" 0 "H" ;
VAL_ 2566862466 V2G_EVEnergyRequest_Unitflag 1 "True" 0 "False" ;
VAL_ 2566862466 V2G_EVEnergyRequest_flag 1 "True" 0 "False" ;
VAL_ 2566862466 V2G_EVEnergyRequest_Unit 9 "WH" 8 "W_S" 7 "W" 6 "VA" 5 "V" 4 "HA" 3 "A" 2 "S" 1 "M" 0 "H" ;
VAL_ 2566862210 V2G_EVEnergyCapacity_Unitflag 1 "True" 0 "False" ;
VAL_ 2566862210 V2G_EVEnergyCapacity_flag 1 "True" 0 "False" ;
VAL_ 2566862210 V2G_EVEnergyCapacity_Unit 9 "WH" 8 "W_S" 7 "W" 6 "VA" 5 "V" 4 "HA" 3 "A" 2 "S" 1 "M" 0 "H" ;
VAL_ 2566865026 V2G_Departuretime_Value 1 "True" 0 "False" ;
VAL_ 2566856834 Inletmotor_Request 3 "SNA" 2 "Reserved" 1 "Unlock" 0 "Lock" ;
VAL_ 2566856834 Chargeunit_Request 3 "SNA" 2 "Enable ventilation" 1 "Enable" 0 "Disable" ;
VAL_ 2566856834 Control_pilot_chargemode_request 7 "SNA" 6 "Error" 5 "Reserved 3" 4 "Reserved 2" 3 "Reserved 1" 2 "Mode D" 1 "Mode C" 0 "Mode B" ;
VAL_ 2566856834 RTC_timervalue 255 "SNA" ;
VAL_ 2566856834 Highsideoutput4_Request 3 "SNA" 2 "Reserved" 1 "Enable" 0 "Disable" ;
VAL_ 2566856834 PlugLock_motor_request 7 "SNA" 6 "Reserved3" 5 "Reserved2" 4 "Reserved1" 3 "Measurement" 2 "Direction B" 1 "Directon A" 0 "Stop" ;
VAL_ 2566856834 RTCtimer_Request 3 "SNA" 2 "reserved" 1 "requested" 0 "Not requested" ;
VAL_ 2566856834 Highsideoutput3_Request 3 "SNA" 2 "Reserved" 1 "Enable" 0 "Disable" ;
VAL_ 2566856834 Highsideoutput2_Request 3 "SNA" 2 "Reserved" 1 "Enable" 0 "Disable" ;
VAL_ 2566856834 Highsideoutput1_Request 3 "SNA" 2 "Reserved" 1 "Enable" 0 "Disable" ;
VAL_ 2566856834 Highsideoutput0_Request 3 "SNA" 2 "Reserved" 1 "Enable" 0 "Disable" ;
VAL_ 2566856834 LED2_Request 255 "SNA" ;
VAL_ 2566856834 LED1_Request 255 "SNA" ;
VAL_ 2566856834 LED0_Request 255 "SNA" ;
VAL_ 2566855552 VCVCCU_V2ICP_AmbientTemperature 127 "SNA" ;
VAL_ 2566855552 VCVCCU_V2ICP_PrecnditinigDesire 255 "SNA" 1 "Yes" 0 "No" ;
VAL_ 2566855552 VCVCCU_V2ICP_PrecndtnDesireHVAC 3 "SNA" 2 "no_warm water , cool & venti" 1 "hot water and heating" 0 "only warm water , ventilation" ;
VAL_ 2566855552 VCVCCU_V2ICP_SchdulDepartureTime 0 "SNA" ;
VAL_ 2566872192 V2G_EthTrcv_TrcvlinkState 1 "True" 0 "False" ;
VAL_ 2566872192 V2G_Core_TrcvlinkState 1 "True" 0 "False" ;
VAL_ 2566872192 V2G_Core_IP_assigned 1 "True" 0 "False" ;
VAL_ 2566872192 V2G_Core_cyclic_Msg_Trg 1 "True" 0 "False" ;
VAL_ 2566872192 V2G_Core_cyclic_Msg_Revd 1 "True" 0 "False" ;
VAL_ 2566872192 V2G_Core_StackError 16 "StackError_PBufToSmall" 15 "StackError_InvalidKeyPair" 14 "StackError_NvM" 13 "StackError_NegativeResponseCode" 12 "StackError_InvalidRxParameter" 11 "StackError_InvalidRxMessage" 10 "StackError_Crypto" 9 "StackError_XmlSecurity" 8 "StackError_Exi" 7 "StackError_IpBase" 6 "StackError_Timeout" 5 "Timeout_RequestNotAcknowledged" 4 "Timeout_RequestAcknowledged" 3 "StackError_InvalidTxParameter" 2 "StackError_TransportLayer" 1 "StackError_SLAC" 0 "StackError_NoError" ;
VAL_ 2566872192 V2G_Core_SDPSecurityTx 16 "SDPSecurity_None" 0 "SDPSecurity_Tls" ;
VAL_ 2566872192 V2G_Core_SAPSchemID 4 "SAPSchemaIDs_None" 3 "NumOfSupportedSchemas" 2 "SAPSchemaIDs_DIN" 1 "SAPSchemaIDs_ISO_Ed2_CD" 0 "SAPSchemaIDs_ISO" ;
VAL_ 2566872192 V2G_Core_SAPResponse_code 2 "FAILED_NO_NEGOTIATION" 1 "OKNEGOTIAMINOR_DEVIATION" 0 "OK_SUCCESSFUL_NEGOTIATION" ;
VAL_ 2566872192 V2G_Core_MsgStatus 50 "StopCommunicationSession_Failed" 49 "StopCommunicationSession_OK" 48 "MsgStatus_SessionStop_Failed" 47 "MsgStatus_SessionStop_OK" 46 "WeldingDetection_Failed" 45 "MsgStatus_WeldingDetection_OK" 44 "MsgStatus_CurrentDemand_Failed" 43 "MsgStatus_CurrentDemand_OK" 42 "MsgStatus_PreCharge_Failed" 41 "MsgStatus_PreCharge_OK" 40 "MsgStatus_CableCheck_Failed" 39 "MsgStatus_CableCheck_OK" 38 "MsgStatus_ChargingStatus_Failed" 37 "MsgStatus_ChargingStatus_OK" 36 "MsgStatus_MeteringReceipt_Failed" 35 "MsgStatus_MeteringReceipt_OK" 34 "MsgStatus_PowerDelivery_Failed" 33 "MsgStatus_PowerDelivery_OK" 32 "ChargeParameterDiscovery_Failed" 31 "ChargeParameterDiscovery_OK" 30 "MsgStatus_Authorization_Failed" 29 "MsgStatus_Authorization_OK" 28 "MsgStatus_PaymentDetails_Failed" 27 "PaymentDetails_OK" 26 "CertificateUpdate_Failed" 25 "CertificateUpdate_OK" 24 "CertificateInstallation_Failed" 23 "CertificateInstallation_OK" 22 "MsgStatus_ReadProvCert_Failed" 21 "MsgStatus_ReadProvCert_OK" 20 "WrapperReadRootCerts_Failed" 19 "MsgStatus_ReadRootCerts_OK" 18 "PaymentServiceSelection_Failed" 17 "PaymentServiceSelection_OK" 16 "MsgStatus_ServiceDetail_Failed" 15 "MsgStatus_ServiceDetail_OK" 14 "ReadContrCertChain_Failed" 13 "ReadContrCertChain_OK" 12 "ServiceDiscovery_Failed" 11 "MsgStatus_ServiceDiscovery_OK" 10 "MsgStatus_SessionSetup_Failed" 9 "MsgStatus_SessionSetup_OK" 8 "SupportedAppProtocol_Failed" 7 "SupportedAppProtocol_OK" 6 "MsgStatus_TransportLayer_Failed" 5 "MsgStatus_TransportLayer_OK" 4 "SECCDiscoveryProtocol_Failed" 3 "SECCDiscoveryProtocol_OK" 2 "MsgStatus_SLAC_Failed" 1 "MsgStatus_SLAC_OK" 0 "MsgStatus_None" ;
VAL_ 2566872192 V2G_Core_MsgState 5 "msgstate_timeout" 4 "msgstate_response_received" 3 "msgstate_transmission_confirmed" 2 "msgstate_request_sent" 1 "msgstate_streaming_request" 0 "Msg_state_waitfor next_request" ;
VAL_ 2566854272 VCVCCU_RTC_Wakeup 3 "sna" 2 "error" 1 "wakeup detected" 0 "wakeup not detected" ;
VAL_ 2566854272 VCVCCU_RTC_TimerStatus 3 "SNA" 2 "Elapsed" 1 "Running" 0 "Stopped" ;
VAL_ 2566853248 VCVCCU_PTC2_SelfDiagnosticStatus 7 "SNA" 6 "reserved3" 5 "reserved2" 4 "reserved1" 3 "Open Load" 2 "Short to Batt" 1 "Short to GND" 0 "Ok" ;
VAL_ 2566853248 VCVCCU_PTC2_Temperature 65535 "SNA" 65534 "Error" ;
VAL_ 2566853248 VCVCCU_PTC2_Resistance 65535 "SNA" 65534 "Error" ;
VAL_ 2566853248 VCVCCU_PTC2_Raw 65535 "SNA" 65534 "Error" ;
VAL_ 2566852992 VCVCCU_PTC1_SelfDiagnosticStatus 7 "SNA" 6 "reserved3" 5 "reserved2" 4 "reserved1" 3 "Open Load" 2 "Short to Batt" 1 "Short to GND" 0 "Ok" ;
VAL_ 2566852992 VCVCCU_PTC1_Temperature 65535 "SNA" 65534 "Error" ;
VAL_ 2566852992 VCVCCU_PTC1_Resistance 65535 "SNA" 65534 "Error" ;
VAL_ 2566852992 VCVCCU_PTC1_Raw 65535 "SNA" 65534 "Error" ;
VAL_ 2566852736 VCVCCU_PTC0_SelfDiagnosticStatus 7 "SNA" 6 "Error" 5 "Reserved 1" 4 "Out of range" 3 "Open Load" 2 "Short to Batt" 1 "Short to GND" 0 "Ok" ;
VAL_ 2566852736 VCVCCU_PTC0_Temperature 65535 "SNA" 65534 "Error" ;
VAL_ 2566852736 VCVCCU_PTC0_Resistance 65535 "SNA" 65534 "Error" ;
VAL_ 2566852736 VCVCCU_PTC0_Raw 65535 "SNA" 65534 "Error" ;
VAL_ 2566854016 VCVCCU_HighSideOut4_Input_Status 3 "sna" 2 "Error" 1 "Pressed" 0 "Not Pressed" ;
VAL_ 2566854016 VCVCCU_HighSideOut3_Input_Wakeup 3 "sna" 2 "error" 1 "wakeup detected" 0 "wakeup not detected" ;
VAL_ 2566854016 VCVCCU_HghSdeOut4_Ip_DebonceStat 3 "sna" 2 "Error" 1 "Pressed" 0 "Not Pressed" ;
VAL_ 2566854016 VCVCCU_HighSideOut3_Input_Status 3 "sna" 2 "Error" 1 "Pressed" 0 "Not Pressed" ;
VAL_ 2566854016 VCVCCU_HghSdeOut3_Ip_DebuncStats 3 "sna" 2 "Error" 1 "Pressed" 0 "Not Pressed" ;
VAL_ 2566854016 VCVCCU_HighSideOut2_Input_Status 3 "sna" 2 "Error" 1 "Pressed" 0 "Not Pressed" ;
VAL_ 2566854016 VCVCCU_HghSdeOut2_Ip_DebuncStats 3 "sna" 2 "Error" 1 "Pressed" 0 "Not Pressed" ;
VAL_ 2566854016 VCVCCU_HighSideOut1_Input_Status 3 "sna" 2 "Error" 1 "Pressed" 0 "Not Pressed" ;
VAL_ 2566854016 VCVCCU_HghsdeOut1_Ip_DebunceStat 3 "sna" 2 "Error" 1 "Pressed" 0 "Not Pressed" ;
VAL_ 2566854016 VCVCCU_HighSideOut0_Ip_Stats 3 "sna" 2 "Error" 1 "Pressed" 0 "Not Pressed" ;
VAL_ 2566854016 VCVCCU_HghSdeOut0_Ip_DeboncStats 3 "sna" 2 "Error" 1 "Pressed" 0 "Not Pressed" ;
VAL_ 2566854016 VCVCCU_LED2_SelfDiagnosticStatus 7 "SNA" 6 "Reseved3" 5 "Reserved2" 4 "Reserved1" 3 "Open Load" 2 "Short to Batt" 1 "Short to GND" 0 "Ok" ;
VAL_ 2566854016 VCVCCU_LED1_SelfDiagnosticStatus 7 "SNA" 6 "Reseved3" 5 "Reserved2" 4 "Reserved1" 3 "Open Load" 2 "Short to Batt" 1 "Short to GND" 0 "Ok" ;
VAL_ 2566854016 VCVCCU_LED0_SelfDiagStatus 7 "SNA" 6 "Reseved3" 5 "Reserved2" 4 "Reserved1" 3 "Open Load" 2 "Short to Batt" 1 "Short to GND" 0 "Ok" ;
VAL_ 2566854016 VCVCCU_HghSdeOut4_SelfDiagStatus 7 "SNA" 6 "Error" 5 "Short Btw pins" 4 "Inverse Currrent" 3 "Open Load" 2 "Short to Batt" 1 "Short to GND" 0 "Ok" ;
VAL_ 2566854016 VCVCCU_HghSdeOut3_SelfDiagStatus 7 "SNA" 6 "Error" 5 "Short Btw pins" 4 "Inverse Currrent" 3 "Open Load" 2 "Short to Batt" 1 "Short to GND" 0 "Ok" ;
VAL_ 2566854016 VCVCCU_HghSdeOut2_SelfDiagStatus 7 "SNA" 6 "Error" 5 "Short Btw pins" 4 "Inverse Currrent" 3 "Open Load" 2 "Short to Batt" 1 "Short to GND" 0 "Ok" ;
VAL_ 2566854016 VCVCCU_HghSdeOut1_SelfDiagStatus 7 "SNA" 6 "Error" 5 "Short Btw pins" 4 "Inverse Currrent" 3 "Open Load" 2 "Short to Batt" 1 "Short to GND" 0 "Ok" ;
VAL_ 2566854016 VCVCCU_HghSieOut0_SelfDiagStatus 7 "SNA" 6 "Error" 5 "Short Btw pins" 4 "Inverse Currrent" 3 "Open Load" 2 "Short to Batt" 1 "Short to GND" 0 "Ok" ;
VAL_ 2566874240 LIN_SeFrequency 255 "Not Available" 1 "60 Hz" 0 "50 Hz" ;
VAL_ 2566854784 SS_Voltage 65535 "SNA" 65534 "Error" ;
VAL_ 2566854784 Internal_VCC_KL30_Voltage 65535 "SNA" 65534 "Error" ;
VAL_ 2566854784 Internal_VCC_KL15_Voltage 65535 "SNA" 65534 "Error" ;
VAL_ 2566854784 Internal_VCC_12v_Voltage 65535 "SNA" 65534 "Error" ;
VAL_ 2566855040 SS_Raw 65535 "SNA" 65534 "Error" ;
VAL_ 2566855040 Internal_VCC_KL30_Raw 65535 "SNA" 65534 "Error" ;
VAL_ 2566855040 Internal_VCC_KL15_Raw 65535 "SNA" 65534 "Error" ;
VAL_ 2566855040 Internal_VCC_12v_Raw 65535 "SNA" 65534 "Error" ;
VAL_ 2566855296 ProtectiveEarth_Offset 65535 "SNA" 65534 "Error" ;
VAL_ 2566855296 VCVCCU_ControlPilot_MinVoltage 65535 "SNA" 65534 "Error" ;
VAL_ 2566855296 Plug_present_voltage 65535 "SNA" 65534 "Error" ;
VAL_ 2566853504 S3Switch_debounce_state 3 "sna" 2 "Error" 1 "Pressed" 0 "Not Pressed" ;
VAL_ 2566853504 S3Switch_status 3 "sna" 2 "Error" 1 "Pressed" 0 "Not Pressed" ;
VAL_ 2566853504 Inlet_connection_status 3 "Description for the value '0x3'" 2 "error" 1 "connected" 0 "not connected" ;
VAL_ 2566853504 Digital_input_debounce_state 3 "sna" 2 "Error" 1 "Pressed" 0 "Not Pressed" ;
VAL_ 2566853504 Inlet_max_current 255 "SNA" 254 "Error" ;
VAL_ 2566853504 Inlet_motor_status 7 "SNA" 6 "Error" 5 "Reserved3" 4 "Reserved2" 3 "Reserved1" 2 "Moving" 1 "Locked" 0 "Unlocked" ;
VAL_ 2566853504 Digital_input_wakeup 3 "sna" 2 "error" 1 "wakeup detected" 0 "wakeup not detected" ;
VAL_ 2566853504 Digital_input_status 3 "sna" 2 "Error" 1 "Pressed" 0 "Not Pressed" ;
VAL_ 2566853504 Inlet_HW_variant 3 "SNA" 2 "reserved" 1 "Combo1 inlet" 0 "Combo2 " ;
VAL_ 2566853504 Pluglock_output1_selfdiag_status 7 "SNA" 6 "Error" 5 "Short Btw pins" 4 "Supply Voltage Failure'" 3 "Open Load" 2 "Short to Batt" 1 "Short to GND" 0 "Ok" ;
VAL_ 2566853504 Pluglock_output0_selfdiag_status 7 "SNA" 6 "Reseved3" 5 "Reserved2" 4 "Reserved1" 3 "Open Load" 2 "Short to Batt" 1 "Short to GND" 0 "Ok" ;
VAL_ 2566853504 Plug_lock_motorstatus 7 "SNA" 6 "Error" 5 "Reserved2" 4 "Resserved1" 3 "Measurement" 2 "Direction B" 1 "Direction A" 0 "Idle" ;
VAL_ 2566853504 POSF_present_selfdiag_status 7 "SNA" 6 "Reseved3" 5 "Reserved2" 4 "Reserved1" 3 "Open Load" 2 "Short to Batt" 1 "Short to GND" 0 "Ok" ;
VAL_ 2566853504 Plug_present_wakeup 3 "sna" 2 "error" 1 "wakeup detected" 0 "wakeup not detected" ;
VAL_ 2566853504 Plug_present_status 3 "SNA" 2 "error" 1 "connected" 0 "not connected" ;
VAL_ 2566853504 Plug_present_resistance 7 "SNA" 6 "Error" 5 "S3_480_ohm" 4 "S3_150_ohm" 3 "1500 Ohm" 2 "680 ohm" 1 "220 Ohm" 0 "100 Ohm" ;
VAL_ 2566853504 Plug_present_selfdiag_status 7 "SNA" 6 "Error" 5 "Short Btw pins" 4 "Supply Voltage Failure'" 3 "Open Load" 2 "Short to Batt" 1 "Short to GND" 0 "Ok" ;
VAL_ 2566853504 POS_Feedback_voltage 65535 "SNA" 65534 "Error" ;
VAL_ 2633990272 Awake_ChargeLin_Actv_VCVCCU 1 "Charg_Lin_active" 0 "Charg_Lin_not Active" ;
VAL_ 2633990272 Awake_Clamp15_Actv_VCVCCU 1 "Clamp_15_active" 0 "Clamp15_not Active" ;
VAL_ 2633990272 Awake_ChargeCom_Actv_VCVCCU 1 "Charg_Comm_Active" 0 "Charg_Comm_not_Active" ;
VAL_ 2633990272 Awakediag_Actv_VCVCCU 1 "Diag__active" 0 "Diag_no active" ;
VAL_ 2633990272 WakeupRsn_VCVCCU 255 "Snaa" 5 "Clamp15" 4 "Switch" 3 "RTC" 2 "Plug Present" 1 "Control_pilot" 0 "Network" ;
VAL_ 2566857090 VCVCCU_Vehicle_StopCharge 3 "sna" 2 "Error" 1 "Pressed" 0 "Not Pressed" ;
VAL_ 2566857090 VCVCCU_Vehicle_Renegotiate 3 "SNA" 2 "Error" 1 "Requested" 0 "Not_requested" ;
VAL_ 2566857090 Vehicle_PwmChargeModeRequest 3 "SNA" 2 "Error" 1 "PWM_charge_mode_request_D" 0 "PWM_charge_mode_request_C" ;
VAL_ 2566857090 VCVCCU_Vehicle_ChargeSelection 3 "SNA" 2 "error" 1 "secondary node" 0 "Primary node" ;
VAL_ 2566857090 Vehicle_contactor_status 3 "SNA" 2 "Stuck" 1 "Close" 0 "Open" ;
VAL_ 2566857090 Vehicle_charge_permission 3 "Stop" 2 "Emergency stop" 1 "allowed" 0 "Not allowed" ;
VAL_ 2566857090 Vehicle_plugunlock_permission 3 "SNA" 2 "Reserved" 1 "Allowed" 0 "Not_allowed" ;
VAL_ 2566857090 Vehicle_pluglock_permission 3 "SNA" 2 "Reserved" 1 "Allowed" 0 "Not_allowed" ;
VAL_ 2566857090 Vehicle_isolation_mesurmntStatus 3 "SNA" 2 "Error" 1 "Active" 0 "Not active" ;
VAL_ 2566857090 Vehicle_link_voltage 65535 "SNA" 65534 "Error" ;
VAL_ 2566857090 Vehicle_contactor_voltage 65535 "SNA" 65534 "Error" ;
VAL_ 2566872448 V2G_Appl_SccFuncModeReq 2 "Reset" 1 "Charging mode" 0 "none" ;
VAL_ 2566872448 V2G_Appl_SccChargeModeReq 6 "Stop Charging" 5 "Renegotation" 4 "Start welding detection" 3 "Start power delivery" 2 "Precharge completed" 1 "Negotating Charging Parameters" 0 "None" ;
VAL_ 2566872448 V2G_StateM_InternetAvailable 1 "True" 0 "False" ;
VAL_ 2566872448 V2G_StateM_StateMachineStatus 32 "PowerDemand" 31 "InitialAlignmentCheck" 30 "Pairing" 29 "FinePositioning" 28 "FinePositioningSetup" 27 "Error_Stopped" 26 "Error_WaitForRetry" 25 "Finished" 24 "StopCommunicationSession" 23 "SessionStop" 22 "WeldingDetection" 21 "MeteringReceipt" 20 "CurrentDemand" 19 "ChargingStatus" 18 "PowerDelivery" 17 "PreCharge" 16 "CableCheck" 15 "ChargeParameterDiscovery" 14 "Authorization" 13 "PaymentDetails" 12 "CertificateUpdate" 11 "CertificateInstallation" 10 "PaymentServiceSelection" 9 "ServiceDetails" 8 "ServiceDiscovery" 7 "SessionSetup" 6 "SupportedAppProtocol" 5 "TLConnection" 4 "SECCDiscoveryProtocol" 3 "WaitForIP" 2 "SLAC" 1 "Initialized" 0 "None" ;
VAL_ 2566872448 V2G_StateM_StateMachneMsgState 3 "SMMS_WaitingForApplication" 2 "SMMS_ProcessingResponse" 1 "SMMS_WaitingForResponse" 0 "SMMS_PreparingRequest" ;
VAL_ 2566872448 V2G_StateM_StateMachineError 20 "SMER_InvalidControlPilotState" 19 "PaymtServiceSelect_ServMismatch" 18 "InitialAlignmentCheckOngoinTimer" 17 "SMER_Timer_PairingOngoingTimer" 16 "Timer_FinePositionOngoingTimer" 15 "SMER_StackError" 14 "NoContractInstallatiServiceAvbl" 13 "NoContractCertificateServiceAvlb" 12 "NoSharedPaymentOption" 11 "InvalidEnergyTransferMode" 10 "Discovery_NoSharedSecurityOption" 9 "InitializatContrctSelectiFailed" 8 "SMER_Timer_PreChargeOngoingTimer" 7 "Timer_CableCheckOngoingTimer" 6 "ChargeParmtrDiscveryOngoingTimer" 5 "Timer_AuthorizationOngoingTimer" 4 "SMETimer_ReadyToChargeTimer" 3 "Timer_CommunicationSetupTimer" 2 "SMER_Timer_SequencePerformTimer" 1 "SMER_Timer_IPAddressWaitTimer" 0 "SMER_NoError" ;
VAL_ 2566872448 V2G_StateM_Enrgy_TrnsfrmodeFlags 32 "Energy_transfermode_DC_Unique" 16 "Energy_transfermode_combo_core" 8 "Energy_transfermode_DC_extend" 4 "Energy_transfermode_DCcore" 2 "Energy_transfermode_AC_3P" 1 "Energy_transfermode_AC_1P" 0 "Energy_transfermode_none" ;
VAL_ 2566869120 V2G_EVSEResponseCode 26 "FAILED_CERTIFICATE_REVOKED" 25 "FAILED_CERTIFICATE_NOT_ALLOW_e" 24 "FAILED_CONTACTOR_ERROR" 22 "FAILED_WRNG_ENRGY_TRNSFER_TYPE" 21 "FAILED_NO_CHARGE_SERVICE_SELECt" 20 "FAILED_MTRING_SIGNTURE_NOT_VALID" 19 "FAILED_CHARGING_PROFILE_INVALID" 18 "FAILED_TARIFF_SELECTION_INVALID" 17 "FAILED_POWER_DELIVERY_NOT_APPLy" 16 "FAILED_WRONG_CHARGE_PARAMETER" 15 "FAILED_CONTRACT_CANCELED" 14 "FAILED_CHALLENGE_INVALID" 13 "FAILED_CERT_CHAIN_ERROR" 12 "FAILED_NO_CERTIFICATE_AVAILABLE" 11 "FAILED_SIGNATURE_ERROR" 10 "FAILED_CERTIFICATE_EXPIRED" 9 "FAILED_PAYMENT_SELECTION_INVALID" 8 "FAILED_SERVICE_SELECTION_INVALID" 7 "FAILED_UNKNOWN_SESSION" 6 "FAILED_SERVICE_IDINVALID" 5 "FAILED_SEQUENCE_ERROR" 4 "FAILED" 3 "OK_CERTIFICATE_EXPIRES_SOON" 2 "OK_OLD_SESSION_JOINED" 1 "OK_NEW_SESSION_ESTABLISHED" 0 "OK" ;
VAL_ 2566869120 V2G_EVSEDateTimeNowFlag 1 "True" 0 "False" ;
VAL_ 2566869120 V2G_EVSEPowerLimitAchieved 1 "True" 0 "False" ;
VAL_ 2566869120 V2G_EVSEVoltageLimitAchieved 1 "True" 0 "False" ;
VAL_ 2566869120 V2G_EVSEStatusCode 11 "reserved c" 10 "reserved B" 9 "Reserved A" 8 "Reserved 9" 7 "Reserved 8" 6 "EVSE Malfunction" 5 "EVSE Emergency Shutdwon" 4 "EVSE Isolation Monitoring Active" 3 "EVSE Utility Interrupt Event" 2 "EVSE Shutdown" 1 "EVSE Ready" 0 "EVSE_Not_Ready" ;
VAL_ 2566869120 V2G_EVSEProcessing 1 "ongoing" 0 "Finished" ;
VAL_ 2566869120 V2G_EVSENotification 2 "Re_Negotation" 1 "Stop Charging" 0 "None" ;
VAL_ 2566869120 V2G_EVSEIsolationStatusFlag 1 "True" 0 "False" ;
VAL_ 2566869120 V2G_EVSEIsolationStatus 4 "No_Imd" 3 "Fault" 2 "Warning" 1 "Valid" 0 "Invalid" ;
VAL_ 2566869120 V2G_EVSECurrentLimitAchieved 1 "True" 0 "False" ;
VAL_ 2566871680 V2G_EVSEPresentVoltage_UnitFlag 1 "True" 0 "False" ;
VAL_ 2566871680 V2G_EVSEPresentVoltage_Unit 9 "WH" 8 "W_S" 7 "W" 6 "VA" 5 "V" 4 "HA" 3 "A" 2 "S" 1 "M" 0 "H" ;
VAL_ 2566871424 VCVCCU_V2G_EVSEPrsntCurnt_Flag 1 "True" 0 "False" ;
VAL_ 2566871424 V2G_EVSEPresentCurrent_Unit 1 "True" 0 "False" ;
VAL_ 2566871168 V2G_EVSEPeakCurrent_UnitFlag 1 "True" 0 "False" ;
VAL_ 2566871168 V2G_EVSEPeakCurrent_Unit 9 "WH" 8 "W_S" 7 "W" 6 "VA" 5 "V" 4 "HA" 3 "A" 2 "S" 1 "M" 0 "H" ;
VAL_ 2566870912 V2G_EVSEMinimumVoltage_UnitFlag 1 "True" 0 "False" ;
VAL_ 2566870912 V2G_EVSEMinVoltage_Unit 9 "WH" 8 "W_S" 7 "W" 6 "VA" 5 "V" 4 "HA" 3 "A" 2 "S" 1 "M" 0 "H" ;
VAL_ 2566870656 V2G_EVSEMinimumCurrent_Unit 9 "WH" 8 "W_S" 7 "W" 6 "VA" 5 "V" 4 "HA" 3 "A" 2 "S" 1 "M" 0 "H" ;
VAL_ 2566870656 V2G_EVSEMinCurrent_UnitFlag 1 "True" 0 "False" ;
VAL_ 2566870400 V2G_MaxVoltageLimit_UnitFlag 1 "True" 0 "False" ;
VAL_ 2566870400 V2G_EVSEMaxVoltageLimit_Flag 1 "True" 0 "False" ;
VAL_ 2566870400 V2G_EVSEMaximumVoltageLimit_Unit 9 "WH" 8 "W_S" 7 "W" 6 "VA" 5 "V" 4 "HA" 3 "A" 2 "S" 1 "M" 0 "H" ;
VAL_ 2566870144 V2G_EVSEMaxPowerLimit_UnitFlag 1 "True" 0 "False" ;
VAL_ 2566870144 V2G_EVSEMaximumPowerLimit_Flag 1 "True" 0 "False" ;
VAL_ 2566870144 V2G_MaxPowerLimit_Unit 9 "WH" 8 "W_S" 7 "W" 6 "VA" 5 "V" 4 "HA" 3 "A" 2 "S" 1 "M" 0 "H" ;
VAL_ 2566869888 V2G_MaxCurrentLimit_UnitFlag 1 "True" 0 "False" ;
VAL_ 2566869888 V2G_MaxCurrentLimit_Flag 1 "True" 0 "False" ;
VAL_ 2566869888 V2G_EVSEMaxCurrentLimitunit 9 "WH" 8 "W_S" 7 "W" 6 "VA" 5 "V" 4 "HA" 3 "A" 2 "S" 1 "M" 0 "H" ;
VAL_ 2566869632 V2G_EnergyToBeDeliver_unitFlag 1 "True" 0 "False" ;
VAL_ 2566869632 V2G_EnergyToBeDelivered_Flag 1 "True" 0 "False" ;
VAL_ 2566869632 V2G_EnergyToBeDelivered_unit 9 "WH" 8 "W_S" 7 "W" 6 "VA" 5 "V" 4 "HA" 3 "A" 2 "S" 1 "M" 0 "H" ;
VAL_ 2566869376 V2G_EVSECurrentTolrance_unitflag 1 "True" 0 "False" ;
VAL_ 2566869376 V2G_EVSECurrentTolerance_Flag 1 "True" 0 "False" ;
VAL_ 2566869376 V2G_EVSECurrentTolerance_unit 9 "WH" 8 "W_S" 7 "W" 6 "VA" 5 "V" 4 "HA" 3 "A" 2 "S" 1 "M" 0 "H" ;
VAL_ 2566853760 ChargeUnit_MaxCurrent 255 "SNA" 254 "Error" ;
VAL_ 2566853760 ChargeUnit_State 7 "SNA" 6 "EVSE State F" 5 "EVSE State E" 4 "EVSE State D" 3 "EVSE State C" 2 "EVSE State B2" 1 "EVSE state B1" 0 "EVSE state A" ;
VAL_ 2566853760 ChargeUnit_Mode 7 "sna" 6 "error" 5 "reserved" 4 "Charge Pantograph" 3 "Charging LIN" 2 "Charging Not allowed" 1 "Charge PWM" 0 "Charge V2G" ;
VAL_ 2566853760 ControlPilot_Wakeup 3 "sna" 2 "error" 1 "wakeup detected" 0 "wakeup not detected" ;
VAL_ 2566853760 ControlPilot_Voltage 65535 "SNA" 65534 "Error" ;
VAL_ 2566853760 ControlPilot_DutyCycle 255 "SNA" 254 "Error" ;
VAL_ 2566853760 ControlPilot_Frequency 65535 "SNA" 65534 "Error" ;
VAL_ 2566854528 E2E_State_ChargeFromVehicle 255 "Hard_run_time_error" 119 "Soft_run_time_error" 69 "Invalid_NND" 67 "Invalid_Error" 66 "Invalid_SEQ" 65 "Invalid_REP" 64 "Invalid_Ok" 53 "Init_NND" 51 "Init_error" 50 "Init_SEQ" 49 "Init_REP" 48 "Init_Ok" 37 "No_Data_NND" 35 "No_data_error" 34 "No_data_SEQ" 33 "No_data_REP" 32 "No_data_ok" 5 "valid NND" 3 "valid Error" 2 "valid SEQ" 1 "valid REP" 0 "valid ok" ;
VAL_ 2566854528 VCVCCU_Vehcle_MobilizatnStatus 3 "SNA" 2 "Vehicle immobile Fault" 1 "Vehicle Imobile" 0 "Vehicle mobile" ;
VAL_ 2566854528 VCVCCU_Vehicle_ChargingStatus 3 "SNA" 2 "reserved" 1 "start_charging" 0 "stop_charging" ;
VAL_ 2566854528 VCVCCU_Vehcle_ChageSelctnAck 3 "sna" 2 "error" 1 "secondary node" 0 "primary_node" ;
VAL_ 2566854528 Vehicle_IsolationMeasurementReq 3 "Description for the value '0x3'" 2 "reserved" 1 "requested" 0 "Not_requested" ;
VAL_ 2566854528 VCVCCU_Vehicle_ContactorRequest 3 "Description for the value '0x3'" 2 "force_open" 1 "close" 0 "open" ;
VAL_ 2566834816 DTC_SPN_ConvMd_VCCU 1 "Version 1,2 or  3" 0 "Version 4" ;
VAL_ 2566834816 DTC_OccCnt_VCCU 127 "SNA" ;
VAL_ 2566834816 DTC_MIL_Flash_Stat_VCCU 3 "SNA" 2 "Class C DTC" 1 "Fast Flash" 0 "Slow Flash" ;
VAL_ 2566834816 DTC_RSL_Flash_Stat_VCCU 3 "SNA" 2 "Reserved" 1 "Fast Flash" 0 "Slow Flash" ;
VAL_ 2566834816 DTC_AWL_Flash_Stat_VCCU 3 "SNA" 2 "Reserved" 1 "Fast Flash" 0 "Slow Flash" ;
VAL_ 2566834816 DTC_PL_Flash_Stat_VCCU 3 "SNA" 2 "Reserved" 1 "Fast Flash" 0 "Slow Flash" ;
VAL_ 2566834816 DTC_MIL_Stat_VCCU 3 "SNA" 2 "Short MIL for WWH OBD" 1 "ON" 0 "OFF" ;
VAL_ 2566834816 DTC_RSL_Stat_VCCU 3 "SNA" 2 "Reserved" 1 "ON" 0 "OFF" ;
VAL_ 2566834816 DTC_AWL_Stat_VCCU 3 "SNA" 2 "Reserved" 1 "ON" 0 "OFF" ;
VAL_ 2566834816 DTC_PL_Stat_VCCU 3 "SNA" 2 "Reserved" 1 "ON" 0 "OFF" ;
VAL_ 2566844817 Parking_Brake_Switch 2 "Error" 1 "Brake Set" 0 "Brake not Set" ;
VAL_ 2566844817 Brake_Switch 3 "Not available or not installed" 2 "Error" 1 "Brake Pedal Depressed" 0 "Brake Pedal Released" ;
VAL_ 2564882321 Seat_belt_switch 3 "Not available" 2 "Error" 1 "Buckled" 0 "Not Buckeld" ;
VAL_ 2565865808 ABSEBS_amberwarningsignal 3 "No action" 2 "Reserved" 1 "ON" 0 "OFF" ;
VAL_ 2565865808 Halt_brake_switch 3 "Not available" 2 "Error " 1 "Halt brake Active" 0 "Halt brake Passive" ;
VAL_ 2565865808 ABS_off_road_switch 3 "Not available" 2 "Error" 1 "ABS off road active" 0 "ABS off road Passive" ;
VAL_ 2565865808 ABS_Fully_operational 3 "Not available" 2 "Reserved" 1 "Fully operational" 0 "Not Fully operational" ;
VAL_ 2565865808 EBS_brake_switch 3 "SNA" 2 "Error" 1 "Brake pedal being pressed" 0 "BrakePedaisnot being Presssed" ;
VAL_ 2565865808 Antilock_braking_active 3 "Not Available" 2 "Reserved" 1 "ABS_Active" 0 "ABS passive but not active" ;
VAL_ 767 DUMMY_SIG_50 255 "Default Value" ;
VAL_ 767 DUMMY_SIG_40 255 "Default Value" ;
VAL_ 767 DUMMY_SIG_30 255 "Default Value" ;
VAL_ 767 DUMMY_SIG_20 255 "Default Value" ;
VAL_ 767 DUMMY_SIG_00 15 "Default Value" ;
VAL_ 767 AVL_PWR_HT_HVSTO_extended 4095 "Signal Invalid" ;
VAL_ 1415 INQY_ID_PWRCOS_FN_2 255 "Signal Invalid" 14 "HV-heating Battery pre-condition" 13 "Pre-condition Battery 'forced'" 12 "Pre-condition Battery" 11 "Pre-condition interior 'forced'" 10 "Pre-condition interior" 9 "HV Heating Battery Charging" 8 "Cooling Battery Urgent" 7 "Cooling Battery" 6 "Defrost" 5 "Condension" 4 "E-Cooling" 3 "Cool down" 2 "E-heating" 1 "heat up" 0 "not taken" ;
VAL_ 1415 INQY_PWR_LV_FN_2 255 "Signal Invalid" ;
VAL_ 1415 INQY_PWR_HV_FN_2 4095 "Signal Invalid" ;
VAL_ 1415 INQY_PWR_HV_FN_1 4095 "Signal Invalid" ;
VAL_ 1415 INQY_PWR_LV_FN_1 255 "Signal Invalid" ;
VAL_ 1415 INQY_ID_PWRCOS_FN_1 255 "Signal Invalid" 14 "HV-heating Battery pre-condition" 13 "Pre-condition Battery 'forced'" 12 "Pre-condition Battery" 11 "Pre-condition interior 'forced'" 10 "Pre-condition interior" 9 "HV Heating Battery Charging" 8 "Cooling Battery Urgent" 7 "Cooling Battery" 6 "Defrost" 5 "Condension" 4 "E-Cooling" 3 "Cool down" 2 "E-heating" 1 "heat up" 0 "not taken" ;
VAL_ 1415 ID2 255 "Signal Invalid" ;
VAL_ 1306 NM2_USR_DT_ACAN -2147483648 "Signal Invalid" ;
VAL_ 1306 NM2_AUTOSAR_RES_ACAN -2147483648 "Signal Invalid" ;
VAL_ 1434 ID2 255 "Signal Invalid" ;
VAL_ 1434 RLS_ID_PWRCOS_FN_2 255 "Signal Invalid" 14 "HV-heating Battery pre-condition" 13 "Pre-condition Battery 'forced'" 12 "Pre-condition Battery" 11 "Pre-condition interior 'forced'" 10 "Pre-condition interior" 9 "HV Heating Battery Charging" 8 "Cooling Battery Urgent" 7 "Cooling Battery" 6 "Defrost" 5 "Condension" 4 "E-Cooling" 3 "Cool down" 2 "E-heating" 1 "heat up" 0 "not taken" ;
VAL_ 1434 RLS_PWR_LV_FN_2 255 "Signal Invalid" ;
VAL_ 1434 RLS_PWR_HV_FN_2 4095 "Signal Invalid" ;
VAL_ 1434 RLS_PWR_HV_FN_1 4095 "Signal Invalid" ;
VAL_ 1434 RLS_PWR_LV_FN_1 255 "Signal Invalid" ;
VAL_ 1434 RLS_ID_PWRCOS_FN_1 255 "Signal Invalid" 14 "HV-heating Battery pre-condition" 13 "Pre-condition Battery 'forced'" 12 "Pre-condition Battery" 11 "Pre-condition interior 'forced'" 10 "Pre-condition interior" 9 "HV Heating Battery Charging" 8 "Cooling Battery Urgent" 7 "Cooling Battery" 6 "Defrost" 5 "Condension" 4 "E-Cooling" 3 "Cool down" 2 "E-heating" 1 "heat up" 0 "not taken" ;
VAL_ 928 DUMMY_SIG_00 255 "Default Value" ;
VAL_ 928 DUMMY_SIG_40 255 "Default Value" ;
VAL_ 928 DUMMY_SIG_60 255 "Default Value" ;
VAL_ 928 DUMMY_SIG_50 255 "Default Value" ;
VAL_ 928 DUMMY_SIG_30 255 "Default Value" ;
VAL_ 928 DUMMY_SIG_10 255 "Default Value" ;
VAL_ 928 DUMMY_SIG_72 63 "DefaultValue" ;
VAL_ 928 ST_ILK_ERRM_FZM 3 "Signal Invalid" 2 "Reserved" 1 "Fault Code blocked" 0 "Fault Code readiness" ;
VAL_ 928 ST_ENERG_FZM 15 "Signal Invalid" 3 "Enstate_severe_shortage" 2 "Enstate_Shortage" 1 "Enstate_Ok" 0 "Enstate_Good" ;
VAL_ 816 DUMMY_SIG_30 255 "Default Value" ;
VAL_ 816 DUMMY_SIG_70 255 "Default Value" ;
VAL_ 816 DUMMY_SIG_60 255 "Default Value" ;
VAL_ 816 DUMMY_SIG_50 255 "Default Value" ;
VAL_ 816 DUMMY_SIG_40 255 "Default Value" ;
VAL_ 816 MILE_KM 16777215 "Default value" ;
VAL_ 808 DUMMY_SIG_50 255 "Default Value" ;
VAL_ 808 DUMMY_SIG_40 255 "Default Value" ;
VAL_ 808 T_SEC_COU_REL -2147483648 "Signal Invalid" ;
VAL_ 714 DUMMY_SIG_10 255 "Default Value" ;
VAL_ 714 TEMP_EX 255 "Signal Invalid" ;
VAL_ 417 DUMMY_SIG_40 15 "Default Value" ;
VAL_ 417 DUMMY_SIG_10 255 "Default Value" ;
VAL_ 417 DUMMY_SIG_00 255 "Default Value" ;
VAL_ 417 V_VEH_COG 65535 "Signal Invalid" ;
VAL_ 414 DUMMY_SIG_60 255 "Default Value" ;
VAL_ 414 DUMMY_SIG_70 255 "Default Value" ;
VAL_ 414 CTR_FKTN_PRTNT_DRV -2147483648 "Signal invalid" ;
VAL_ 414 CTR_BS_PRTNT_DRV 65535 "Signal Invalid" ;
VAL_ 411 DUMMY_SIG_50 255 "Default Value" ;
VAL_ 411 DUMMY_SIG_70 255 "Default Value" ;
VAL_ 411 DUMMY_SIG_60 255 "Default Value" ;
VAL_ 411 DUMMY_SIG_42 63 "DefaultValue" ;
VAL_ 411 CTR_CLSY_CR 3 "signal invalid" 2 "open central locking" 1 "dont open central locking" ;
VAL_ 411 CTR_AUTOM_ECAL_CR 3 "Signal invalid" 2 "Init of emergency call" 1 "No init of auto emergency call" 0 "Reserved" ;
VAL_ 411 CTR_ITLi_CR 3 "Signal Invalid" 2 " Activate interior lightng" 1 "Do not Activate interior lightng" ;
VAL_ 411 CTR_SWO_EKP_CR 15 "Signal invalid" 10 " crash-deactivation of EKP" 5 "no crash-deactivation of EKP" ;
VAL_ 411 CTR_HAZW_CR 3 "signal invalid" 2 " switch on warning lights" 1 "Dont switch on warning lights" ;
VAL_ 411 CTR_PCSH_MST 63 "Signal Invalid" 0 "No Activation" ;
VAL_ 411 CTR_PHTR_CR 3 "Signal invalid" 2 "deactiv - independent heater" 1 "no deactiv- independent heater" ;
VAL_ 411 ST_EXCE_ACLN_THRV 3 "Sign invalid" 1 "Acc limit exceeded" 0 "Acc limit nt exceeded" ;
VAL_ 411 ALIV_CTR_CR 15 "Signal Invalid" ;
VAL_ 411 CRC_CTR_CR 255 "Signal Invalid" ;
VAL_ 303 DUMMY_SIG_34 15 "Default Value" ;
VAL_ 303 DUMMY_SIG_10 15 "Default Value" ;
VAL_ 303 DUMMY_SIG_70 255 "Default Value" ;
VAL_ 303 DUMMY_SIG_60 255 "Default Value" ;
VAL_ 303 DUMMY_SIG_50 255 "Default Value" ;
VAL_ 303 DUMMY_SIG_40 255 "Default Value" ;
VAL_ 303 DUMMY_SIG_24 15 "Default Value" ;
VAL_ 303 DUMMY_SIG_00 255 "Default Value" ;
VAL_ 303 ST_KL_30B 15 "Signal Invalid" 14 "Error " 13 "KL30 B duration On" 12 "Caster >10min " 11 "Caster >5min & <=10mins" 10 "Caster >1min & <=5mins" 9 "Caster >1=50s & <=1min" 8 "Caster >40s & <=50s" 7 "Caster >30s & <=40s" 6 "Caster >20s & <=30s" 5 "Caster >10s & <=20s" 4 "Caster >5s & <=10s" 3 "Caster >1s & <=5s" 2 "Caster >0s & <=1s" 1 "KL30 B OFF" 0 "Init Digit" ;
VAL_ 303 ST_KL 15 "Signal Invalid" 10 "KL15- On" 9 "KL15- Change" 6 "KL30 B- On" 5 "KL30 B- Change" ;
VAL_ 303 ST_VEH_CON 11 "Start Engine" 1 "Standby Driver absent" ;
VAL_ 267 DUMMY_SIG_24 15 "Default Value" ;
VAL_ 267 RQ_MEASMT_ISL_DC_CHGNG_CNA 3 "Signal Invalid" 1 "Active" 0 "Not Active" ;
VAL_ 267 ST_DCHG_LINK_2 3 "Signal Invalid" 1 "Active" 0 "Not Active" ;
VAL_ 267 DUMMY_SIG_16 3 "Default Value" ;
VAL_ 267 RQ_DCSW_HVSTO_CLO 3 "Signal Invalid" 1 "Active" 0 "Not Active" ;
VAL_ 267 ALIV_SPEC_DCSW_HVSTO 15 "Signal Invalid" ;
VAL_ 267 CRC_SPEC_DCSW_HVSTO 255 "Signal Invalid" ;
VAL_ 264 DUMMY_SIG_70 255 "Default Value" ;
VAL_ 264 DUMMY_SIG_60 255 "Default Value" ;
VAL_ 264 DUMMY_SIG_50 255 "Default Value" ;
VAL_ 264 DUMMY_SIG_46 3 "Default Value" ;
VAL_ 264 ST_AC_CHGNG_EPRG 2 "Signal Invalid" 1 "Activated" 0 "Deactivated" ;
VAL_ 264 DUMMY_SIG_40 15 "Default Value" ;
VAL_ 264 DUMMY_SIG_30 255 "Default Value" ;
VAL_ 264 DUMMY_SIG_20 255 "Default Value" ;
VAL_ 264 DUMMY_SIG_10 255 "Default Value" ;
VAL_ 264 DUMMY_SIG_00 255 "Default Value" ;
VAL_ 1075 DUMMY_SIG_00 255 "Default Value" ;
VAL_ 1075 DUMMY_SIG_30 255 "Default Value" ;
VAL_ 1075 RQ_EMMOD_HYB_HVSTO 15 "Signal Invalid" 0 "no reaction-standard operation" ;
VAL_ 1075 DUMMY_SIG_20 15 "Default Value" ;
VAL_ 1075 DUMMY_SIG_14 15 "Default Value" ;
VAL_ 1075 DUMMY_SIG_12 3 "Default Value" ;
VAL_ 1075 CTR_MEASMT_ISL 3 "Signal Invalid" 2 "Isolation measurement requested" 1 "No requirement" 0 "Isolation measurement turn off" ;
VAL_ 1001 DUMMY_SIG_70 255 "Default Value" ;
VAL_ 1001 DUMMY_SIG_60 255 "Default Value" ;
VAL_ 1001 DUMMY_SIG_50 255 "Default Value" ;
VAL_ 1001 FRC_PWR_CHGNG_extended 4095 "Signal Invalid" ;
VAL_ 1001 DUMMY_SIG_30 15 "Default Value" ;
VAL_ 1001 DUMMY_SIG_24 15 "Default Value" ;
VAL_ 1001 RQ_CHGRDI 2 "Char with depa time and cond" 1 "Plug & Charge (default)" 0 "no charging" ;
VAL_ 1001 DUMMY_SIG_10 255 "Default Value" ;
VAL_ 1001 DUMMY_SIG_00 255 "Default Value" ;
VAL_ 891 DUMMY_SIG_50 255 "Default Value" ;
VAL_ 891 DUMMY_SIG_40 255 "Default Value" ;
VAL_ 891 DUMMY_SIG_30 255 "Default Value" ;
VAL_ 891 DUMMY_SIG_20 255 "Default Value" ;
VAL_ 891 DUMMY_SIG_10 255 "Default Value" ;
VAL_ 891 ST_FRT_AC 3 "Signal Invalid" 1 "AC Switch ON" 0 "AC Switch OFF" ;
VAL_ 891 RQ_CSOV_HVSTO 3 "Signal Invalid" 2 "Power up with additional demand" 1 "Switch on" 0 "no Demand" ;
VAL_ 891 DUMMY_SIG_02 3 "Default Value" ;
VAL_ 891 RLS_COOL_HVSTO 3 "Signal Invalid" 2 "System error detected" 1 "release HV Storage cooling" 0 "no release" ;
VAL_ 1065 DUMMY_SIG_70 255 "Default Value" ;
VAL_ 1065 DUMMY_SIG_60 255 "Default Value" ;
VAL_ 1065 ST_HT_ACTV_HVSTO 65535 "Signal Invalid" 32768 "Init Value" ;
VAL_ 1065 ST_HVIL_HVSTO 65535 "Signal Invalid" 32768 "Init Value" ;
VAL_ 1065 ST_CSOV_OPN_HVSTO 65535 "Signal Invalid" 32768 "Init Value" ;
VAL_ 515 ERR_PARCON_HVSTO 255 "Signal Invalid" 254 "error 254" 253 "error 253" 252 "error 252" 251 "Description for the value '0xFB'" 250 "Description for the value '0xFA'" 249 "Description for the value '0xF9'" 248 "Description for the value '0xF8'" 247 "Description for the value '0xF7'" 246 "Description for the value '0xF6'" 245 "Description for the value '0xF5'" 244 "Description for the value '0xF4'" 243 "Description for the value '0xF3'" 242 "Description for the value '0xF2'" 241 "Description for the value '0xF1'" 240 "Description for the value '0xF0'" 239 "Description for the value '0xEF'" 238 "Description for the value '0xEE'" 237 "Description for the value '0xED'" 236 "Description for the value '0xEC'" 235 "Description for the value '0xEB'" 234 "Description for the value '0xEA'" 233 "Description for the value '0xE9'" 232 "Description for the value '0xE8'" 231 "Description for the value '0xE7'" 230 "Description for the value '0xE6'" 229 "Description for the value '0xE5'" 228 "Description for the value '0xE4'" 227 "Description for the value '0xE3'" 226 "Description for the value '0xE2'" 225 "Description for the value '0xE1'" 224 "Description for the value '0xE0'" 223 "Description for the value '0xDF'" 222 "Description for the value '0xDE'" 221 "Description for the value '0xDD'" 220 "Description for the value '0xDC'" 219 "Description for the value '0xDB'" 218 "Description for the value '0xDA'" 217 "Description for the value '0xD9'" 216 "Description for the value '0xD8'" 215 "Description for the value '0xD7'" 214 "Description for the value '0xD6'" 213 "Description for the value '0xD5'" 212 "Description for the value '0xD4'" 211 "Description for the value '0xD3'" 210 "Description for the value '0xD2'" 209 "Description for the value '0xD1'" 208 "Description for the value '0xD0'" 207 "Description for the value '0xCF'" 206 "Description for the value '0xCE'" 205 "Description for the value '0xCD'" 204 "Description for the value '0xCC'" 203 "Description for the value '0xCB'" 202 "Description for the value '0xCA'" 201 "Description for the value '0xC9'" 200 "Description for the value '0xC8'" 199 "Description for the value '0xC7'" 198 "Description for the value '0xC6'" 197 "Description for the value '0xC5'" 196 "Description for the value '0xC4'" 195 "Description for the value '0xC3'" 194 "Description for the value '0xC2'" 193 "Description for the value '0xC1'" 192 "Description for the value '0xC0'" 191 "Description for the value '0xBF'" 190 "Description for the value '0xBE'" 189 "Description for the value '0xBD'" 188 "Description for the value '0xBC'" 187 "Description for the value '0xBB'" 186 "Description for the value '0xBA'" 185 "Description for the value '0xB9'" 184 "Description for the value '0xB8'" 183 "Description for the value '0xB7'" 182 "Description for the value '0xB6'" 181 "Description for the value '0xB5'" 180 "Description for the value '0xB4'" 179 "Description for the value '0xB3'" 178 "Description for the value '0xB2'" 177 "Description for the value '0xB1'" 176 "Description for the value '0xB0'" 175 "Description for the value '0xAF'" 174 "Description for the value '0xAE'" 173 "Description for the value '0xAD'" 172 "Description for the value '0xAC'" 171 "Description for the value '0xAB'" 170 "Description for the value '0xAA'" 169 "Description for the value '0xA9'" 168 "Description for the value '0xA8'" 167 "Description for the value '0xA7'" 166 "Description for the value '0xA6'" 165 "Description for the value '0xA5'" 164 "Description for the value '0xA4'" 163 "Description for the value '0xA3'" 162 "Description for the value '0xA2'" 161 "Description for the value '0xA1'" 160 "Description for the value '0xA0'" 159 "Description for the value '0x9F'" 158 "Description for the value '0x9E'" 157 "Description for the value '0x9D'" 156 "Description for the value '0x9C'" 155 "Description for the value '0x9B'" 154 "Description for the value '0x9A'" 153 "Description for the value '0x99'" 152 "Description for the value '0x98'" 151 "Description for the value '0x97'" 150 "Description for the value '0x96'" 149 "Description for the value '0x95'" 148 "Description for the value '0x94'" 147 "Description for the value '0x93'" 146 "Description for the value '0x92'" 145 "Description for the value '0x91'" 144 "Description for the value '0x90'" 143 "Description for the value '0x8F'" 142 "Description for the value '0x8E'" 141 "Description for the value '0x8D'" 140 "Description for the value '0x8C'" 139 "Description for the value '0x8B'" 138 "Description for the value '0x8A'" 137 "Description for the value '0x89'" 136 "Description for the value '0x88'" 135 "Description for the value '0x87'" 134 "Description for the value '0x86'" 133 "Description for the value '0x85'" 132 "Description for the value '0x84'" 131 "Description for the value '0x83'" 130 "Description for the value '0x82'" 129 "Description for the value '0x81'" 128 "Description for the value '0x80'" 127 "Description for the value '0x7F'" 126 "Description for the value '0x7E'" 125 "Description for the value '0x7D'" 124 "Description for the value '0x7C'" 123 "Description for the value '0x7B'" 122 "Description for the value '0x7A'" 121 "Description for the value '0x79'" 120 "Description for the value '0x78'" 119 "Description for the value '0x77'" 118 "Description for the value '0x76'" 117 "Description for the value '0x75'" 116 "Description for the value '0x74'" 115 "Description for the value '0x73'" 114 "Description for the value '0x72'" 113 "Description for the value '0x71'" 112 "Description for the value '0x70'" 111 "Description for the value '0x6F'" 110 "Description for the value '0x6E'" 109 "Description for the value '0x6D'" 108 "Description for the value '0x6C'" 107 "Description for the value '0x6B'" 106 "Description for the value '0x6A'" 105 "Description for the value '0x69'" 104 "Description for the value '0x68'" 103 "Description for the value '0x67'" 102 "Description for the value '0x66'" 101 "Description for the value '0x65'" 100 "Description for the value '0x64'" 99 "Description for the value '0x63'" 98 "Description for the value '0x62'" 97 "Description for the value '0x61'" 96 "Description for the value '0x60'" 95 "Description for the value '0x5F'" 94 "Description for the value '0x5E'" 93 "Description for the value '0x5D'" 92 "Description for the value '0x5C'" 91 "Description for the value '0x5B'" 90 "Description for the value '0x5A'" 89 "Description for the value '0x59'" 88 "Description for the value '0x58'" 87 "Description for the value '0x57'" 86 "Description for the value '0x56'" 85 "Description for the value '0x55'" 84 "Description for the value '0x54'" 83 "Description for the value '0x53'" 82 "Description for the value '0x52'" 81 "Description for the value '0x51'" 80 "Description for the value '0x50'" 79 "Description for the value '0x4F'" 78 "Description for the value '0x4E'" 77 "Description for the value '0x4D'" 76 "Description for the value '0x4C'" 75 "Description for the value '0x4B'" 74 "Description for the value '0x4A'" 73 "Description for the value '0x49'" 72 "Description for the value '0x48'" 71 "Description for the value '0x47'" 70 "Description for the value '0x46'" 69 "Description for the value '0x45'" 68 "Description for the value '0x44'" 67 "Description for the value '0x43'" 66 "Description for the value '0x42'" 65 "Description for the value '0x41'" 64 "Description for the value '0x40'" 63 "Description for the value '0x3F'" 62 "Description for the value '0x3E'" 61 "Description for the value '0x3D'" 60 "Description for the value '0x3C'" 59 "Description for the value '0x3B'" 58 "Description for the value '0x3A'" 57 "Description for the value '0x39'" 56 "Description for the value '0x38'" 55 "Description for the value '0x37'" 54 "Description for the value '0x36'" 53 "Description for the value '0x35'" 52 "Description for the value '0x34'" 51 "Description for the value '0x33'" 50 "Description for the value '0x32'" 49 "Description for the value '0x31'" 48 "Description for the value '0x30'" 47 "Description for the value '0x2F'" 46 "Description for the value '0x2E'" 45 "Description for the value '0x2D'" 44 "Description for the value '0x2C'" 43 "Description for the value '0x2B'" 42 "Description for the value '0x2A'" 41 "Description for the value '0x29'" 40 "Description for the value '0x28'" 39 "Description for the value '0x27'" 38 "Description for the value '0x26'" 37 "Description for the value '0x25'" 36 "Error  '0x24'" 35 "Error  '0x23'" 34 "Error  '0x22'" 33 "Error  '0x21'" 32 "Error  '0x20'" 31 "Error  '0x1F'" 30 "Error  '0x1E'" 29 "Error  '0x1D'" 28 "Error  '0x1C'" 27 "Error  '0x1B'" 26 "Error  '0x1A'" 25 "Error  '0x19'" 24 "Error  '0x18'" 23 "Error  '0x17'" 22 "Error  '0x16'" 21 "Error  '0x15'" 20 "Error  '0x14'" 19 "Error  '0x13'" 18 "Error  '0x12'" 17 "Error  '0x11'" 16 "Error '0x10'" 15 "Error F'" 14 "Error E'" 13 "Error D'" 12 "Error C'" 11 "Error B'" 10 "Error A'" 9 "Error 9'" 8 "Error 8'" 7 "Error 7'" 6 "Error 6'" 5 "Error 5'" 4 "Error 4'" 3 "Error 3'" 2 "Error'0x2'" 1 "Balacing Currents between packs" 0 "no erroe" ;
VAL_ 515 ST_SWON_HVSTO 65535 "Signal Invalid" 32768 "Init Value" ;
VAL_ 515 ST_COMM_HVSTO 65535 "Signal Invalid" 32768 "Init Value" ;
VAL_ 515 QUAN_HVSTO_AVLB 15 "Signal Invalid" ;
VAL_ 515 ALIV_ST_MST_BMC 15 "Signal Invalid" ;
VAL_ 515 CRC_ST_MST_BMC 255 "Signal Invalid" ;
VAL_ 1287 NM2_USR_DT_ACAN -2147483648 "Signal Invalid" ;
VAL_ 1287 NM2_AUTOSAR_RES_ACAN -2147483648 "Signal Invalid" ;
VAL_ 757 I_DYN_MAX_DCHG_HVSTO_extended 65535 "Signal Invalid" ;
VAL_ 757 U_MIN_DCHG_HVSTO 65535 "Signal Invalid" ;
VAL_ 757 I_DYN_MAX_CHG_HVSTO_extended 65535 "Signal Invalid" ;
VAL_ 757 U_MAX_CHG_HVSTO 65535 "Signal Invalid" ;
VAL_ 569 DUMMY_SIG_70 255 "Default Value" ;
VAL_ 569 DUMMY_SIG_60 255 "Default Value" ;
VAL_ 569 AVL_ISRE 255 "Signal_unfilled" 254 "Function_reports_error" 253 "Fun_interface_not_available" ;
VAL_ 569 PRD_ENERG_CHGTAR_2_HVSTO 65535 "signal_unfilled" 65534 "reserved_Error" 65533 "reserved_not_available" ;
VAL_ 569 PRD_ENERG_CHGCOND_2_COS_extended 65535 "Signal Invalid" ;
VAL_ 569 MUX_DT_HVSTO_2 15 "Signal Invalid" 8 "Eco Pro+" 7 "Eco Pro" 5 "Sport+" 4 "Sport" 3 "Comfort" ;
VAL_ 569 SYNCN_DT_HVSTO_2 15 "Signal Invalid" ;
VAL_ 274 AVL_U_LINK 255 "Signal Invalid" ;
VAL_ 274 CHGCOND_HVSTO_DELTA 15 "Signal Invalid" 14 "Reserved" 13 "Reserved" ;
VAL_ 274 RQ_OPN_DCSW_HVSTO_FAST 3 "Signal Invalid" 2 "Active" 1 "Not Active" 0 "No statement possible" ;
VAL_ 274 RQ_OPN_DCSW_HVSTO_ILY 3 "Signal Invalid" 2 "Active" 1 "Not Active" 0 "No statement possible" ;
VAL_ 274 RQ_OPC_CHG_HVSTO 3 "Signal Invalid" 2 "Active" 1 "Not Active" 0 "No statement possible" ;
VAL_ 274 DUMMY_SIG_54 3 "Default Value" ;
VAL_ 274 CHGCOND_HVSTO 4095 "Signal Invalid" ;
VAL_ 274 AVL_U_HVSTO 65535 "Signal Invalid" ;
VAL_ 274 AVL_I_HVSTO_extended 65535 "Signal Invalid" ;
VAL_ 1073 PRD_T_PRECOND_HVSTO 255 "Signal Invalid" ;
VAL_ 1073 DUMMY_SIG_64 15 "Signal Invalid" ;
VAL_ 1073 ENC_HVSTO_MAX_extended 4095 "Signal Invalid" ;
VAL_ 1073 DUMMY_SIG_40 255 "Signal Invalid" ;
VAL_ 1073 PRD_DUR_CHGNG 65535 "signal_unfilled" 65534 "reserved_Error" 65533 "reserved_not_available" ;
VAL_ 1073 DUMMY_SIG_10 255 "Signal Invalid" ;
VAL_ 1073 DUMMY_SIG_06 3 "Default Value" ;
VAL_ 1073 RQ_ABRT_CHGNG 3 "Signal Invalid" 2 "No charging possible" 1 "Request to interrupt charging" 0 "No request" ;
VAL_ 1073 ST_MEASMT_ISL 3 "Signal Invalid" 2 "Iso measurement  running" 1 "Iso measurement not running" ;
VAL_ 1073 ST_SER_DSCO_PLG 3 "Signal Invalid" 2 "Service Disconnector Connected" 1 "Service Disconnector Open" ;
VAL_ 1052 DUMMY_SIG_12 63 "DefaultValue" ;
VAL_ 1052 ST_COOL_HVSTO 3 "Signal Invalid" 2 "Active" 1 "Not Active" 0 "No statement possible" ;
VAL_ 1052 DUMMY_SIG_00 255 "Default Value" ;
VAL_ 1037 AVLB_PWR_LT_DCHG_HVSTO_extended 65535 "signal_unfilled" 65534 "reserved_Error" 65533 "reserved_not_available" ;
VAL_ 1037 AVLB_PWR_LT_CHG_HVSTO_extended 65535 "signal_unfilled" 65534 "reserved_Error" 65533 "reserved_not_available" ;
VAL_ 1037 AVLB_PWR_SRT_DCHG_HVSTO_extended 65535 "signal_unfilled" 65534 "reserved_Error" 65533 "reserved_not_available" ;
VAL_ 1037 AVLB_PWR_SRT_CHG_HVSTO_extended 65535 "signal_unfilled" 65534 "reserved_Error" 65533 "reserved_not_available" ;
VAL_ 1074 ST_STOR_AIC_COOL_RQMT_extended 255 "Signal_unfilled" 254 "Function_reports_error" 253 "Fun_interface_not_available" ;
VAL_ 1074 RQ_CHGCOND_HVSTO_MIN 255 "Signal Invalid" ;
VAL_ 1074 RQ_CHGCOND_HVSTO_MAX 255 "Signal Invalid" ;
VAL_ 1074 Dummy_SIG_70 255 "Default Value" ;
VAL_ 1074 Dummy_SIG_50 255 "Default Value" ;
VAL_ 1074 DISP_AVL_CHGCOND_HVSTO 255 "Signal Invalid" ;
VAL_ 1074 DUMMY_SIG_10 255 "Default Value" ;
VAL_ 1074 DUMMY_SIG_00 255 "Default Value" ;
VAL_ 506 ERR_EMMOD_HVSTO 3 "Signal Invalid" 2 "Active" 1 "Not Active" 0 "No statement possible" ;
VAL_ 506 AVL_TEMP_HVSTO_MAX 255 "Signal_Unfilled" 254 "Reserved" 253 "Reserved" ;
VAL_ 506 AVL_TEMP_HVSTO_MIN 255 "Signal_Unfilled" 254 "Reserved" 253 "Reserved" ;
VAL_ 506 AVL_TEMP_HTEX_HVSTO 255 "Signal Invalid" ;
VAL_ 506 AVL_TEMP_HVSTO 255 "Signal Invalid" ;
VAL_ 506 ST_WARN_OTMP_HVSTO 3 "Signal Invalid" 2 "Active" 1 "Not Active" 0 "No statement possible" ;
VAL_ 506 DUMMY_SIG_34 3 "Default Value" ;
VAL_ 506 ST_CSOV_HVSTO_COLERR 15 "Signal Invalid" 13 "Cooling Valve Error " 0 "Ok" ;
VAL_ 506 ST_WARN_ISL_BN_HV 3 "Signal Invalid" 2 "Active" 1 "Not Active" 0 "No statement possible" ;
VAL_ 506 ST_ERR_DCSW_HVSTO 3 "Signal Invalid" 2 "two switch contact sticks" 1 "one switch contact sticks" 0 "no switch contact sticks" ;
VAL_ 506 RQ_SER_HVSTO 3 "Signal Invalid" 2 "Active" 1 "Not Active" 0 "No statement possible" ;
VAL_ 506 ST_EMMOD_HVSTO 3 "Signal Invalid" 2 "Active" 1 "Not Active" 0 "No statement possible" ;
VAL_ 506 ST_DCSW_HVSTO 3 "signal invalid" 2 "breaker closed" 1 "breaker on pre-charging" 0 "breaker open" ;
VAL_ 506 ST_PRCHRG_LOKD_HVSTO 3 "Signal Invalid" 2 "Active" 1 "Not Active" 0 "No statement possible" ;
VAL_ 506 ST_ERR_LOKG_HVSTO 3 "Signal Invalid" 2 "Active" 1 "Not Active" 0 "No statement possible" ;
VAL_ 506 ST_VA_COOL_HVSTO 3 "Signal Invalid" 2 "Active" 1 "Not Active" 0 "No statement possible" ;
VAL_ 506 RQ_COOL_HVSTO 3 "Signal Invalid" 2 "Cooling required urgently" 1 "Cooling Demanded" ;
VAL_ 506 ST_ERR_ISL_INTL_BN_H 3 "Signal Invalid" 2 "Active" 1 "Not Active" 0 "No statement possible" ;
VAL_ 506 ST_ERR_ISL_EXTN_BN_HV 3 "Signal Invalid" 2 "Active" 1 "Not Active" 0 "No statement possible" ;
VAL_ 2297364226 Current_transmission_mode 3 "Forward Low" 2 "Forward Automatic" 1 "Reverse" 0 "Neutral" ;
VAL_ 2297364226 Selected_Gear 3 "Shift in Progress" 2 "High" 1 "Low" 0 "Neutral" ;
VAL_ 2297364226 Upshift_in_progress 1 "High gear Shift is in progress" 0 "High Shift is not in progress" ;
VAL_ 2297364226 Downshift_In_Progress 1 "High gear Shift is in progress" 0 "High Shift is not in progress" ;
VAL_ 2297364226 Upshift_Failed 1 "shift to High gear failed" 0 "shift to High gear successful" ;
VAL_ 2297364226 Slow_Upshift 1 "Shift require more amnt of time" 0 "Shift in a normal amount of time" ;
VAL_ 2297364226 Slow_Downshift 1 "Shift require more amnt of time" 0 "Shift in a normal amount of time" ;
VAL_ 2297364226 Shift_Disabled 1 "Gear shift disabled" 0 "Gear shift not disabled" ;
VAL_ 2297364226 Max_Shift_Speed_Delta_Exceeded 1 "Gear shift disabled" 0 "Gear shift not disabled" ;
VAL_ 2297364226 Air_Pressure_Out_of_Range 1 "solenoids is out of range" 0 "solenoids is in normal range" ;
VAL_ 2297364226 Forced_Gear_Engagement_Torque 1 "TCU imposing min torque reqt" 0 "TCU not imposing min torque reqt" ;
VAL_ 2230255362 MCU_System_Type 15 "Undefined" 14 "Undefined" 13 "Undefined" 12 "Undefined" 11 "Undefined" 10 "Undefined" 9 "Undefined" 8 "Undefined" 7 "EM-PMI318B-T360-465V" 6 "Undefined" 5 "EM-PMI318B-T520E-465V" 4 "EM-PMI318B-T440E-255V" 3 "EM-PMI318-T400-255V" 2 "EM-PMI318-T360-425V" 1 "EM-PMI318-T350-255V" 0 "UnKnown" ;
VAL_ 2565865296 LED_secondary_colour 9 "Yellow / Green  " 8 "Amber / Orange" 7 "White / Light blue " 6 "Magneta" 5 "Cyan" 4 "Yellow" 3 "Blue" 2 "Green" 1 "Red" 0 "Off" ;
VAL_ 2565865296 LED_state 3 "Description for the value '0x3'" 2 "Off" 1 "On" 0 "Off" ;
VAL_ 2565865296 LED_colour 9 "Yellow / Green  " 8 "Amber / Orange" 7 "White / Light blue " 6 "Magneta" 5 "Cyan" 4 "Yellow" 3 "Blue" 2 "Green" 1 "Red" 0 "Off" ;
VAL_ 2565865296 PKP_key_number 3 "Key 4" 2 "Key 3" 1 "Key 2" 0 "Key 1" ;
VAL_ 2565865361 Contact_state 1 "Pressed" 0 "Released" ;
VAL_ 2566869221 OBC_Temperature_Fault 1 "Fault" 0 "Normal" ;
VAL_ 2566869221 OBC_Input_Voltage_Fault 1 "Fault" 0 "Normal" ;
VAL_ 2566869221 OBC_Hardware 1 "Fault" 0 "Normal" ;
VAL_ 2566869221 OBC_Charger_ready 1 "Fault" 0 "Normal" ;
VAL_ 2566869221 OBC_CAN 1 "Fault" 0 "Normal" ;
VAL_ 2550595408 D_OBC_Mode 1 "Heating" 0 "Battery" ;
VAL_ 2550595408 D_OBC_Charging_state 2 "Charging complete" 1 "Bat prote,charger turn off op" 0 "The charger starts charging " ;
VAL_ 2147549040 D_DCDC_working_status 1 "Stop" 0 "Work" ;
VAL_ 2147549040 D_DCDC_Fault 32768 "Reserve" 16384 "Reserve" 8192 "Reserve" 4096 "Reserve" 2048 "Reserve" 1024 "Reserve" 512 "Reserve" 256 "Communication fault alarm" 128 "Internal fault alarm " 64 "Output shortcircuit protection " 32 "Input under voltage alarm " 16 "Input over-voltage alarm" 8 "Output undervoltage alarm" 4 "Output over-voltage alarm" 2 "Output over-current alarm" 1 "Over temperature shutdown" ;
VAL_ 2551250768 D_DCDC_Switch_on_off_control 1 "Shutdown" 0 "Power on" ;
